VERSION ""

NS_ :

BS_:

BU_: ECM

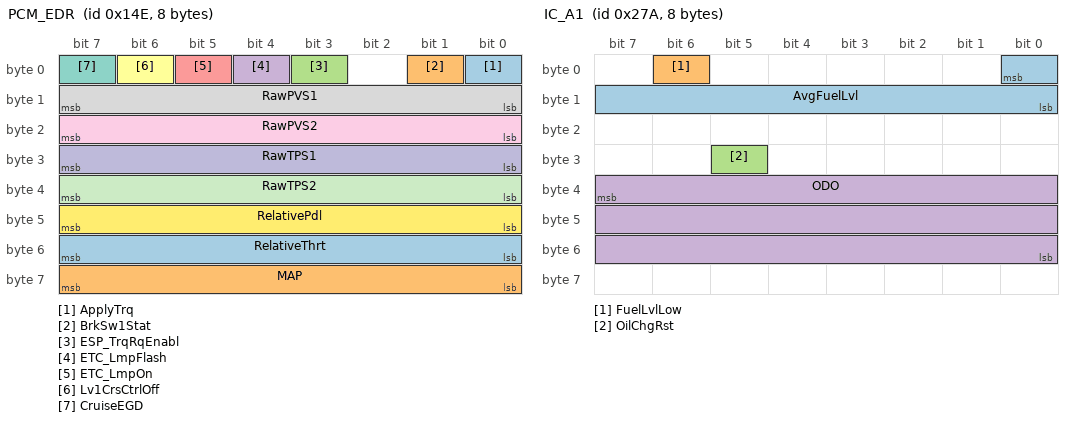
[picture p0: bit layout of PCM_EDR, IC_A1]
BO_ 334 PCM_EDR: 8 ECM
 SG_ ApplyTrq : 0|1@1+ (1,0) [0|0] "" Vector__XXX
 SG_ BrkSw1Stat : 1|1@1+ (1,0) [0|0] "" Vector__XXX
 SG_ ESP_TrqRqEnabl : 3|1@1+ (1,0) [0|0] "" Vector__XXX
 SG_ ETC_LmpFlash : 4|1@1+ (1,0) [0|0] "" Vector__XXX
 SG_ ETC_LmpOn : 5|1@1+ (1,0) [0|0] "" Vector__XXX
 SG_ Lv1CrsCtrlOff : 6|1@1+ (1,0) [0|0] "" Vector__XXX
 SG_ CruiseEGD : 7|1@1+ (1,0) [0|0] "" Vector__XXX
 SG_ RawPVS1 : 8|8@1+ (0.019607843,0) [0|4.98] "Volts"  Vector__XXX
 SG_ RawPVS2 : 16|8@1+ (0.019607843,0) [0|4.98] "Volts"  Vector__XXX
 SG_ RawTPS1 : 24|8@1+ (0.019607843,0) [0|4.98] "Volts"  Vector__XXX
 SG_ RawTPS2 : 32|8@1+ (0.019607843,0) [0|4.98] "Volts"  Vector__XXX
 SG_ RelativePdl : 40|8@1+ (0.019607843,0) [0|4.98] "Volts"  Vector__XXX
 SG_ RelativeThrt : 48|8@1+ (0.019607843,0) [0|4.98] "Volts"  Vector__XXX
 SG_ MAP : 56|8@1+ (0.8,0) [0|203.2] "kPa"  Vector__XXX

BO_ 43 ORC_YRS_DATA: 8 Vector__XXX
 SG_ LatAcceleration : 3|12@0+ (0.02,-40.96) [-40.96|40.92] "m/s²"  ECM
 SG_ LongAcceleration : 19|12@0+ (0.02,-40.96) [-40.96|40.92] "m/s²"  ECM

BO_ 673 IC_A3: 8 Vector__XXX
 SG_ SpeedUnit : 51|1@1+ (1,0) [0|0] "" ECM

BO_ 634 IC_A1: 8 Vector__XXX
 SG_ AvgFuelLvl : 0|9@0+ (0.5,0) [0|255] "liters"  ECM
 SG_ FuelLvlLow : 6|1@1+ (1,0) [0|0] "" ECM
 SG_ OilChgRst : 29|1@1+ (1,0) [0|0] "" ECM
 SG_ ODO : 39|24@0+ (0.1,0) [0|1677721.4] "km"  ECM

BO_ 503 IC_500Cyc: 8 Vector__XXX
 SG_ xtended_AvgFuelLvl : 19|12@0+ (0.5,0) [0|2047] "liters"  ECM

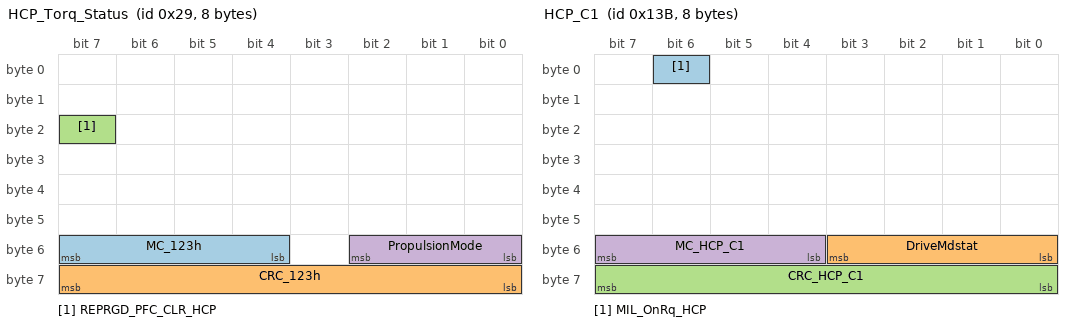
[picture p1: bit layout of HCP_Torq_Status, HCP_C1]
BO_ 41 HCP_Torq_Status: 8 Vector__XXX
 SG_ MC_123h : 52|4@1+ (1,0) [0|15] "" ECM
 SG_ CRC_123h : 56|8@1+ (1,0) [0|255] "" ECM
 SG_ REPRGD_PFC_CLR_HCP : 23|1@1+ (1,0) [0|0] "" ECM
 SG_ PropulsionMode : 48|3@1+ (1,0) [0|0] "" ECM

BO_ 315 HCP_C1: 8 Vector__XXX
 SG_ MIL_OnRq_HCP : 6|1@1+ (1,0) [0|0] "" ECM
 SG_ DriveMdstat : 48|4@1+ (1,0) [0|0] "" ECM
 SG_ CRC_HCP_C1 : 56|8@1+ (1,0) [0|0] "" ECM
 SG_ MC_HCP_C1 : 52|4@1+ (1,0) [0|15] "" ECM

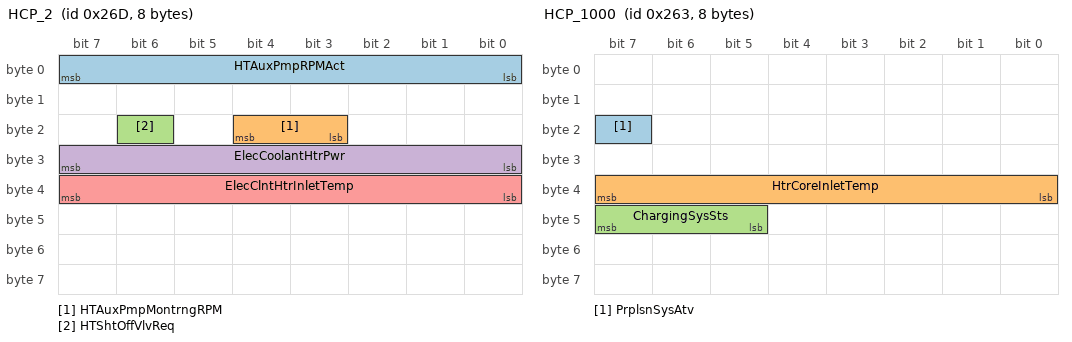
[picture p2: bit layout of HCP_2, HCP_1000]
BO_ 621 HCP_2: 8 Vector__XXX
 SG_ HTAuxPmpRPMAct : 0|8@1+ (24,0) [0|6096] "rpm"  ECM
 SG_ HTAuxPmpMontrngRPM : 19|2@1+ (1,0) [0|0] "" ECM
 SG_ HTShtOffVlvReq : 22|1@1+ (1,0) [0|0] "" ECM
 SG_ ElecCoolantHtrPwr : 24|8@1+ (0.04,0) [0|10.16] "kW"  ECM
 SG_ ElecClntHtrInletTemp : 32|8@1+ (1,-40) [-40|214] "°C"  ECM

BO_ 611 HCP_1000: 8 Vector__XXX
 SG_ PrplsnSysAtv : 23|1@1+ (1,0) [0|0] "" ECM
 SG_ HtrCoreInletTemp : 32|8@1+ (1,-40) [-40|214] "°C"  ECM
 SG_ ChargingSysSts : 45|3@1+ (1,0) [0|0] "" ECM

BO_ 663 GW_LIN_I_C1: 8 Vector__XXX
 SG_ SpSt_Pad1 : 50|3@1+ (1,0) [0|0] "" ECM
 SG_ SpSt_Pad2 : 53|3@1+ (1,0) [0|0] "" ECM

BO_ 649 GW_I_C1: 8 Vector__XXX
 SG_ HVAC_CLNT_FLW_MIN : 40|8@1+ (0.521555,0) [0.521555|131.953415] "LpM"  ECM

BO_ 689 GW_Dev: 5 Vector__XXX
 SG_ FT_HVAC_BLW_FN_SP : 0|7@1+ (1,0) [0|100] "Bars"  ECM
 SG_ DRV_TEMP_DR_POS : 16|7@1+ (1,0) [0|100] "%"  ECM

BO_ 327 ESP_B2: 8 Vector__XXX
 SG_ MIL_OnRq_ESC : 2|1@1+ (1,0) [0|0] "" ECM

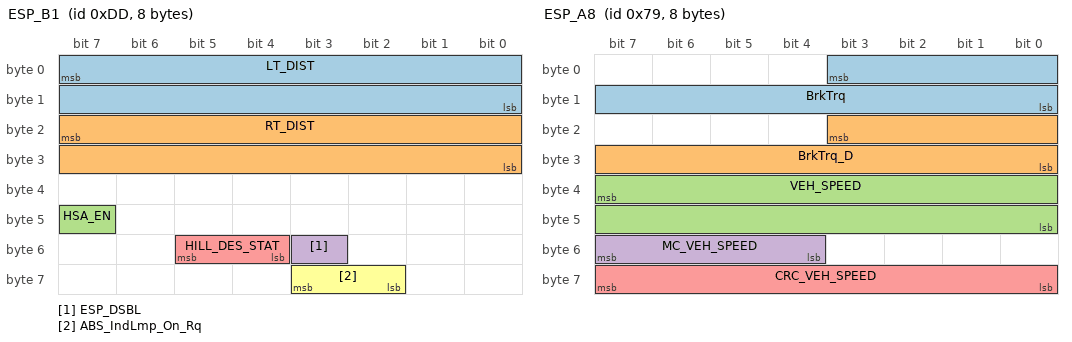
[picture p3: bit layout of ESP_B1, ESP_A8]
BO_ 221 ESP_B1: 8 Vector__XXX
 SG_ LT_DIST : 7|16@0+ (4,0) [0|262136] "cm"  ECM
 SG_ RT_DIST : 23|16@0+ (4,0) [0|262136] "cm"  ECM
 SG_ HSA_EN : 47|1@1+ (1,0) [0|0] "" ECM
 SG_ ESP_DSBL : 51|1@1+ (1,0) [0|0] "" ECM
 SG_ HILL_DES_STAT : 52|2@1+ (1,0) [0|0] "" ECM
 SG_ ABS_IndLmp_On_Rq : 58|2@1+ (1,0) [0|0] "" ECM

BO_ 121 ESP_A8: 8 Vector__XXX
 SG_ BrkTrq : 3|12@0+ (3,0) [0|12282] "Nm"  ECM
 SG_ BrkTrq_D : 19|12@0+ (3,0) [0|12282] "Nm"  ECM
 SG_ VEH_SPEED : 39|16@0+ (0.0078125,0) [0|511.984375] "km/h"  ECM
 SG_ MC_VEH_SPEED : 52|4@1+ (1,0) [0|15] "" ECM
 SG_ CRC_VEH_SPEED : 56|8@1+ (1,0) [0|0] "" ECM

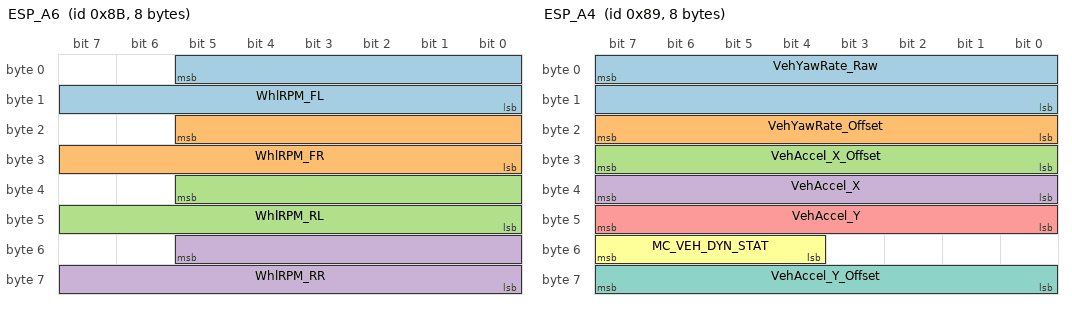
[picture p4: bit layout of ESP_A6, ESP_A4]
BO_ 139 ESP_A6: 8 Vector__XXX
 SG_ WhlRPM_FL : 5|14@0+ (0.5,0) [0|8191] "rpm"  ECM
 SG_ WhlRPM_FR : 21|14@0+ (0.5,0) [0|8191] "rpm"  ECM
 SG_ WhlRPM_RL : 37|14@0+ (0.5,0) [0|8191] "rpm"  ECM
 SG_ WhlRPM_RR : 53|14@0+ (0.5,0) [0|8191] "rpm"  ECM

BO_ 137 ESP_A4: 8 Vector__XXX
 SG_ VehYawRate_Raw : 7|16@0+ (0.01,-327.68) [-327.68|327.66] "°/s"  ECM
 SG_ VehYawRate_Offset : 16|8@1+ (0.08,-10.24) [-6.96|6.96] "" ECM
 SG_ VehAccel_X_Offset : 24|8@1+ (0.02,-2.56) [-2.56|2.52] "m/s²"  ECM
 SG_ VehAccel_X : 32|8@1+ (0.08,-10.24) [-10.24|10.08] "m/s²"  ECM
 SG_ VehAccel_Y : 40|8@1+ (0.08,-10.24) [-10.24|10.08] "m/s²"  ECM
 SG_ MC_VEH_DYN_STAT : 52|4@1+ (1,0) [0|15] "" ECM
 SG_ VehAccel_Y_Offset : 56|8@1+ (0.02,-2.56) [-2.56|2.52] "m/s²"  ECM

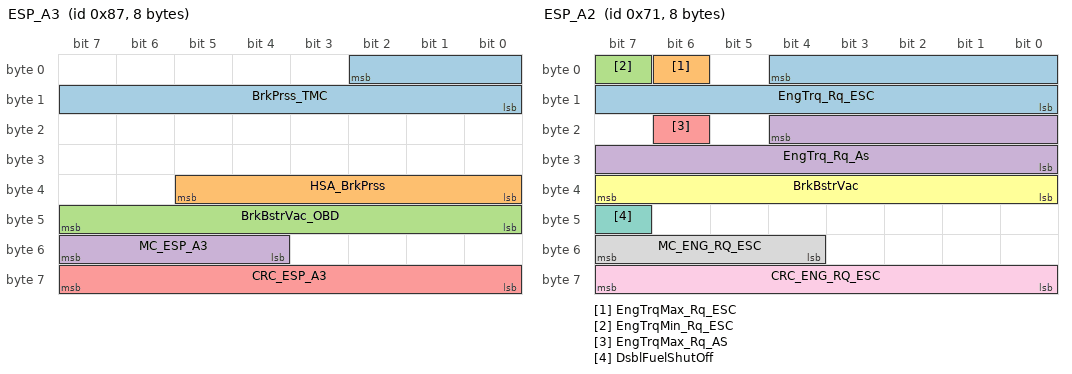
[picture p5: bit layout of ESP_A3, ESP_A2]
BO_ 135 ESP_A3: 8 Vector__XXX
 SG_ BrkPrss_TMC : 2|11@0+ (0.1,0) [0|200] "bar"  ECM
 SG_ HSA_BrkPrss : 32|6@1+ (1,0) [0|50] "bar"  ECM
 SG_ BrkBstrVac_OBD : 40|8@1+ (0.019607843,0) [0|5] "Volts"  ECM
 SG_ MC_ESP_A3 : 52|4@1+ (1,0) [0|15] "" ECM
 SG_ CRC_ESP_A3 : 56|8@1+ (1,0) [0|0] "" ECM

BO_ 113 ESP_A2: 8 Vector__XXX
 SG_ EngTrq_Rq_ESC : 4|13@0+ (0.25,-500) [-500|1547.5] "Nm"  ECM
 SG_ EngTrqMax_Rq_ESC : 6|1@1+ (1,0) [0|0] "" ECM
 SG_ EngTrqMin_Rq_ESC : 7|1@1+ (1,0) [0|0] "" ECM
 SG_ EngTrq_Rq_As : 20|13@0+ (0.25,-500) [-500|1547.5] "Nm"  ECM
 SG_ EngTrqMax_Rq_AS : 22|1@1+ (1,0) [0|0] "" ECM
 SG_ BrkBstrVac : 32|8@1+ (0.55,-119.7) [-119.7|20] "kPa"  ECM
 SG_ DsblFuelShutOff : 47|1@1+ (1,0) [0|0] "" ECM
 SG_ MC_ENG_RQ_ESC : 52|4@1+ (1,0) [0|15] "" ECM
 SG_ CRC_ENG_RQ_ESC : 56|8@1+ (1,0) [0|0] "" ECM

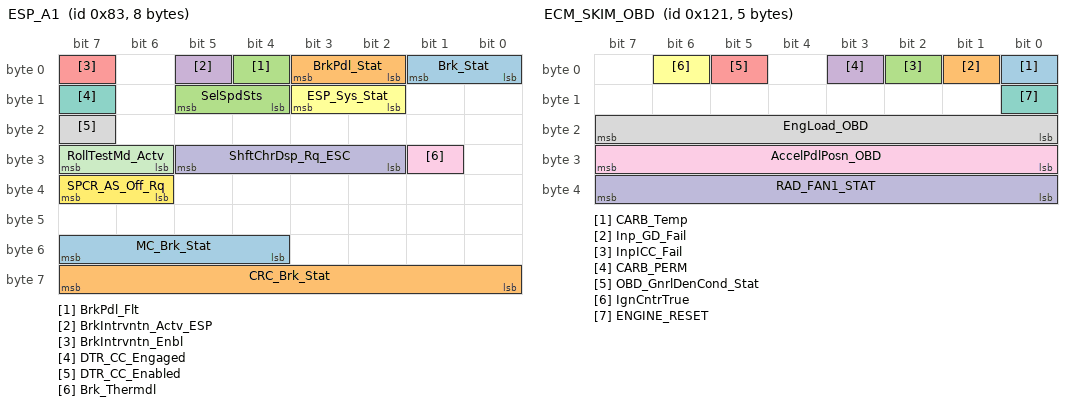
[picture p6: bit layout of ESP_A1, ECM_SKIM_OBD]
BO_ 131 ESP_A1: 8 Vector__XXX
 SG_ Brk_Stat : 0|2@1+ (1,0) [0|0] "" ECM
 SG_ BrkPdl_Stat : 2|2@1+ (1,0) [0|0] "" ECM
 SG_ BrkPdl_Flt : 4|1@1+ (1,0) [0|0] "" ECM
 SG_ BrkIntrvntn_Actv_ESP : 5|1@1+ (1,0) [0|0] "" ECM
 SG_ BrkIntrvntn_Enbl : 7|1@1+ (1,0) [0|0] "" ECM
 SG_ ESP_Sys_Stat : 10|2@1+ (1,0) [0|0] "" ECM
 SG_ DTR_CC_Engaged : 15|1@1+ (1,0) [0|0] "" ECM
 SG_ DTR_CC_Enabled : 23|1@1+ (1,0) [0|0] "" ECM
 SG_ Brk_Thermdl : 25|1@1+ (1,0) [0|0] "" ECM
 SG_ ShftChrDsp_Rq_ESC : 26|4@1+ (1,0) [0|0] "" ECM
 SG_ RollTestMd_Actv : 30|2@1+ (1,0) [0|0] "" ECM
 SG_ SPCR_AS_Off_Rq : 38|2@1+ (1,0) [0|0] "" ECM
 SG_ MC_Brk_Stat : 52|4@1+ (1,0) [0|15] "" ECM
 SG_ CRC_Brk_Stat : 56|8@1+ (1,0) [0|0] "" ECM
 SG_ SelSpdSts : 12|2@1+ (1,0) [0|0] "" ECM

BO_ 296 EPS_A1: 8 Vector__XXX
 SG_ EngineFanRequestActivation : 0|1@1+ (1,0) [0|0] "" ECM

BO_ 289 ECM_SKIM_OBD: 5 ECM
 SG_ CARB_Temp : 0|1@1+ (1,0) [0|0] "" Vector__XXX
 SG_ Inp_GD_Fail : 1|1@1+ (1,0) [0|0] "" Vector__XXX
 SG_ InpICC_Fail : 2|1@1+ (1,0) [0|0] "" Vector__XXX
 SG_ CARB_PERM : 3|1@1+ (1,0) [0|0] "" Vector__XXX
 SG_ OBD_GnrlDenCond_Stat : 5|1@1+ (1,0) [0|0] "" Vector__XXX
 SG_ IgnCntrTrue : 6|1@1+ (1,0) [0|0] "" Vector__XXX
 SG_ ENGINE_RESET : 8|1@1+ (1,0) [0|0] "" Vector__XXX
 SG_ EngLoad_OBD : 16|8@1+ (0.3922,0) [0|100] "%"  Vector__XXX
 SG_ AccelPdlPosn_OBD : 24|8@1+ (0.3922,0) [0|100] "%"  Vector__XXX
 SG_ RAD_FAN1_STAT : 32|8@1+ (1,0) [0|100] "%"  Vector__XXX

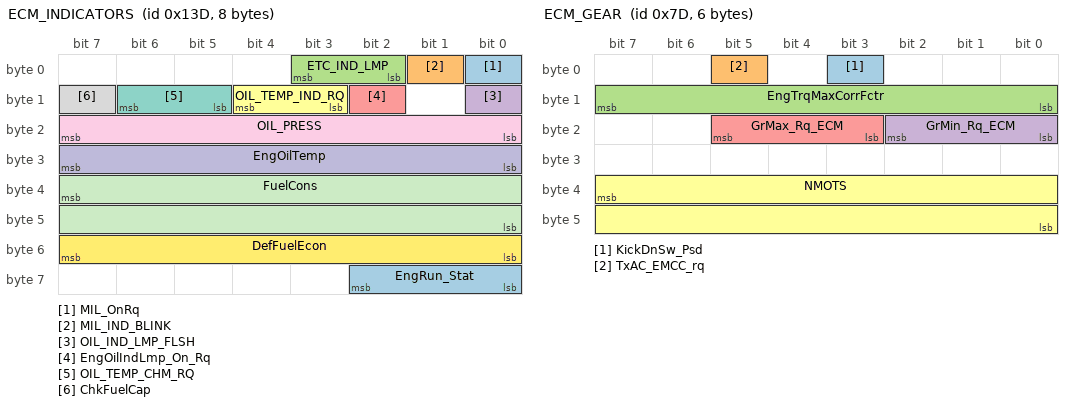
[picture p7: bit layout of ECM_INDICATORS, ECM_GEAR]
BO_ 317 ECM_INDICATORS: 8 ECM
 SG_ MIL_OnRq : 0|1@1+ (1,0) [0|0] "" Vector__XXX
 SG_ MIL_IND_BLINK : 1|1@1+ (1,0) [0|0] "" Vector__XXX
 SG_ ETC_IND_LMP : 2|2@1+ (1,0) [0|0] "" Vector__XXX
 SG_ OIL_IND_LMP_FLSH : 8|1@1+ (1,0) [0|0] "" Vector__XXX
 SG_ EngOilIndLmp_On_Rq : 10|1@1+ (1,0) [0|0] "" Vector__XXX
 SG_ OIL_TEMP_IND_RQ : 11|2@1+ (1,0) [0|0] "" Vector__XXX
 SG_ OIL_TEMP_CHM_RQ : 13|2@1+ (1,0) [0|0] "" Vector__XXX
 SG_ ChkFuelCap : 15|1@1+ (1,0) [0|0] "" Vector__XXX
 SG_ OIL_PRESS : 16|8@1+ (4,0) [0|1016] "kPaG"  Vector__XXX
 SG_ EngOilTemp : 24|8@1+ (1,-40) [-40|160] "°C"  Vector__XXX
 SG_ FuelCons : 39|16@0+ (0.21668,0) [0|14200] "µl/100ms"  Vector__XXX
 SG_ DefFuelEcon : 48|8@1+ (0.2,0) [0|50] "kmpl"  Vector__XXX
 SG_ EngRun_Stat : 56|3@1+ (1,0) [0|0] "" Vector__XXX

BO_ 125 ECM_GEAR: 6 ECM
 SG_ KickDnSw_Psd : 3|1@1+ (1,0) [0|0] "" Vector__XXX
 SG_ TxAC_EMCC_rq : 5|1@1+ (1,0) [0|0] "" Vector__XXX
 SG_ EngTrqMaxCorrFctr : 8|8@1+ (0.0078,0) [0|1.98] "Nm"  Vector__XXX
 SG_ GrMin_Rq_ECM : 16|3@1+ (1,0) [0|0] "" Vector__XXX
 SG_ GrMax_Rq_ECM : 19|3@1+ (1,0) [0|0] "" Vector__XXX
 SG_ NMOTS : 39|16@0+ (1,0) [0|65534] "rpm"  Vector__XXX

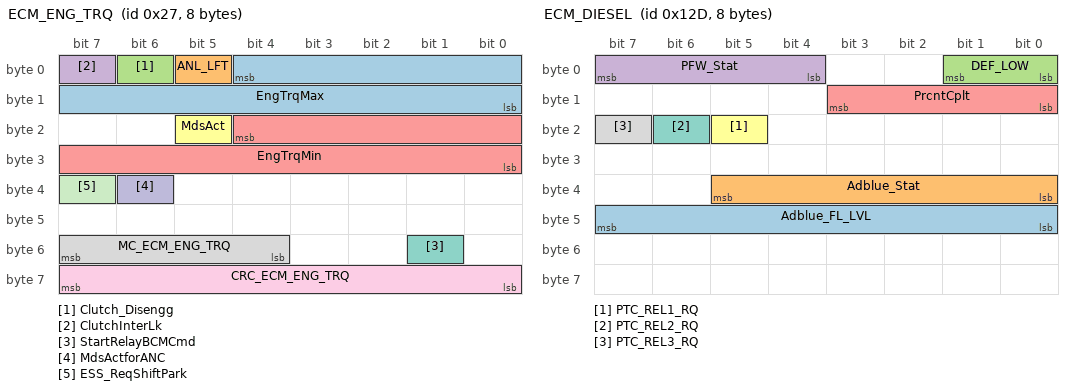
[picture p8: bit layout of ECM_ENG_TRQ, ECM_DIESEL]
BO_ 39 ECM_ENG_TRQ: 8 ECM
 SG_ EngTrqMax : 4|13@0+ (0.25,-500) [-500|1547.5] "Nm"  Vector__XXX
 SG_ ANL_LFT : 5|1@1+ (1,0) [0|0] "" Vector__XXX
 SG_ Clutch_Disengg : 6|1@1+ (1,0) [0|0] "" Vector__XXX
 SG_ ClutchInterLk : 7|1@1+ (1,0) [0|0] "" Vector__XXX
 SG_ EngTrqMin : 20|13@0+ (0.25,-500) [-500|1547.5] "Nm"  Vector__XXX
 SG_ MdsAct : 21|1@1+ (1,0) [0|0] "" Vector__XXX
 SG_ StartRelayBCMCmd : 49|1@1+ (1,0) [0|0] "" Vector__XXX
 SG_ MC_ECM_ENG_TRQ : 52|4@1+ (1,0) [0|15] "" Vector__XXX
 SG_ CRC_ECM_ENG_TRQ : 56|8@1+ (1,0) [0|0] "" Vector__XXX
 SG_ MdsActforANC : 38|1@1+ (1,0) [0|0] "" Vector__XXX
 SG_ ESS_ReqShiftPark : 39|1@1+ (1,0) [0|0] "" Vector__XXX

BO_ 301 ECM_DIESEL: 8 ECM
 SG_ Adblue_FL_LVL : 40|8@1+ (1,0) [0|100] "%"  Vector__XXX
 SG_ Adblue_Stat : 32|6@1+ (1,0) [0|0] "" Vector__XXX
 SG_ DEF_LOW : 0|2@1+ (1,0) [0|0] "" Vector__XXX
 SG_ PFW_Stat : 4|4@1+ (1,0) [0|0] "" Vector__XXX
 SG_ PrcntCplt : 8|4@1+ (10,0) [0|100] "%"  Vector__XXX
 SG_ PTC_REL1_RQ : 21|1@1+ (1,0) [0|0] "" Vector__XXX
 SG_ PTC_REL2_RQ : 22|1@1+ (1,0) [0|0] "" Vector__XXX
 SG_ PTC_REL3_RQ : 23|1@1+ (1,0) [0|0] "" Vector__XXX

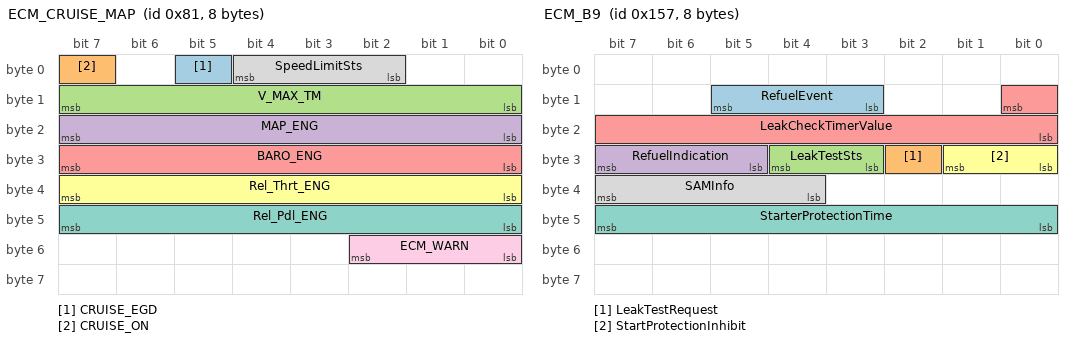
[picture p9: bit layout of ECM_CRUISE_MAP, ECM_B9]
BO_ 129 ECM_CRUISE_MAP: 8 ECM
 SG_ CRUISE_EGD : 5|1@1+ (1,0) [0|0] "" Vector__XXX
 SG_ CRUISE_ON : 7|1@1+ (1,0) [0|0] "" Vector__XXX
 SG_ V_MAX_TM : 8|8@1+ (1,0) [0|250] "km/h(mph)"  Vector__XXX
 SG_ MAP_ENG : 16|8@1+ (0.8,0) [0|203.2] "kPa"  Vector__XXX
 SG_ BARO_ENG : 24|8@1+ (1,0) [0|254] "kPaA"  Vector__XXX
 SG_ Rel_Thrt_ENG : 32|8@1+ (0.019607843,0) [0|4.98] "Volts"  Vector__XXX
 SG_ Rel_Pdl_ENG : 40|8@1+ (0.019607843,0) [0|4.98] "Volts"  Vector__XXX
 SG_ SpeedLimitSts : 2|3@1+ (1,0) [0|0] "" Vector__XXX
 SG_ ECM_WARN : 48|3@1+ (1,0) [0|0] "" Vector__XXX

BO_ 343 ECM_B9: 8 ECM
 SG_ RefuelEvent : 11|3@1+ (1,0) [0|0] "" Vector__XXX
 SG_ LeakTestRequest : 26|1@1+ (1,0) [0|0] "" Vector__XXX
 SG_ LeakTestSts : 27|2@1+ (1,0) [0|0] "" Vector__XXX
 SG_ RefuelIndication : 29|3@1+ (1,0) [0|0] "" Vector__XXX
 SG_ LeakCheckTimerValue : 8|9@0+ (1,0) [0|510] "min"  Vector__XXX
 SG_ StartProtectionInhibit : 24|2@1+ (1,0) [0|0] "" Vector__XXX
 SG_ StarterProtectionTime : 40|8@1+ (1,0) [0|254] "sec"  Vector__XXX
 SG_ SAMInfo : 36|4@1+ (1,0) [0|0] "" Vector__XXX

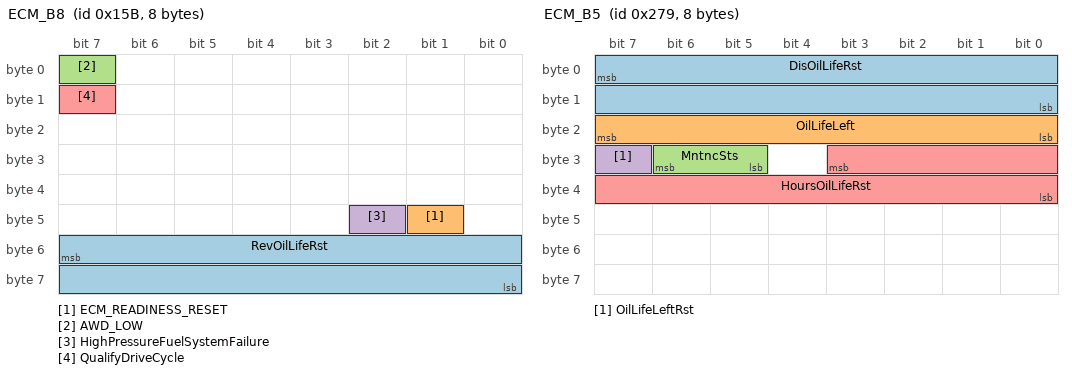
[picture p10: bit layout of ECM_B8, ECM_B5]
BO_ 347 ECM_B8: 8 ECM
 SG_ RevOilLifeRst : 55|16@0+ (1000,0) [0|65534000] "Rev's"  Vector__XXX
 SG_ ECM_READINESS_RESET : 41|1@1+ (1,0) [0|0] "" Vector__XXX
 SG_ AWD_LOW : 7|1@1+ (1,0) [0|0] "" Vector__XXX
 SG_ HighPressureFuelSystemFailure : 42|1@1+ (1,0) [0|0] "" Vector__XXX
 SG_ QualifyDriveCycle : 15|1@1+ (1,0) [0|0] "" Vector__XXX

BO_ 633 ECM_B5: 8 ECM
 SG_ DisOilLifeRst : 7|16@0+ (1,0) [0|65534] "km"  Vector__XXX
 SG_ OilLifeLeft : 16|8@1+ (1,0) [0|100] "%"  Vector__XXX
 SG_ MntncSts : 29|2@1+ (1,0) [0|0] "" Vector__XXX
 SG_ OilLifeLeftRst : 31|1@1+ (1,0) [0|0] "" Vector__XXX
 SG_ HoursOilLifeRst : 27|12@0+ (1,0) [0|4000] "Hours"  Vector__XXX

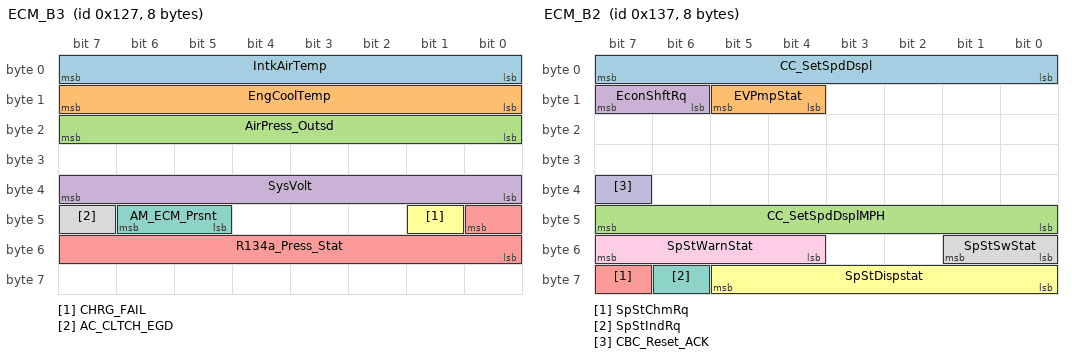
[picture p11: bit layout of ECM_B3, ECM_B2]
BO_ 295 ECM_B3: 8 ECM
 SG_ IntkAirTemp : 0|8@1+ (1,-40) [-40|214] "°C"  Vector__XXX
 SG_ EngCoolTemp : 8|8@1+ (1,-40) [-40|214] "°C"  Vector__XXX
 SG_ AirPress_Outsd : 16|8@1+ (1,0) [0|254] "kPaA"  Vector__XXX
 SG_ SysVolt : 32|8@1+ (0.0618,0) [0|15.6972] "Volts"  Vector__XXX
 SG_ R134a_Press_Stat : 40|9@0+ (0.1,0) [0|40] "bar"  Vector__XXX
 SG_ CHRG_FAIL : 41|1@1+ (1,0) [0|0] "" Vector__XXX
 SG_ AM_ECM_Prsnt : 45|2@1+ (1,0) [0|0] "" Vector__XXX
 SG_ AC_CLTCH_EGD : 47|1@1+ (1,0) [0|0] "" Vector__XXX

BO_ 311 ECM_B2: 8 ECM
 SG_ CC_SetSpdDspl : 0|8@1+ (1,0) [0|250] "km/h"  Vector__XXX
 SG_ EVPmpStat : 12|2@1+ (1,0) [0|0] "" Vector__XXX
 SG_ CC_SetSpdDsplMPH : 40|8@1+ (1,0) [0|254] "mph"  Vector__XXX
 SG_ EconShftRq : 14|2@1+ (1,0) [0|0] "" Vector__XXX
 SG_ SpStChmRq : 63|1@1+ (1,0) [0|0] "" Vector__XXX
 SG_ SpStDispstat : 56|6@1+ (1,0) [0|0] "" Vector__XXX
 SG_ SpStIndRq : 62|1@1+ (1,0) [0|0] "" Vector__XXX
 SG_ SpStSwStat : 48|2@1+ (1,0) [0|0] "" Vector__XXX
 SG_ SpStWarnStat : 52|4@1+ (1,0) [0|0] "" Vector__XXX
 SG_ CBC_Reset_ACK : 39|1@1+ (1,0) [0|0] "" Vector__XXX

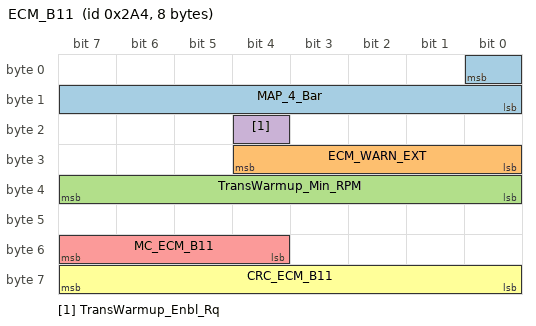
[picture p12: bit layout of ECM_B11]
BO_ 676 ECM_B11: 8 ECM
 SG_ MAP_4_Bar : 0|9@0+ (0.8,0) [0|408] "kPa"  Vector__XXX
 SG_ ECM_WARN_EXT : 24|5@1+ (1,0) [0|0] "" Vector__XXX
 SG_ TransWarmup_Min_RPM : 32|8@1+ (25,0) [0|6350] "rpm"  Vector__XXX
 SG_ TransWarmup_Enbl_Rq : 20|1@1+ (1,0) [0|0] "" Vector__XXX
 SG_ MC_ECM_B11 : 52|4@1+ (1,0) [0|15] "" Vector__XXX
 SG_ CRC_ECM_B11 : 56|8@1+ (1,0) [0|0] "" Vector__XXX

CM_ SG_ 689 DRV_TEMP_DR_POS "Driver temperature door postion";
CM_ SG_ 689 FT_HVAC_BLW_FN_SP "Front HVAC blower fan speed status in 'bars'";
CM_ SG_ 673 SpeedUnit "Speed (speedometer) units; Miles = [1]";
CM_ SG_ 663 SpSt_Pad2 "Stop / start switch - pad 2";
CM_ SG_ 663 SpSt_Pad1 "Stop / start switch - pad 1";
CM_ SG_ 649 HVAC_CLNT_FLW_MIN "HVAC coolant flow minimum request";
CM_ SG_ 634 ODO "Odometer";
CM_ SG_ 634 OilChgRst "Oil change reminder reset request";
CM_ SG_ 634 FuelLvlLow "Fuel level low";
CM_ SG_ 634 AvgFuelLvl "Average filtered fuel level in liters";
CM_ SG_ 621 ElecClntHtrInletTemp "Electric Coolant Heater Inlet Temperature";
CM_ SG_ 621 ElecCoolantHtrPwr "Electric Coolant Heater Power";
CM_ SG_ 621 HTShtOffVlvReq "High temp shut off valve request; [0] = Open, [1] = Closed";
CM_ SG_ 621 HTAuxPmpMontrngRPM "High Temp Aux Pump RPM monitoring active";
CM_ SG_ 621 HTAuxPmpRPMAct "High Temp Aux Pump Status";
CM_ SG_ 611 ChargingSysSts "Charging System status";
CM_ SG_ 611 HtrCoreInletTemp "Heater Core Inlet Temp";
CM_ SG_ 611 PrplsnSysAtv "Propulsion system active, [1] = active";
CM_ SG_ 503 xtended_AvgFuelLvl "Epanded average filtered fuel level in liters";
CM_ SG_ 327 MIL_OnRq_ESC "MIL on request from the ESC";
CM_ SG_ 315 MC_HCP_C1 "Message counter";
CM_ SG_ 315 CRC_HCP_C1 "CRC-checksum byte 1 to 7 according to SAE J1850";
CM_ SG_ 315 MIL_OnRq_HCP "MIL on request from the HCP";
CM_ SG_ 315 DriveMdstat "Drive mode select switch status";
CM_ SG_ 296 EngineFanRequestActivation "Engine fan activation request for cooling; True = [1]";
CM_ SG_ 221 ABS_IndLmp_On_Rq "ABS indication lamp on request";
CM_ SG_ 221 HILL_DES_STAT "Hill descent feature status";
CM_ SG_ 221 ESP_DSBL "ESP feature is completely disabled = [1]";
CM_ SG_ 221 HSA_EN "Hill Start Assist enabled (1=enabled)";
CM_ SG_ 221 RT_DIST "Distance Traveled by Right Wheel";
CM_ SG_ 221 LT_DIST "Distance Traveled by Left Wheel";
CM_ SG_ 139 WhlRPM_RR "Wheel rpm rear right";
CM_ SG_ 139 WhlRPM_RL "Wheel rpm rear left";
CM_ SG_ 139 WhlRPM_FR "Wheel rpm front right";
CM_ SG_ 139 WhlRPM_FL "Wheel rpm front left";
CM_ SG_ 137 VehAccel_Y_Offset "Offset of vehicle lateral acceleration (+ means left)";
CM_ SG_ 137 MC_VEH_DYN_STAT "Message counter";
CM_ SG_ 137 VehAccel_Y "Vehicle lateral acceleration (+ means left, specific to center of gravity, offset-corrected )";
CM_ SG_ 137 VehAccel_X "Vehicle longitudinal acceleration (+ means forward)";
CM_ SG_ 137 VehAccel_X_Offset "Offset of vehicle longitudinal acceleration (+ means forward)";
CM_ SG_ 137 VehYawRate_Offset "Offset of vehicle yaw rate unfiltered/unadjusted (+ means left)";
CM_ SG_ 137 VehYawRate_Raw "Vehicle yaw rate unfiltered/unadjusted (+ means left)";
CM_ SG_ 135 CRC_ESP_A3 "CRC-checksum byte 1 to 7 according to SAE J1850";
CM_ SG_ 135 MC_ESP_A3 "Message counter";
CM_ SG_ 135 BrkBstrVac_OBD "Brake booster vacuum level, raw";
CM_ SG_ 135 HSA_BrkPrss "Hill start assist brake pressure";
CM_ SG_ 135 BrkPrss_TMC "Master cylinder pressure";
CM_ SG_ 131 SPCR_AS_Off_Rq "Assistance system off request";
CM_ SG_ 131 RollTestMd_Actv "Roller test bench mode active";
CM_ SG_ 131 ShftChrDsp_Rq_ESC "Shift characteristic displacement request";
CM_ SG_ 131 Brk_Thermdl "Brake thermal over target";
CM_ SG_ 131 DTR_CC_Enabled "ACC is enabled; True = [1]";
CM_ SG_ 131 DTR_CC_Engaged "ACC is engaged; True = [1]";
CM_ SG_ 131 SelSpdSts "Select speed status";
CM_ SG_ 131 CRC_Brk_Stat "CRC-checksum byte 1 to 7 according to SAE J1850";
CM_ SG_ 131 MC_Brk_Stat "Message counter";
CM_ SG_ 131 ESP_Sys_Stat "ESP system state";
CM_ SG_ 131 BrkIntrvntn_Enbl "Brake intervention enabled";
CM_ SG_ 131 BrkIntrvntn_Actv_ESP "Brake intervention by ESP active";
CM_ SG_ 131 BrkPdl_Flt "Brake Pedal Fault is active, 1=Faulted";
CM_ SG_ 131 BrkPdl_Stat "Brake pedal state";
CM_ SG_ 131 Brk_Stat "Brake state";
CM_ SG_ 121 CRC_VEH_SPEED "CRC-checksum byte 1 to 7 according to SAE J1850";
CM_ SG_ 121 MC_VEH_SPEED "Message counter";
CM_ SG_ 121 VEH_SPEED "Vehicle speed";
CM_ SG_ 121 BrkTrq_D "Brake torque requested by driver";
CM_ SG_ 121 BrkTrq "Actual brake torque";
CM_ SG_ 113 CRC_ENG_RQ_ESC "CRC-checksum byte 1 to 7 according to SAE J1850";
CM_ SG_ 113 MC_ENG_RQ_ESC "Message counter";
CM_ SG_ 113 DsblFuelShutOff "Disable fuel shutoff; True = [1]";
CM_ SG_ 113 BrkBstrVac "Brake Booster Vacuum Level";
CM_ SG_ 113 EngTrqMax_Rq_AS "Engine torque request maximum; True = [1]";
CM_ SG_ 113 EngTrq_Rq_As "Engine torque request";
CM_ SG_ 113 EngTrqMin_Rq_ESC "Engine torque request minimum";
CM_ SG_ 113 EngTrqMax_Rq_ESC "Engine torque request maximum";
CM_ SG_ 113 EngTrq_Rq_ESC "Engine torque request";
CM_ SG_ 43 LongAcceleration "Raw longitudinal acceleration";
CM_ SG_ 43 LatAcceleration "Raw lateral acceleration";
CM_ SG_ 41 PropulsionMode "Propulsion mode of the vehicle";
CM_ SG_ 41 CRC_123h "CRC-checksum byte 1 to 7 according to SAE J1850";
CM_ SG_ 41 MC_123h "Message counter";
CM_ SG_ 41 REPRGD_PFC_CLR_HCP "Set readiness to 'incomplete'; 0 = Do nothing; 1= Set incomplete";
CM_ SG_ 676 CRC_ECM_B11 "CRC-Checksum Byte 1 - 7 according to SAE J1850";
CM_ SG_ 676 MC_ECM_B11 "Message counter";
CM_ SG_ 676 TransWarmup_Enbl_Rq "Enable and disable flag for transmission warm up feature, 0h = WarmUp_NOT_Enabled 1h = WarmUp_Enabled";
CM_ SG_ 676 TransWarmup_Min_RPM "Minimal engine rpm request for transmission warm up feature";
CM_ SG_ 676 ECM_WARN_EXT "HMI extended warnings";
CM_ SG_ 676 MAP_4_Bar "Engine manifold pressure (4 bar range)";
CM_ SG_ 311 SpStWarnStat "Stop start warning status";
CM_ SG_ 311 SpStSwStat "Stop start switch status";
CM_ SG_ 311 SpStIndRq "Stop start indicator request";
CM_ SG_ 311 SpStDispstat "Stop start display status";
CM_ SG_ 311 SpStChmRq "Stop start chime request";
CM_ SG_ 311 CBC_Reset_ACK "CBC reset acknowledge; True = [1]";
CM_ SG_ 311 EconShftRq "Economy transmission shift request";
CM_ SG_ 311 CC_SetSpdDsplMPH "Cruise control set speed for display in miles per hour";
CM_ SG_ 311 EVPmpStat "Electric vacuum pump status";
CM_ SG_ 311 CC_SetSpdDspl "Cruise control set speed for display (kmph only)";
CM_ SG_ 295 AC_CLTCH_EGD "AC clutch engauged";
CM_ SG_ 295 AM_ECM_Prsnt "Aftermarket ECM present";
CM_ SG_ 295 CHRG_FAIL "Charging system Failure (battery indicator request)";
CM_ SG_ 295 R134a_Press_Stat "Refrigerant pressure (R134a or R1234YF)";
CM_ SG_ 295 SysVolt "Engine system voltage";
CM_ SG_ 295 AirPress_Outsd "Ambient air pressure (barometric pressure)";
CM_ SG_ 295 EngCoolTemp "Engine coolant temperature";
CM_ SG_ 295 IntkAirTemp "Engine Intake Air Temperature";
CM_ SG_ 633 HoursOilLifeRst "Hours since last oil life reset";
CM_ SG_ 633 OilLifeLeftRst "Oil life remaining has been reset";
CM_ SG_ 633 MntncSts "Maintenance reminder status";
CM_ SG_ 633 OilLifeLeft "Oil life left";
CM_ SG_ 633 DisOilLifeRst "Distance since last oil life reset";
CM_ SG_ 347 QualifyDriveCycle "Qualifies the drive cycle for the propulsion system by determining PSA.";
CM_ SG_ 347 HighPressureFuelSystemFailure "High Pressure Fuel Pump (HPFP) system failure where torque is limited to the amount of available fuel from supply pump. 0 = No_Fault 1 = Fault";
CM_ SG_ 347 RevOilLifeRst "Engine revolutions since last oil life reset";
CM_ SG_ 347 AWD_LOW "AWD LOW status; 0 4LOW_Not_Active 1 4LOW_Active";
CM_ SG_ 347 ECM_READINESS_RESET "Handshake for not to send; 0 Not set 1 set";
CM_ SG_ 343 LeakTestSts "Status of leak test";
CM_ SG_ 343 LeakTestRequest "Leak test is requested after powerdown; No request = [0], Leak test requested = [1]";
CM_ SG_ 343 RefuelEvent "Status of refuel event";
CM_ SG_ 343 LeakCheckTimerValue "Requested leak test timer value";
CM_ SG_ 343 RefuelIndication "Indication to the driver about the status of the refuel system";
CM_ SG_ 343 SAMInfo "Logic status of the SAM strategy";
CM_ SG_ 343 StarterProtectionTime "Starter protection time";
CM_ SG_ 343 StartProtectionInhibit "Starter protection status";
CM_ SG_ 129 ECM_WARN "HMI warnings";
CM_ SG_ 129 SpeedLimitSts "Speed limiter status";
CM_ SG_ 129 Rel_Pdl_ENG "Relative pedal value";
CM_ SG_ 129 Rel_Thrt_ENG "Relative throttle value";
CM_ SG_ 129 BARO_ENG "Ambient air pressure (barometric pressure)";
CM_ SG_ 129 MAP_ENG "Intake manifold pressure, extended rangeEDR ONLY - Intake manifold pressure";
CM_ SG_ 129 V_MAX_TM "Max. or cruise control set speed";
CM_ SG_ 129 CRUISE_ON "Cruise control system 'on'";
CM_ SG_ 129 CRUISE_EGD "Cruise system is controlling speed";
CM_ SG_ 301 PTC_REL3_RQ "Activate PTC Relay # 3";
CM_ SG_ 301 PTC_REL2_RQ "Activate PTC Relay # 2";
CM_ SG_ 301 PTC_REL1_RQ "Activate PTC Relay # 1";
CM_ SG_ 301 PrcntCplt "Percent complete";
CM_ SG_ 301 PFW_Stat "Particulate filter warning status";
CM_ SG_ 301 DEF_LOW "DEF Low Indicator request";
CM_ SG_ 301 Adblue_Stat "Adblue status";
CM_ SG_ 301 Adblue_FL_LVL "Adblue fluid level";
CM_ SG_ 39 MdsActforANC "MDS active for ANC; Active = [1]";
CM_ SG_ 39 ESS_ReqShiftPark "ESS Request shift to Park.  1 = True, 0 = False";
CM_ SG_ 39 CRC_ECM_ENG_TRQ "CRC-checksum byte 1 to 7 according to SAE J1850";
CM_ SG_ 39 MC_ECM_ENG_TRQ "Message counter";
CM_ SG_ 39 StartRelayBCMCmd "Engine restart request for StopStart function";
CM_ SG_ 39 MdsAct "MDS Active";
CM_ SG_ 39 EngTrqMin "Minimum engine torque";
CM_ SG_ 39 ClutchInterLk "Clutch interlock switch, clutch depressed = [0]";
CM_ SG_ 39 Clutch_Disengg "Clutch upstop position:  Upstop=[0]; partial=[1]";
CM_ SG_ 39 ANL_LFT "Starter motor running (Cranking)";
CM_ SG_ 39 EngTrqMax "Maximum engine torque";
CM_ SG_ 125 NMOTS "Target idle speed";
CM_ SG_ 125 GrMax_Rq_ECM "Target gear upper limit (ECM requested limit)";
CM_ SG_ 125 GrMin_Rq_ECM "Target gear lower limit (ECM requested limit)";
CM_ SG_ 125 EngTrqMaxCorrFctr "Factor of reduction from max. torque";
CM_ SG_ 125 TxAC_EMCC_rq "Transmission  AC converter clutch slip request; [1] = True";
CM_ SG_ 125 KickDnSw_Psd "kick-down (change-over scenario open!)";
CM_ SG_ 317 DefFuelEcon "Default fuel economy";
CM_ SG_ 317 FuelCons "Fuel consumption";
CM_ SG_ 317 EngOilTemp "Oil temperature";
CM_ SG_ 317 OIL_PRESS "Oil pressure";
CM_ SG_ 317 ChkFuelCap "Check fuel cap";
CM_ SG_ 317 OIL_TEMP_CHM_RQ "Engine oil overtemp. chime request";
CM_ SG_ 317 EngRun_Stat "Engine running state";
CM_ SG_ 317 OIL_TEMP_IND_RQ "Engine oil overtemp. indicator request";
CM_ SG_ 317 EngOilIndLmp_On_Rq "Request oil level/oil pressure indicator lamp";
CM_ SG_ 317 OIL_IND_LMP_FLSH "Oil indicator lamp flash (for in plant use)";
CM_ SG_ 317 ETC_IND_LMP "ETC faulty, indicator lamp request";
CM_ SG_ 317 MIL_IND_BLINK "Request MIL blink (OBD II)";
CM_ SG_ 317 MIL_OnRq "MIL on request from the engine";
CM_ SG_ 289 RAD_FAN1_STAT "Low speed or single radiator fan requested duty cycle";
CM_ SG_ 289 AccelPdlPosn_OBD "Pedal value for OBD (ISO 15031-5.4 PID 49)";
CM_ SG_ 289 EngLoad_OBD "Load value for OBD (ISO 15031-5.4 PID 4)";
CM_ SG_ 289 ENGINE_RESET "ECM Reset Notification";
CM_ SG_ 289 IgnCntrTrue "Ignition cycle counter is true [1]";
CM_ SG_ 289 OBD_GnrlDenCond_Stat "General denominator conditions are met [1].";
CM_ SG_ 289 CARB_PERM "CARB permanent fault code drive cycle";
CM_ SG_ 289 InpICC_Fail "Inputs to the Ign Cycle Cntr are in a Pend or MIL cond.";
CM_ SG_ 289 Inp_GD_Fail "Inputs to the general denominator are in a pend or MIL fault.";
CM_ SG_ 289 CARB_Temp "CARB warmup criteria is true [1]";
CM_ SG_ 334 RelativePdl "EDR ONLY - Relative pedal value";
CM_ SG_ 334 RawTPS2 "EDR ONLY - Raw throttle position sensor #2";
CM_ SG_ 334 RawTPS1 "EDR ONLY - Raw throttle position sensor #1";
CM_ SG_ 334 RawPVS2 "EDR ONLY - Raw pedal value sensor #2";
CM_ SG_ 334 RawPVS1 "EDR ONLY - Raw pedal value sensor #1";
CM_ SG_ 334 CruiseEGD "EDR ONLY - Cruise system is engaged";
CM_ SG_ 334 MAP "EDR ONLY - Intake manifold pressure";
CM_ SG_ 334 RelativeThrt "EDR ONLY - Relative throttle value";
CM_ SG_ 334 Lv1CrsCtrlOff "EDR ONLY - Level is requested cruise off";
CM_ SG_ 334 ETC_LmpOn "EDR ONLY - ETC lamp is on";
CM_ SG_ 334 ETC_LmpFlash "EDR ONLY - ETC lamp is flashing";
CM_ SG_ 334 ESP_TrqRqEnabl "EDR ONLY - ESP torque requests are allowed = [1]";
CM_ SG_ 334 BrkSw1Stat "EDR ONLY - Brake switch1 status, off = [0]";
CM_ SG_ 334 ApplyTrq "EDR ONLY - Torque may be applied to the wheels";
BA_DEF_ SG_ "RID" STRING ;
BA_DEF_ SG_ "GenSigTimeout_TCM" INT 0 65535;
BA_DEF_ SG_ "GenSigTimeout_TBM" INT 0 65535;
BA_DEF_ SG_ "GenSigTimeout_SCCM" INT 0 65535;
BA_DEF_ SG_ "GenSigTimeout_RF_HUB" INT 0 65535;
BA_DEF_ SG_ "GenSigTimeout_PTS" INT 0 65535;
BA_DEF_ SG_ "GenSigTimeout_ORC" INT 0 65535;
BA_DEF_ SG_ "GenSigTimeout_OCM" INT 0 65535;
BA_DEF_ SG_ "GenSigTimeout_IC" INT 0 65535;
BA_DEF_ SG_ "GenSigTimeout_ETM" INT 0 65535;
BA_DEF_ SG_ "GenSigTimeout_ESM" INT 0 65535;
BA_DEF_ SG_ "GenSigTimeout_ESL" INT 0 65535;
BA_DEF_ SG_ "GenSigTimeout_ESC" INT 0 65535;
BA_DEF_ SG_ "GenSigTimeout_EHPS" INT 0 65535;
BA_DEF_ SG_ "GenSigTimeout_DTCM" INT 0 65535;
BA_DEF_ SG_ "GenSigTimeout_DPDM" INT 0 65535;
BA_DEF_ SG_ "GenSigTimeout_CBC" INT 0 65535;
BA_DEF_ SG_ "GenSigTimeout_ASBS" INT 0 65535;
BA_DEF_ SG_ "GenSigTimeout_AHLM" INT 0 65535;
BA_DEF_ SG_ "GenSigStartValue" HEX 0 2147483648;
BA_DEF_ SG_ "GenSigSNA" STRING ;
BA_DEF_ SG_ "GenSigSendType" ENUM "cyclicX","spontanX","cyclicIfActiveX","spontanWithDelay","cyclicAndSpontanX","cyclicAndSpontanWithDelay","spontanWithRepitition","cyclicIfActiveAndSpontanWD","cyclicIfActiveFast","cyclicWithRepeatOnDemand","none";
BA_DEF_ SG_ "GenSigCycleTimeActive" INT 0 65535;
BA_DEF_ SG_ "GenSigCycleTime" INT 0 65535;
BA_DEF_ SG_ "FlexKomSigStartValue" STRING ;
BA_DEF_ SG_ "FlexKomSigStartPos" INT 0 63;
BA_DEF_ SG_ "FlexKomSigName" STRING ;
BA_DEF_ SG_ "FlexKomSigLaenge" INT 0 64;
BA_DEF_ SG_ "FlexKomSID" INT 0 2147483647;
BA_DEF_ SG_ "FlexKomIsMotorola" ENUM "nein","ja";
BA_DEF_ SG_ "FlexKomComment" STRING ;
BA_DEF_ BO_ "TpTxIndex" INT 0 99;
BA_DEF_ BO_ "NWM-Botschaft" ENUM "nein","ja";
BA_DEF_ BO_ "GenMsgStartValue" STRING ;
BA_DEF_ BO_ "GenMsgStartDelayTime" INT 0 65535;
BA_DEF_ BO_ "GenMsgSendType" ENUM "cyclicX","spontanX","cyclicIfActiveX","spontanWithDelay","cyclicAndSpontanX","cyclicAndSpontanWithDelay","spontanWithRepitition","cyclicIfActiveAndSpontanWD","cyclicIfActiveFast","cyclicWithRepeatOnDemand","none";
BA_DEF_ BO_ "GenMsgNrOfRepetitions" INT 0 65535;
BA_DEF_ BO_ "GenMsgDelayTime" INT 0 65535;
BA_DEF_ BO_ "GenMsgCycleTimeActive" INT 0 65535;
BA_DEF_ BO_ "GenMsgCycleTime" INT 0 65535;
BA_DEF_ BO_ "DiagState" ENUM "nein","ja";
BA_DEF_ BO_ "DiagResponse" ENUM "nein","ja";
BA_DEF_ BO_ "DiagRequest" ENUM "nein","ja";
BA_DEF_ BO_ "CanMsgMinLen" INT 0 8;
BA_DEF_ BO_ "App-Botschaft" ENUM "nein","ja";
BA_DEF_DEF_ "RID" "";
BA_DEF_DEF_ "GenSigTimeout_TCM" 0;
BA_DEF_DEF_ "GenSigTimeout_TBM" 0;
BA_DEF_DEF_ "GenSigTimeout_SCCM" 0;
BA_DEF_DEF_ "GenSigTimeout_RF_HUB" 0;
BA_DEF_DEF_ "GenSigTimeout_PTS" 0;
BA_DEF_DEF_ "GenSigTimeout_ORC" 0;
BA_DEF_DEF_ "GenSigTimeout_OCM" 0;
BA_DEF_DEF_ "GenSigTimeout_IC" 0;
BA_DEF_DEF_ "GenSigTimeout_ETM" 0;
BA_DEF_DEF_ "GenSigTimeout_ESM" 0;
BA_DEF_DEF_ "GenSigTimeout_ESL" 0;
BA_DEF_DEF_ "GenSigTimeout_ESC" 0;
BA_DEF_DEF_ "GenSigTimeout_EHPS" 0;
BA_DEF_DEF_ "GenSigTimeout_DTCM" 0;
BA_DEF_DEF_ "GenSigTimeout_DPDM" 0;
BA_DEF_DEF_ "GenSigTimeout_CBC" 0;
BA_DEF_DEF_ "GenSigTimeout_ASBS" 0;
BA_DEF_DEF_ "GenSigTimeout_AHLM" 0;
BA_DEF_DEF_ "GenSigStartValue" 0;
BA_DEF_DEF_ "GenSigSNA" "";
BA_DEF_DEF_ "GenSigSendType" "cyclicX";
BA_DEF_DEF_ "GenSigCycleTimeActive" 0;
BA_DEF_DEF_ "GenSigCycleTime" 0;
BA_DEF_DEF_ "FlexKomSigStartValue" "";
BA_DEF_DEF_ "FlexKomSigStartPos" 0;
BA_DEF_DEF_ "FlexKomSigName" "";
BA_DEF_DEF_ "FlexKomSigLaenge" 0;
BA_DEF_DEF_ "FlexKomSID" 0;
BA_DEF_DEF_ "FlexKomIsMotorola" "nein";
BA_DEF_DEF_ "FlexKomComment" "";
BA_DEF_DEF_ "TpTxIndex" 0;
BA_DEF_DEF_ "NWM-Botschaft" "nein";
BA_DEF_DEF_ "GenMsgStartValue" "";
BA_DEF_DEF_ "GenMsgStartDelayTime" 0;
BA_DEF_DEF_ "GenMsgSendType" "cyclicX";
BA_DEF_DEF_ "GenMsgNrOfRepetitions" 0;
BA_DEF_DEF_ "GenMsgDelayTime" 0;
BA_DEF_DEF_ "GenMsgCycleTimeActive" 0;
BA_DEF_DEF_ "GenMsgCycleTime" 0;
BA_DEF_DEF_ "DiagState" "nein";
BA_DEF_DEF_ "DiagResponse" "nein";
BA_DEF_DEF_ "DiagRequest" "nein";
BA_DEF_DEF_ "CanMsgMinLen" 0;
BA_DEF_DEF_ "App-Botschaft" "nein";
BA_ "GenMsgNrOfRepetitions" BO_ 334 2;
BA_ "GenMsgDelayTime" BO_ 334 20;
BA_ "GenMsgCycleTime" BO_ 334 100;
BA_ "GenMsgStartValue" BO_ 334 "00FFFFFFFFFFFFFFh";
BA_ "GenMsgNrOfRepetitions" BO_ 43 2;
BA_ "GenMsgDelayTime" BO_ 43 20;
BA_ "GenMsgCycleTime" BO_ 43 10;
BA_ "GenMsgStartValue" BO_ 43 "000000000FFF00FFh";
BA_ "GenMsgSendType" BO_ 673 5;
BA_ "GenMsgNrOfRepetitions" BO_ 673 2;
BA_ "GenMsgDelayTime" BO_ 673 20;
BA_ "GenMsgCycleTime" BO_ 673 1000;
BA_ "GenMsgStartValue" BO_ 673 "00F8FCF001FE01FEh";
BA_ "GenMsgStartValue" BO_ 634 "01FF0000FFFFFF07h";
BA_ "GenMsgSendType" BO_ 634 5;
BA_ "GenMsgNrOfRepetitions" BO_ 634 2;
BA_ "GenMsgDelayTime" BO_ 634 20;
BA_ "GenMsgCycleTime" BO_ 634 1000;
BA_ "GenMsgDelayTime" BO_ 503 20;
BA_ "GenMsgCycleTime" BO_ 503 500;
BA_ "GenMsgStartValue" BO_ 503 "FFFF0FFF0000FFFFh";
BA_ "GenMsgNrOfRepetitions" BO_ 503 2;
BA_ "GenMsgStartValue" BO_ 41 "00000000000000FFh";
BA_ "GenMsgNrOfRepetitions" BO_ 41 2;
BA_ "GenMsgDelayTime" BO_ 41 20;
BA_ "GenMsgCycleTime" BO_ 41 10;
BA_ "GenMsgStartValue" BO_ 315 "00000000646400FFh";
BA_ "GenMsgNrOfRepetitions" BO_ 315 2;
BA_ "GenMsgDelayTime" BO_ 315 20;
BA_ "GenMsgCycleTime" BO_ 315 100;
BA_ "GenMsgSendType" BO_ 621 5;
BA_ "GenMsgNrOfRepetitions" BO_ 621 2;
BA_ "GenMsgDelayTime" BO_ 621 20;
BA_ "GenMsgStartValue" BO_ 621 "00001E0000000000h";
BA_ "GenMsgCycleTime" BO_ 621 1000;
BA_ "GenMsgStartValue" BO_ 611 "0000000000000000h";
BA_ "GenMsgSendType" BO_ 611 5;
BA_ "GenMsgNrOfRepetitions" BO_ 611 2;
BA_ "GenMsgDelayTime" BO_ 611 20;
BA_ "GenMsgCycleTime" BO_ 611 1000;
BA_ "GenMsgSendType" BO_ 663 5;
BA_ "GenMsgNrOfRepetitions" BO_ 663 2;
BA_ "GenMsgDelayTime" BO_ 663 20;
BA_ "GenMsgCycleTime" BO_ 663 1000;
BA_ "GenMsgStartValue" BO_ 663 "F0FF0300000C00FFh";
BA_ "GenMsgStartDelayTime" BO_ 663 100;
BA_ "GenMsgStartValue" BO_ 649 "3000071EC0FF8000h";
BA_ "GenMsgStartDelayTime" BO_ 649 80;
BA_ "GenMsgSendType" BO_ 649 5;
BA_ "GenMsgNrOfRepetitions" BO_ 649 2;
BA_ "GenMsgDelayTime" BO_ 649 20;
BA_ "GenMsgCycleTime" BO_ 649 1000;
BA_ "GenMsgStartValue" BO_ 689 "7F8FFFFF7Fh";
BA_ "GenMsgStartDelayTime" BO_ 689 70;
BA_ "GenMsgSendType" BO_ 689 5;
BA_ "GenMsgNrOfRepetitions" BO_ 689 2;
BA_ "GenMsgDelayTime" BO_ 689 20;
BA_ "GenMsgCycleTime" BO_ 689 1000;
BA_ "GenMsgStartValue" BO_ 327 "C1FE01FE00000000h";
BA_ "GenMsgNrOfRepetitions" BO_ 327 2;
BA_ "GenMsgDelayTime" BO_ 327 20;
BA_ "GenMsgCycleTime" BO_ 327 100;
BA_ "GenMsgStartValue" BO_ 221 "FFFFFFFF0000003Fh";
BA_ "GenMsgNrOfRepetitions" BO_ 221 2;
BA_ "GenMsgDelayTime" BO_ 221 20;
BA_ "GenMsgCycleTime" BO_ 221 50;
BA_ "GenMsgDelayTime" BO_ 121 20;
BA_ "GenMsgCycleTime" BO_ 121 20;
BA_ "GenMsgStartValue" BO_ 121 "0FFF0FFFFFFF00FFh";
BA_ "GenMsgNrOfRepetitions" BO_ 121 2;
BA_ "GenMsgDelayTime" BO_ 139 20;
BA_ "GenMsgCycleTime" BO_ 139 20;
BA_ "GenMsgStartValue" BO_ 139 "FFFFFFFFFFFFFFFFh";
BA_ "GenMsgNrOfRepetitions" BO_ 139 2;
BA_ "GenMsgNrOfRepetitions" BO_ 137 2;
BA_ "GenMsgDelayTime" BO_ 137 20;
BA_ "GenMsgCycleTime" BO_ 137 20;
BA_ "GenMsgStartValue" BO_ 137 "FFFFFFFFFFFF00FFh";
BA_ "GenMsgStartValue" BO_ 135 "7000FFFF00FF00FFh";
BA_ "GenMsgNrOfRepetitions" BO_ 135 2;
BA_ "GenMsgDelayTime" BO_ 135 20;
BA_ "GenMsgCycleTime" BO_ 135 20;
BA_ "GenMsgNrOfRepetitions" BO_ 113 2;
BA_ "GenMsgDelayTime" BO_ 113 20;
BA_ "GenMsgCycleTime" BO_ 113 20;
BA_ "GenMsgStartValue" BO_ 113 "00000000FF0000FFh";
BA_ "GenMsgNrOfRepetitions" BO_ 131 2;
BA_ "GenMsgDelayTime" BO_ 131 20;
BA_ "GenMsgCycleTime" BO_ 131 20;
BA_ "GenMsgStartValue" BO_ 131 "0F3400C003FF00FFh";
BA_ "GenMsgNrOfRepetitions" BO_ 296 2;
BA_ "GenMsgDelayTime" BO_ 296 20;
BA_ "GenMsgCycleTime" BO_ 296 100;
BA_ "GenMsgStartValue" BO_ 296 "0200FF0000000000h";
BA_ "GenMsgCycleTime" BO_ 289 100;
BA_ "GenMsgStartValue" BO_ 289 "0000000000h";
BA_ "GenMsgNrOfRepetitions" BO_ 289 2;
BA_ "GenMsgDelayTime" BO_ 289 20;
BA_ "GenMsgStartValue" BO_ 317 "6000FFFFFFFFFF07h";
BA_ "GenMsgNrOfRepetitions" BO_ 317 2;
BA_ "GenMsgDelayTime" BO_ 317 20;
BA_ "GenMsgCycleTime" BO_ 317 100;
BA_ "GenMsgStartValue" BO_ 125 "00FF000FFFFFh";
BA_ "GenMsgNrOfRepetitions" BO_ 125 2;
BA_ "GenMsgDelayTime" BO_ 125 20;
BA_ "GenMsgCycleTime" BO_ 125 20;
BA_ "GenMsgDelayTime" BO_ 39 20;
BA_ "GenMsgCycleTime" BO_ 39 10;
BA_ "GenMsgStartValue" BO_ 39 "9FFF1FFF1FFF00FFh";
BA_ "GenMsgNrOfRepetitions" BO_ 39 2;
BA_ "GenMsgStartValue" BO_ 301 "000F000000FF0000h";
BA_ "GenMsgNrOfRepetitions" BO_ 301 2;
BA_ "GenMsgDelayTime" BO_ 301 20;
BA_ "GenMsgCycleTime" BO_ 301 100;
BA_ "GenMsgStartValue" BO_ 129 "08FFFF00FFFF00FFh";
BA_ "GenMsgNrOfRepetitions" BO_ 129 2;
BA_ "GenMsgDelayTime" BO_ 129 20;
BA_ "GenMsgCycleTime" BO_ 129 20;
BA_ "GenMsgNrOfRepetitions" BO_ 343 2;
BA_ "GenMsgDelayTime" BO_ 343 20;
BA_ "GenMsgCycleTime" BO_ 343 100;
BA_ "GenMsgStartValue" BO_ 343 "00000000F00000FFh";
BA_ "GenMsgStartValue" BO_ 347 "000000000000FFFFh";
BA_ "GenMsgNrOfRepetitions" BO_ 347 2;
BA_ "GenMsgDelayTime" BO_ 347 20;
BA_ "GenMsgCycleTime" BO_ 347 100;
BA_ "GenMsgDelayTime" BO_ 633 20;
BA_ "GenMsgCycleTime" BO_ 633 1000;
BA_ "GenMsgStartValue" BO_ 633 "FFFFFF0FFF00FF00h";
BA_ "GenMsgNrOfRepetitions" BO_ 633 2;
BA_ "GenMsgStartValue" BO_ 295 "00FFFF000001FFFFh";
BA_ "GenMsgNrOfRepetitions" BO_ 295 2;
BA_ "GenMsgDelayTime" BO_ 295 20;
BA_ "GenMsgCycleTime" BO_ 295 100;
BA_ "GenMsgDelayTime" BO_ 311 20;
BA_ "GenMsgCycleTime" BO_ 311 100;
BA_ "GenMsgStartValue" BO_ 311 "FF00FFFF00FF0000h";
BA_ "GenMsgNrOfRepetitions" BO_ 311 2;
BA_ "GenMsgNrOfRepetitions" BO_ 676 2;
BA_ "GenMsgDelayTime" BO_ 676 20;
BA_ "GenMsgCycleTime" BO_ 676 100;
BA_ "GenMsgStartValue" BO_ 676 "01FF0700000000FFh";
BA_ "GenSigSNA" SG_ 621 HTShtOffVlvReq "0h";
BA_ "RID" SG_ 663 SpSt_Pad1 "1933";
BA_ "GenSigSNA" SG_ 663 SpSt_Pad1 "7h";
BA_ "GenSigSendType" SG_ 663 SpSt_Pad1 5;
BA_ "GenSigCycleTime" SG_ 663 SpSt_Pad1 1000;
BA_ "FlexKomSigStartValue" SG_ 663 SpSt_Pad1 "00h";
BA_ "FlexKomSigStartPos" SG_ 663 SpSt_Pad1 52;
BA_ "FlexKomSigName" SG_ 663 SpSt_Pad1 "SpSt_Pad1";
BA_ "FlexKomSigLaenge" SG_ 663 SpSt_Pad1 3;
BA_ "FlexKomSID" SG_ 663 SpSt_Pad1 1959;
BA_ "FlexKomIsMotorola" SG_ 663 SpSt_Pad1 1;
BA_ "FlexKomComment" SG_ 663 SpSt_Pad1 "Stop / start switch - pad 1";
BA_ "GenSigTimeout_IC" SG_ 301 PFW_Stat 1050;
BA_ "GenSigSNA" SG_ 301 PFW_Stat "Fh";
BA_ "GenSigCycleTime" SG_ 301 PFW_Stat 100;
BA_ "FlexKomSigStartValue" SG_ 301 PFW_Stat "000Fh";
BA_ "FlexKomSigStartPos" SG_ 301 PFW_Stat 7;
BA_ "FlexKomSigName" SG_ 301 PFW_Stat "DEF_DPF_Pkt";
BA_ "FlexKomSigLaenge" SG_ 301 PFW_Stat 16;
BA_ "FlexKomSID" SG_ 301 PFW_Stat 1726;
BA_ "FlexKomIsMotorola" SG_ 301 PFW_Stat 1;
BA_ "FlexKomComment" SG_ 301 PFW_Stat "Exhaust fuel and particulate filter packet";
BA_ "GenSigSNA" SG_ 301 PTC_REL2_RQ "0h";
BA_ "GenSigCycleTime" SG_ 301 PTC_REL2_RQ 100;
BA_ "FlexKomSigStartValue" SG_ 301 PTC_REL2_RQ "00h";
BA_ "FlexKomSigStartPos" SG_ 311 SpStDispstat 55;
BA_ "FlexKomSigName" SG_ 311 SpStDispstat "SpStPacket";
BA_ "FlexKomSigLaenge" SG_ 311 SpStDispstat 16;
BA_ "FlexKomSID" SG_ 311 SpStDispstat 1567;
BA_ "FlexKomIsMotorola" SG_ 311 SpStDispstat 1;
BA_ "FlexKomComment" SG_ 311 SpStDispstat "Stop start packet";
BA_ "GenSigTimeout_IC" SG_ 676 ECM_WARN_EXT 1050;
BA_ "GenSigSNA" SG_ 676 ECM_WARN_EXT "1Fh";
BA_ "GenSigCycleTime" SG_ 676 ECM_WARN_EXT 100;
BA_ "FlexKomSigStartValue" SG_ 676 ECM_WARN_EXT "00h";
BA_ "FlexKomSigStartPos" SG_ 676 ECM_WARN_EXT 28;
BA_ "FlexKomSigName" SG_ 676 ECM_WARN_EXT "ECM_WARN_EXT";
BA_ "FlexKomSigLaenge" SG_ 676 ECM_WARN_EXT 5;
BA_ "FlexKomSID" SG_ 676 ECM_WARN_EXT 2727;
BA_ "FlexKomIsMotorola" SG_ 676 ECM_WARN_EXT 1;
BA_ "FlexKomComment" SG_ 676 ECM_WARN_EXT "HMI extended warnings";
BA_ "RID" SG_ 611 PrplsnSysAtv "3065";
BA_ "GenSigTimeout_IC" SG_ 611 PrplsnSysAtv 10500;
BA_ "GenSigSNA" SG_ 611 PrplsnSysAtv "0h";
BA_ "GenSigSendType" SG_ 611 PrplsnSysAtv 5;
BA_ "GenSigCycleTime" SG_ 611 PrplsnSysAtv 1000;
BA_ "FlexKomSigStartValue" SG_ 611 PrplsnSysAtv "0000000000000000h";
BA_ "FlexKomSigStartPos" SG_ 611 PrplsnSysAtv 7;
BA_ "FlexKomSigName" SG_ 611 PrplsnSysAtv "HCP_1000";
BA_ "FlexKomSigLaenge" SG_ 611 PrplsnSysAtv 64;
BA_ "FlexKomSID" SG_ 611 PrplsnSysAtv 2373;
BA_ "FlexKomIsMotorola" SG_ 611 PrplsnSysAtv 1;
BA_ "FlexKomComment" SG_ 611 PrplsnSysAtv "HCP 1000ms packet";
BA_ "RID" SG_ 611 ChargingSysSts "6523";
BA_ "GenSigTimeout_IC" SG_ 611 ChargingSysSts 10500;
BA_ "GenSigTimeout_CBC" SG_ 611 ChargingSysSts 10500;
BA_ "GenSigSNA" SG_ 611 ChargingSysSts "7h";
BA_ "GenSigSendType" SG_ 611 ChargingSysSts 5;
BA_ "GenSigCycleTime" SG_ 611 ChargingSysSts 1000;
BA_ "FlexKomSigStartValue" SG_ 611 ChargingSysSts "0000000000000000h";
BA_ "FlexKomSigStartPos" SG_ 611 ChargingSysSts 7;
BA_ "FlexKomSigName" SG_ 611 ChargingSysSts "HCP_1000";
BA_ "GenSigSNA" SG_ 289 AccelPdlPosn_OBD "0h";
BA_ "GenSigCycleTime" SG_ 289 AccelPdlPosn_OBD 100;
BA_ "FlexKomSigStartValue" SG_ 289 AccelPdlPosn_OBD "00h";
BA_ "FlexKomSigStartPos" SG_ 289 AccelPdlPosn_OBD 31;
BA_ "FlexKomSigName" SG_ 289 AccelPdlPosn_OBD "AccelPdlPosn_OBD";
BA_ "FlexKomSigLaenge" SG_ 289 AccelPdlPosn_OBD 8;
BA_ "FlexKomSID" SG_ 289 AccelPdlPosn_OBD 1089;
BA_ "FlexKomIsMotorola" SG_ 289 AccelPdlPosn_OBD 1;
BA_ "FlexKomComment" SG_ 289 AccelPdlPosn_OBD "Pedal value for OBD (ISO 15031-5.4 PID 49)";
BA_ "GenSigTimeout_ORC" SG_ 317 MIL_IND_BLINK 350;
BA_ "GenSigTimeout_IC" SG_ 317 MIL_IND_BLINK 1050;
BA_ "GenSigSNA" SG_ 317 MIL_IND_BLINK "0h";
BA_ "GenSigCycleTime" SG_ 317 MIL_IND_BLINK 100;
BA_ "FlexKomSigStartValue" SG_ 317 MIL_IND_BLINK "00h";
BA_ "FlexKomSigStartPos" SG_ 317 MIL_IND_BLINK 1;
BA_ "FlexKomSigName" SG_ 317 MIL_IND_BLINK "MIL_IND_BLINK";
BA_ "FlexKomSigLaenge" SG_ 317 MIL_IND_BLINK 1;
BA_ "FlexKomSID" SG_ 317 MIL_IND_BLINK 713;
BA_ "FlexKomIsMotorola" SG_ 317 MIL_IND_BLINK 1;
BA_ "FlexKomComment" SG_ 317 MIL_IND_BLINK "Request MIL blink (OBD II)";
BA_ "RID" SG_ 317 EngOilIndLmp_On_Rq "6552";
BA_ "GenSigTimeout_TBM" SG_ 317 EngOilIndLmp_On_Rq 1050;
BA_ "GenSigTimeout_IC" SG_ 317 EngOilIndLmp_On_Rq 1050;
BA_ "GenSigTimeout_ETM" SG_ 317 EngOilIndLmp_On_Rq 1050;
BA_ "GenSigSNA" SG_ 317 EngOilIndLmp_On_Rq "1h";
BA_ "GenSigCycleTime" SG_ 317 EngOilIndLmp_On_Rq 100;
BA_ "FlexKomSigStartValue" SG_ 317 EngOilIndLmp_On_Rq "00h";
BA_ "FlexKomSigStartPos" SG_ 317 EngOilIndLmp_On_Rq 10;
BA_ "FlexKomSigName" SG_ 317 EngOilIndLmp_On_Rq "EngOilIndLmp_On_Rq";
BA_ "FlexKomSigLaenge" SG_ 317 EngOilIndLmp_On_Rq 1;
BA_ "FlexKomSID" SG_ 317 EngOilIndLmp_On_Rq 1080;
BA_ "FlexKomIsMotorola" SG_ 317 EngOilIndLmp_On_Rq 1;
BA_ "FlexKomComment" SG_ 317 EngOilIndLmp_On_Rq "Request oil level/oil pressure indicator lamp";
BA_ "GenSigTimeout_IC" SG_ 317 OIL_TEMP_CHM_RQ 1050;
BA_ "GenSigSNA" SG_ 317 OIL_TEMP_CHM_RQ "0h";
BA_ "GenSigCycleTime" SG_ 317 OIL_TEMP_CHM_RQ 100;
BA_ "FlexKomSigStartValue" SG_ 317 OIL_TEMP_CHM_RQ "00h";
BA_ "FlexKomSigStartPos" SG_ 317 OIL_TEMP_CHM_RQ 14;
BA_ "FlexKomSigName" SG_ 317 OIL_TEMP_CHM_RQ "OIL_TEMP_RQ";
BA_ "FlexKomSigLaenge" SG_ 317 OIL_TEMP_CHM_RQ 4;
BA_ "FlexKomSID" SG_ 317 OIL_TEMP_CHM_RQ 718;
BA_ "FlexKomIsMotorola" SG_ 317 OIL_TEMP_CHM_RQ 1;
BA_ "FlexKomComment" SG_ 317 OIL_TEMP_CHM_RQ "Engine oil overtemp. indicator/chime request";
BA_ "GenSigSNA" SG_ 125 TxAC_EMCC_rq "0h";
BA_ "GenSigCycleTime" SG_ 125 TxAC_EMCC_rq 20;
BA_ "FlexKomSigStartValue" SG_ 125 TxAC_EMCC_rq "00h";
BA_ "FlexKomSigStartPos" SG_ 125 TxAC_EMCC_rq 5;
BA_ "FlexKomSigName" SG_ 125 TxAC_EMCC_rq "TxAC_EMCC_rq";
BA_ "FlexKomSigLaenge" SG_ 125 TxAC_EMCC_rq 1;
BA_ "FlexKomSID" SG_ 125 TxAC_EMCC_rq 1240;
BA_ "FlexKomIsMotorola" SG_ 125 TxAC_EMCC_rq 1;
BA_ "FlexKomComment" SG_ 125 TxAC_EMCC_rq "Transmission  AC converter clutch slip request; [1";
BA_ "GenSigSNA" SG_ 125 GrMax_Rq_ECM "0h";
BA_ "GenSigCycleTime" SG_ 125 GrMax_Rq_ECM 20;
BA_ "FlexKomSigStartValue" SG_ 125 GrMax_Rq_ECM "00h";
BA_ "FlexKomSigStartPos" SG_ 125 GrMax_Rq_ECM 21;
BA_ "FlexKomSigName" SG_ 125 GrMax_Rq_ECM "ECM_Gear";
BA_ "FlexKomSigLaenge" SG_ 125 GrMax_Rq_ECM 6;
BA_ "FlexKomSID" SG_ 125 GrMax_Rq_ECM 1243;
BA_ "FlexKomIsMotorola" SG_ 125 GrMax_Rq_ECM 1;
BA_ "FlexKomComment" SG_ 125 GrMax_Rq_ECM "Target gear upper and lower limit";
BA_ "GenSigTimeout_CBC" SG_ 39 ANL_LFT 105;
BA_ "GenSigSNA" SG_ 39 ANL_LFT "0h";
BA_ "GenSigCycleTime" SG_ 39 ANL_LFT 10;
BA_ "FlexKomSigStartValue" SG_ 39 ANL_LFT "9FFF1FFF1FFF00FFh";
BA_ "FlexKomSigStartPos" SG_ 39 ANL_LFT 7;
BA_ "FlexKomSigName" SG_ 39 ANL_LFT "ECM_ENG_TRQ_Pkt";
BA_ "FlexKomSigLaenge" SG_ 39 ANL_LFT 64;
BA_ "FlexKomSID" SG_ 39 ANL_LFT 1853;
BA_ "FlexKomIsMotorola" SG_ 39 ANL_LFT 1;
BA_ "FlexKomComment" SG_ 39 ANL_LFT "ECM_ENG_TRQ packet";
BA_ "GenSigTimeout_IC" SG_ 39 EngTrqMin 105;
BA_ "GenSigStartValue" SG_ 39 EngTrqMin 8191;
BA_ "GenSigSNA" SG_ 39 EngTrqMin "1FFFh";
BA_ "GenSigCycleTime" SG_ 39 EngTrqMin 10;
BA_ "FlexKomSigStartValue" SG_ 39 EngTrqMin "9FFF1FFF1FFF00FFh";
BA_ "FlexKomSigStartPos" SG_ 39 EngTrqMin 7;
BA_ "FlexKomSigName" SG_ 39 EngTrqMin "ECM_ENG_TRQ_Pkt";
BA_ "FlexKomSigLaenge" SG_ 39 EngTrqMin 64;
BA_ "FlexKomSID" SG_ 39 EngTrqMin 1853;
BA_ "FlexKomIsMotorola" SG_ 39 EngTrqMin 1;
BA_ "FlexKomComment" SG_ 39 EngTrqMin "ECM_ENG_TRQ packet";
BA_ "GenSigSendType" SG_ 621 HTShtOffVlvReq 5;
BA_ "GenSigCycleTime" SG_ 621 HTShtOffVlvReq 1000;
BA_ "FlexKomSigStartValue" SG_ 621 HTShtOffVlvReq "00001E000001FF00h";
BA_ "FlexKomSigStartPos" SG_ 621 HTShtOffVlvReq 7;
BA_ "FlexKomSigName" SG_ 621 HTShtOffVlvReq "HCP_2";
BA_ "FlexKomSigLaenge" SG_ 621 HTShtOffVlvReq 64;
BA_ "FlexKomSID" SG_ 621 HTShtOffVlvReq 2512;
BA_ "FlexKomIsMotorola" SG_ 621 HTShtOffVlvReq 1;
BA_ "FlexKomComment" SG_ 621 HTShtOffVlvReq "HCP message 2 packet";
BA_ "GenSigSNA" SG_ 289 OBD_GnrlDenCond_Stat "0h";
BA_ "GenSigCycleTime" SG_ 289 OBD_GnrlDenCond_Stat 100;
BA_ "FlexKomSigStartValue" SG_ 289 OBD_GnrlDenCond_Stat "00h";
BA_ "FlexKomSigStartPos" SG_ 289 OBD_GnrlDenCond_Stat 5;
BA_ "FlexKomSigName" SG_ 289 OBD_GnrlDenCond_Stat "OBD_GnrlDenCond_Stat";
BA_ "FlexKomSigLaenge" SG_ 289 OBD_GnrlDenCond_Stat 1;
BA_ "FlexKomSID" SG_ 289 OBD_GnrlDenCond_Stat 1256;
BA_ "FlexKomIsMotorola" SG_ 289 OBD_GnrlDenCond_Stat 1;
BA_ "FlexKomComment" SG_ 289 OBD_GnrlDenCond_Stat "General denominator conditions are met [1].";
BA_ "GenSigCycleTime" SG_ 113 EngTrqMin_Rq_ESC 20;
BA_ "FlexKomSigStartValue" SG_ 113 EngTrqMin_Rq_ESC "00000000FF0000FFh";
BA_ "FlexKomSigStartPos" SG_ 113 EngTrqMin_Rq_ESC 7;
BA_ "FlexKomSigName" SG_ 113 EngTrqMin_Rq_ESC "Eng_Trq_Rq";
BA_ "FlexKomSigLaenge" SG_ 113 EngTrqMin_Rq_ESC 64;
BA_ "FlexKomSID" SG_ 113 EngTrqMin_Rq_ESC 1;
BA_ "FlexKomIsMotorola" SG_ 113 EngTrqMin_Rq_ESC 1;
BA_ "FlexKomComment" SG_ 113 EngTrqMin_Rq_ESC "Engine torque request from ESC";
BA_ "GenSigSNA" SG_ 113 MC_ENG_RQ_ESC "0h";
BA_ "GenSigCycleTime" SG_ 113 MC_ENG_RQ_ESC 20;
BA_ "FlexKomSigStartValue" SG_ 113 MC_ENG_RQ_ESC "00000000FF0000FFh";
BA_ "FlexKomSigStartPos" SG_ 113 MC_ENG_RQ_ESC 7;
BA_ "FlexKomSigName" SG_ 113 MC_ENG_RQ_ESC "Eng_Trq_Rq";
BA_ "FlexKomSigLaenge" SG_ 113 MC_ENG_RQ_ESC 64;
BA_ "FlexKomSID" SG_ 113 MC_ENG_RQ_ESC 1;
BA_ "FlexKomIsMotorola" SG_ 113 MC_ENG_RQ_ESC 1;
BA_ "FlexKomComment" SG_ 113 MC_ENG_RQ_ESC "Engine torque request from ESC";
BA_ "GenSigTimeout_ORC" SG_ 113 BrkBstrVac 70;
BA_ "GenSigStartValue" SG_ 113 BrkBstrVac 255;
BA_ "GenSigSNA" SG_ 113 BrkBstrVac "FFh";
BA_ "GenSigCycleTime" SG_ 113 BrkBstrVac 20;
BA_ "FlexKomSigStartValue" SG_ 113 BrkBstrVac "00000000FF0000FFh";
BA_ "FlexKomSigStartPos" SG_ 113 BrkBstrVac 7;
BA_ "FlexKomSigName" SG_ 113 BrkBstrVac "Eng_Trq_Rq";
BA_ "FlexKomSigLaenge" SG_ 113 BrkBstrVac 64;
BA_ "FlexKomSID" SG_ 113 BrkBstrVac 1;
BA_ "FlexKomIsMotorola" SG_ 113 BrkBstrVac 1;
BA_ "FlexKomComment" SG_ 113 BrkBstrVac "Engine torque request from ESC";
BA_ "RID" SG_ 131 Brk_Stat "1226";
BA_ "GenSigTimeout_ORC" SG_ 131 Brk_Stat 70;
BA_ "GenSigTimeout_CBC" SG_ 131 Brk_Stat 210;
BA_ "GenSigStartValue" SG_ 131 Brk_Stat 3;
BA_ "GenSigSNA" SG_ 131 Brk_Stat "3h";
BA_ "GenSigCycleTime" SG_ 131 Brk_Stat 20;
BA_ "FlexKomSigStartValue" SG_ 131 Brk_Stat "0F3400C003FF00FFh";
BA_ "FlexKomSigStartPos" SG_ 131 Brk_Stat 7;
BA_ "FlexKomSigName" SG_ 131 Brk_Stat "ESP_BRK_STAT";
BA_ "FlexKomSigLaenge" SG_ 131 Brk_Stat 64;
BA_ "FlexKomIsMotorola" SG_ 131 Brk_Stat 1;
BA_ "FlexKomComment" SG_ 131 Brk_Stat "ESP Brake Status Information";
BA_ "GenSigTimeout_IC" SG_ 633 OilLifeLeftRst 10500;
BA_ "GenSigTimeout_ETM" SG_ 633 OilLifeLeftRst 10500;
BA_ "GenSigSNA" SG_ 633 OilLifeLeftRst "0h";
BA_ "GenSigCycleTime" SG_ 633 OilLifeLeftRst 1000;
BA_ "FlexKomSigStartValue" SG_ 633 OilLifeLeftRst "FFFFFF0FFFh";
BA_ "FlexKomSigStartPos" SG_ 633 OilLifeLeftRst 7;
BA_ "FlexKomSigName" SG_ 633 OilLifeLeftRst "OilLifePkt";
BA_ "FlexKomSigLaenge" SG_ 633 OilLifeLeftRst 40;
BA_ "FlexKomSID" SG_ 633 OilLifeLeftRst 1668;
BA_ "FlexKomIsMotorola" SG_ 633 OilLifeLeftRst 1;
BA_ "FlexKomComment" SG_ 633 OilLifeLeftRst "Oil life packet";
BA_ "RID" SG_ 295 IntkAirTemp "1149";
BA_ "GenSigTimeout_IC" SG_ 295 IntkAirTemp 1050;
BA_ "GenSigTimeout_ETM" SG_ 295 IntkAirTemp 1050;
BA_ "GenSigSNA" SG_ 295 IntkAirTemp "FFh";
BA_ "GenSigCycleTime" SG_ 295 IntkAirTemp 100;
BA_ "FlexKomSigStartValue" SG_ 295 IntkAirTemp "00h";
BA_ "FlexKomSigStartPos" SG_ 295 IntkAirTemp 7;
BA_ "FlexKomSigName" SG_ 295 IntkAirTemp "IntkAirTemp";
BA_ "FlexKomSigLaenge" SG_ 295 IntkAirTemp 8;
BA_ "FlexKomSID" SG_ 295 IntkAirTemp 441;
BA_ "FlexKomIsMotorola" SG_ 295 IntkAirTemp 1;
BA_ "FlexKomComment" SG_ 295 IntkAirTemp "Engine Intake Air Temperature";
BA_ "GenSigSendType" SG_ 673 SpeedUnit 5;
BA_ "GenSigCycleTime" SG_ 673 SpeedUnit 1000;
BA_ "FlexKomSigStartValue" SG_ 673 SpeedUnit "00h";
BA_ "FlexKomSigStartPos" SG_ 673 SpeedUnit 51;
BA_ "FlexKomSigName" SG_ 673 SpeedUnit "SpeedUnit";
BA_ "FlexKomSigLaenge" SG_ 673 SpeedUnit 1;
BA_ "FlexKomSID" SG_ 673 SpeedUnit 2004;
BA_ "FlexKomIsMotorola" SG_ 673 SpeedUnit 1;
BA_ "FlexKomComment" SG_ 673 SpeedUnit "Speed (speedometer) units; Miles = [1]";
BA_ "GenSigTimeout_CBC" SG_ 634 FuelLvlLow 10500;
BA_ "GenSigSNA" SG_ 634 FuelLvlLow "0h";
BA_ "GenSigSendType" SG_ 634 FuelLvlLow 5;
BA_ "GenSigCycleTime" SG_ 634 FuelLvlLow 1000;
BA_ "FlexKomSigStartValue" SG_ 634 FuelLvlLow "00h";
BA_ "FlexKomSigStartPos" SG_ 634 FuelLvlLow 6;
BA_ "FlexKomSigName" SG_ 634 FuelLvlLow "FuelLvlLow";
BA_ "FlexKomSigLaenge" SG_ 634 FuelLvlLow 1;
BA_ "FlexKomSID" SG_ 634 FuelLvlLow 1049;
BA_ "FlexKomIsMotorola" SG_ 634 FuelLvlLow 1;
BA_ "FlexKomComment" SG_ 634 FuelLvlLow "Fuel level low";
BA_ "GenSigSNA" SG_ 41 MC_123h "0h";
BA_ "GenSigCycleTime" SG_ 41 MC_123h 10;
BA_ "FlexKomSigStartValue" SG_ 41 MC_123h "00000000000000FFh";
BA_ "FlexKomSigStartPos" SG_ 41 MC_123h 7;
BA_ "FlexKomSigName" SG_ 41 MC_123h "HCP_Torq_Status";
BA_ "FlexKomSigLaenge" SG_ 41 MC_123h 64;
BA_ "FlexKomSID" SG_ 41 MC_123h 2222;
BA_ "FlexKomIsMotorola" SG_ 41 MC_123h 1;
BA_ "FlexKomComment" SG_ 41 MC_123h ".";
BA_ "GenSigTimeout_IC" SG_ 221 HILL_DES_STAT 525;
BA_ "GenSigSNA" SG_ 221 HILL_DES_STAT "0h";
BA_ "GenSigCycleTime" SG_ 221 HILL_DES_STAT 50;
BA_ "FlexKomSigStartValue" SG_ 221 HILL_DES_STAT "003Fh";
BA_ "FlexKomSigStartPos" SG_ 221 HILL_DES_STAT 55;
BA_ "FlexKomSigName" SG_ 221 HILL_DES_STAT "ESP_HMI";
BA_ "FlexKomSigLaenge" SG_ 221 HILL_DES_STAT 16;
BA_ "FlexKomSID" SG_ 221 HILL_DES_STAT 397;
BA_ "FlexKomIsMotorola" SG_ 221 HILL_DES_STAT 1;
BA_ "FlexKomComment" SG_ 221 HILL_DES_STAT "ESP Customer Indicators";
BA_ "GenSigTimeout_ESM" SG_ 121 BrkTrq 210;
BA_ "GenSigTimeout_CBC" SG_ 121 BrkTrq 210;
BA_ "GenSigStartValue" SG_ 121 BrkTrq 4095;
BA_ "GenSigSNA" SG_ 121 BrkTrq "FFFh";
BA_ "GenSigCycleTime" SG_ 121 BrkTrq 20;
BA_ "FlexKomSigStartValue" SG_ 121 BrkTrq "0FFF0FFFFFFF00FFh";
BA_ "FlexKomSigStartPos" SG_ 121 BrkTrq 7;
BA_ "FlexKomSigName" SG_ 121 BrkTrq "VEH_SPEED_PKT";
BA_ "FlexKomSigLaenge" SG_ 121 BrkTrq 64;
BA_ "FlexKomSID" SG_ 121 BrkTrq 11;
BA_ "FlexKomIsMotorola" SG_ 121 BrkTrq 1;
BA_ "FlexKomComment" SG_ 121 BrkTrq "Vehicle Speed Packet";
BA_ "RID" SG_ 121 VEH_SPEED "2861 2862 2863";
BA_ "GenSigTimeout_TCM" SG_ 121 VEH_SPEED 210;
BA_ "GenSigTimeout_RF_HUB" SG_ 121 VEH_SPEED 210;
BA_ "GenSigTimeout_ORC" SG_ 121 VEH_SPEED 70;
BA_ "GenSigTimeout_IC" SG_ 121 VEH_SPEED 210;
BA_ "GenSigTimeout_ESM" SG_ 121 VEH_SPEED 210;
BA_ "GenSigTimeout_ESL" SG_ 121 VEH_SPEED 110;
BA_ "GenSigTimeout_EHPS" SG_ 121 VEH_SPEED 210;
BA_ "GenSigTimeout_DTCM" SG_ 121 VEH_SPEED 210;
BA_ "GenSigTimeout_CBC" SG_ 121 VEH_SPEED 110;
BA_ "GenSigStartValue" SG_ 121 VEH_SPEED 65535;
BA_ "GenSigSNA" SG_ 121 VEH_SPEED "FFFFh";
BA_ "GenSigCycleTime" SG_ 121 VEH_SPEED 20;
BA_ "FlexKomSigStartValue" SG_ 121 VEH_SPEED "0FFF0FFFFFFF00FFh";
BA_ "FlexKomSigStartPos" SG_ 121 VEH_SPEED 7;
BA_ "FlexKomSigName" SG_ 121 VEH_SPEED "VEH_SPEED_PKT";
BA_ "FlexKomSigLaenge" SG_ 121 VEH_SPEED 64;
BA_ "FlexKomSID" SG_ 121 VEH_SPEED 11;
BA_ "FlexKomIsMotorola" SG_ 121 VEH_SPEED 1;
BA_ "FlexKomComment" SG_ 121 VEH_SPEED "Vehicle Speed Packet";
BA_ "GenSigSNA" SG_ 39 StartRelayBCMCmd "0h";
BA_ "GenSigCycleTime" SG_ 39 StartRelayBCMCmd 10;
BA_ "FlexKomSigStartValue" SG_ 39 StartRelayBCMCmd "9FFF1FFF1FFF00FFh";
BA_ "FlexKomSigStartPos" SG_ 39 StartRelayBCMCmd 7;
BA_ "FlexKomSigName" SG_ 39 StartRelayBCMCmd "ECM_ENG_TRQ_Pkt";
BA_ "FlexKomSigLaenge" SG_ 39 StartRelayBCMCmd 64;
BA_ "FlexKomSID" SG_ 39 StartRelayBCMCmd 1853;
BA_ "FlexKomIsMotorola" SG_ 39 StartRelayBCMCmd 1;
BA_ "FlexKomComment" SG_ 39 StartRelayBCMCmd "ECM_ENG_TRQ packet";
BA_ "GenSigSNA" SG_ 39 ESS_ReqShiftPark "0h";
BA_ "GenSigCycleTime" SG_ 39 ESS_ReqShiftPark 10;
BA_ "FlexKomSigStartValue" SG_ 39 ESS_ReqShiftPark "9FFF1FFF1FFF00FFh";
BA_ "FlexKomSigStartPos" SG_ 39 ESS_ReqShiftPark 7;
BA_ "FlexKomSigName" SG_ 39 ESS_ReqShiftPark "ECM_ENG_TRQ_Pkt";
BA_ "FlexKomSigLaenge" SG_ 39 ESS_ReqShiftPark 64;
BA_ "FlexKomSID" SG_ 39 ESS_ReqShiftPark 1853;
BA_ "FlexKomIsMotorola" SG_ 39 ESS_ReqShiftPark 1;
BA_ "FlexKomComment" SG_ 39 ESS_ReqShiftPark "ECM_ENG_TRQ packet";
BA_ "GenSigSNA" SG_ 137 VehAccel_X "FFh";
BA_ "GenSigCycleTime" SG_ 137 VehAccel_X 20;
BA_ "FlexKomSigStartValue" SG_ 137 VehAccel_X "FFh";
BA_ "FlexKomSigStartPos" SG_ 137 VehAccel_X 39;
BA_ "FlexKomSigName" SG_ 137 VehAccel_X "VehAccel_X";
BA_ "FlexKomSigLaenge" SG_ 137 VehAccel_X 8;
BA_ "FlexKomSID" SG_ 137 VehAccel_X 1265;
BA_ "FlexKomIsMotorola" SG_ 137 VehAccel_X 1;
BA_ "FlexKomComment" SG_ 137 VehAccel_X "Vehicle longitudinal acceleration (+ means forward";
BA_ "GenSigTimeout_TBM" SG_ 137 VehAccel_Y_Offset 210;
BA_ "GenSigTimeout_ORC" SG_ 137 VehAccel_Y_Offset 70;
BA_ "GenSigTimeout_IC" SG_ 137 VehAccel_Y_Offset 210;
BA_ "GenSigTimeout_ETM" SG_ 137 VehAccel_Y_Offset 210;
BA_ "GenSigStartValue" SG_ 137 VehAccel_Y_Offset 255;
BA_ "GenSigSNA" SG_ 137 VehAccel_Y_Offset "FFh";
BA_ "GenSigCycleTime" SG_ 137 VehAccel_Y_Offset 20;
BA_ "FlexKomSigStartValue" SG_ 137 VehAccel_Y_Offset "FFh";
BA_ "FlexKomSigStartPos" SG_ 137 VehAccel_Y_Offset 63;
BA_ "FlexKomSigName" SG_ 137 VehAccel_Y_Offset "VehAccel_Y_Offset";
BA_ "FlexKomSigLaenge" SG_ 137 VehAccel_Y_Offset 8;
BA_ "FlexKomSID" SG_ 137 VehAccel_Y_Offset 1268;
BA_ "FlexKomIsMotorola" SG_ 137 VehAccel_Y_Offset 1;
BA_ "FlexKomComment" SG_ 137 VehAccel_Y_Offset "Offset of vehicle lateral acceleration (+ means le";
BA_ "GenSigTimeout_TBM" SG_ 135 BrkPrss_TMC 210;
BA_ "GenSigTimeout_ORC" SG_ 135 BrkPrss_TMC 70;
BA_ "GenSigTimeout_IC" SG_ 135 BrkPrss_TMC 210;
BA_ "GenSigTimeout_ETM" SG_ 135 BrkPrss_TMC 210;
BA_ "GenSigTimeout_DTCM" SG_ 135 BrkPrss_TMC 210;
BA_ "GenSigSNA" SG_ 135 BrkPrss_TMC "7FFh";
BA_ "GenSigCycleTime" SG_ 135 BrkPrss_TMC 20;
BA_ "FlexKomSigStartValue" SG_ 135 BrkPrss_TMC "7000FFFF00FF00FFh";
BA_ "FlexKomSigStartPos" SG_ 135 BrkPrss_TMC 7;
BA_ "FlexKomSigName" SG_ 135 BrkPrss_TMC "ESC_data";
BA_ "FlexKomSigLaenge" SG_ 135 BrkPrss_TMC 64;
BA_ "FlexKomSID" SG_ 135 BrkPrss_TMC 1416;
BA_ "FlexKomIsMotorola" SG_ 135 BrkPrss_TMC 1;
BA_ "FlexKomComment" SG_ 135 BrkPrss_TMC "ESC data";
BA_ "GenSigTimeout_ESM" SG_ 121 BrkTrq_D 210;
BA_ "GenSigTimeout_DTCM" SG_ 121 BrkTrq_D 210;
BA_ "GenSigStartValue" SG_ 121 BrkTrq_D 4095;
BA_ "GenSigSNA" SG_ 121 BrkTrq_D "FFFh";
BA_ "GenSigCycleTime" SG_ 121 BrkTrq_D 20;
BA_ "FlexKomSigStartValue" SG_ 121 BrkTrq_D "0FFF0FFFFFFF00FFh";
BA_ "FlexKomSigStartPos" SG_ 121 BrkTrq_D 7;
BA_ "FlexKomSigName" SG_ 121 BrkTrq_D "VEH_SPEED_PKT";
BA_ "FlexKomSigLaenge" SG_ 121 BrkTrq_D 64;
BA_ "FlexKomSID" SG_ 121 BrkTrq_D 11;
BA_ "FlexKomIsMotorola" SG_ 121 BrkTrq_D 1;
BA_ "FlexKomComment" SG_ 121 BrkTrq_D "Vehicle Speed Packet";
BA_ "GenSigTimeout_ORC" SG_ 121 CRC_VEH_SPEED 70;
BA_ "GenSigTimeout_IC" SG_ 121 CRC_VEH_SPEED 210;
BA_ "GenSigTimeout_ESM" SG_ 121 CRC_VEH_SPEED 210;
BA_ "GenSigTimeout_ESL" SG_ 121 CRC_VEH_SPEED 110;
BA_ "GenSigTimeout_CBC" SG_ 121 CRC_VEH_SPEED 110;
BA_ "GenSigStartValue" SG_ 121 CRC_VEH_SPEED 255;
BA_ "GenSigSNA" SG_ 121 CRC_VEH_SPEED "FFh";
BA_ "GenSigCycleTime" SG_ 121 CRC_VEH_SPEED 20;
BA_ "FlexKomSigStartValue" SG_ 121 CRC_VEH_SPEED "0FFF0FFFFFFF00FFh";
BA_ "FlexKomSigStartPos" SG_ 121 CRC_VEH_SPEED 7;
BA_ "FlexKomSigName" SG_ 121 CRC_VEH_SPEED "VEH_SPEED_PKT";
BA_ "FlexKomSigLaenge" SG_ 121 CRC_VEH_SPEED 64;
BA_ "FlexKomSID" SG_ 121 CRC_VEH_SPEED 11;
BA_ "FlexKomIsMotorola" SG_ 121 CRC_VEH_SPEED 1;
BA_ "FlexKomComment" SG_ 121 CRC_VEH_SPEED "Vehicle Speed Packet";
BA_ "GenSigTimeout_ORC" SG_ 139 WhlRPM_FR 70;
BA_ "GenSigTimeout_ESL" SG_ 139 WhlRPM_FR 210;
BA_ "GenSigTimeout_DTCM" SG_ 139 WhlRPM_FR 210;
BA_ "GenSigStartValue" SG_ 139 WhlRPM_FR 16383;
BA_ "GenSigSNA" SG_ 139 WhlRPM_FR "3FFFh";
BA_ "GenSigCycleTime" SG_ 139 WhlRPM_FR 20;
BA_ "FlexKomSigStartValue" SG_ 139 WhlRPM_FR "FFFFFFFFFFFFFFFFh";
BA_ "FlexKomSigStartPos" SG_ 139 WhlRPM_FR 7;
BA_ "FlexKomSigName" SG_ 139 WhlRPM_FR "WHEEL_SPEED";
BA_ "FlexKomSigLaenge" SG_ 139 WhlRPM_FR 64;
BA_ "FlexKomSID" SG_ 139 WhlRPM_FR 64;
BA_ "FlexKomIsMotorola" SG_ 139 WhlRPM_FR 1;
BA_ "FlexKomComment" SG_ 139 WhlRPM_FR "ESP Wheel Speed";
BA_ "RID" SG_ 39 MdsActforANC "2102";
BA_ "GenSigSNA" SG_ 39 MdsActforANC "0h";
BA_ "GenSigCycleTime" SG_ 39 MdsActforANC 10;
BA_ "FlexKomSigStartValue" SG_ 39 MdsActforANC "9FFF1FFF1FFF00FFh";
BA_ "FlexKomSigStartPos" SG_ 39 MdsActforANC 7;
BA_ "FlexKomSigName" SG_ 39 MdsActforANC "ECM_ENG_TRQ_Pkt";
BA_ "FlexKomSigLaenge" SG_ 39 MdsActforANC 64;
BA_ "FlexKomSID" SG_ 39 MdsActforANC 1853;
BA_ "FlexKomIsMotorola" SG_ 39 MdsActforANC 1;
BA_ "FlexKomComment" SG_ 39 MdsActforANC "ECM_ENG_TRQ packet";
BA_ "GenSigTimeout_ORC" SG_ 334 ESP_TrqRqEnabl 350;
BA_ "GenSigSNA" SG_ 334 ESP_TrqRqEnabl "0h";
BA_ "GenSigCycleTime" SG_ 334 ESP_TrqRqEnabl 100;
BA_ "FlexKomSigStartValue" SG_ 334 ESP_TrqRqEnabl "00FFFFFFFFFFFFFFh";
BA_ "FlexKomSigStartPos" SG_ 334 ESP_TrqRqEnabl 7;
BA_ "FlexKomSigName" SG_ 334 ESP_TrqRqEnabl "EDR_Pkt";
BA_ "FlexKomSigLaenge" SG_ 334 ESP_TrqRqEnabl 64;
BA_ "FlexKomSID" SG_ 334 ESP_TrqRqEnabl 762;
BA_ "FlexKomIsMotorola" SG_ 334 ESP_TrqRqEnabl 1;
BA_ "FlexKomComment" SG_ 334 ESP_TrqRqEnabl "EDR Only information packet";
BA_ "GenSigTimeout_ORC" SG_ 334 Lv1CrsCtrlOff 350;
BA_ "GenSigTimeout_IC" SG_ 221 ABS_IndLmp_On_Rq 275;
BA_ "GenSigTimeout_ETM" SG_ 221 ABS_IndLmp_On_Rq 525;
BA_ "GenSigStartValue" SG_ 221 ABS_IndLmp_On_Rq 3;
BA_ "GenSigSNA" SG_ 221 ABS_IndLmp_On_Rq "3h";
BA_ "GenSigCycleTime" SG_ 221 ABS_IndLmp_On_Rq 50;
BA_ "FlexKomSigStartValue" SG_ 221 ABS_IndLmp_On_Rq "003Fh";
BA_ "FlexKomSigStartPos" SG_ 221 ABS_IndLmp_On_Rq 55;
BA_ "FlexKomSigName" SG_ 221 ABS_IndLmp_On_Rq "ESP_HMI";
BA_ "FlexKomSigLaenge" SG_ 221 ABS_IndLmp_On_Rq 16;
BA_ "FlexKomSID" SG_ 221 ABS_IndLmp_On_Rq 397;
BA_ "FlexKomIsMotorola" SG_ 221 ABS_IndLmp_On_Rq 1;
BA_ "FlexKomComment" SG_ 221 ABS_IndLmp_On_Rq "ESP Customer Indicators";
BA_ "GenSigTimeout_ORC" SG_ 121 MC_VEH_SPEED 70;
BA_ "GenSigTimeout_IC" SG_ 121 MC_VEH_SPEED 210;
BA_ "GenSigTimeout_ESM" SG_ 121 MC_VEH_SPEED 210;
BA_ "GenSigTimeout_ESL" SG_ 121 MC_VEH_SPEED 110;
BA_ "GenSigTimeout_CBC" SG_ 121 MC_VEH_SPEED 110;
BA_ "GenSigSNA" SG_ 121 MC_VEH_SPEED "0h";
BA_ "GenSigCycleTime" SG_ 121 MC_VEH_SPEED 20;
BA_ "FlexKomSigStartValue" SG_ 121 MC_VEH_SPEED "0FFF0FFFFFFF00FFh";
BA_ "FlexKomSigStartPos" SG_ 121 MC_VEH_SPEED 7;
BA_ "FlexKomSigName" SG_ 121 MC_VEH_SPEED "VEH_SPEED_PKT";
BA_ "FlexKomSigLaenge" SG_ 121 MC_VEH_SPEED 64;
BA_ "FlexKomSID" SG_ 121 MC_VEH_SPEED 11;
BA_ "FlexKomIsMotorola" SG_ 121 MC_VEH_SPEED 1;
BA_ "FlexKomComment" SG_ 121 MC_VEH_SPEED "Vehicle Speed Packet";
BA_ "GenSigTimeout_ORC" SG_ 139 WhlRPM_FL 70;
BA_ "GenSigTimeout_ESL" SG_ 139 WhlRPM_FL 210;
BA_ "GenSigTimeout_DTCM" SG_ 139 WhlRPM_FL 210;
BA_ "GenSigStartValue" SG_ 139 WhlRPM_FL 16383;
BA_ "GenSigSNA" SG_ 139 WhlRPM_FL "3FFFh";
BA_ "GenSigCycleTime" SG_ 139 WhlRPM_FL 20;
BA_ "FlexKomSigStartValue" SG_ 139 WhlRPM_FL "FFFFFFFFFFFFFFFFh";
BA_ "FlexKomSigStartPos" SG_ 139 WhlRPM_FL 7;
BA_ "FlexKomSigName" SG_ 139 WhlRPM_FL "WHEEL_SPEED";
BA_ "FlexKomSigLaenge" SG_ 139 WhlRPM_FL 64;
BA_ "FlexKomSID" SG_ 139 WhlRPM_FL 64;
BA_ "FlexKomIsMotorola" SG_ 139 WhlRPM_FL 1;
BA_ "FlexKomComment" SG_ 139 WhlRPM_FL "ESP Wheel Speed";
BA_ "GenSigTimeout_TCM" SG_ 139 WhlRPM_RR 210;
BA_ "GenSigTimeout_ORC" SG_ 139 WhlRPM_RR 70;
BA_ "GenSigTimeout_ESL" SG_ 139 WhlRPM_RR 210;
BA_ "GenSigTimeout_DTCM" SG_ 139 WhlRPM_RR 210;
BA_ "GenSigTimeout_CBC" SG_ 139 WhlRPM_RR 110;
BA_ "GenSigStartValue" SG_ 139 WhlRPM_RR 16383;
BA_ "GenSigSNA" SG_ 139 WhlRPM_RR "3FFFh";
BA_ "GenSigCycleTime" SG_ 139 WhlRPM_RR 20;
BA_ "FlexKomSigStartValue" SG_ 139 WhlRPM_RR "FFFFFFFFFFFFFFFFh";
BA_ "FlexKomSigStartPos" SG_ 139 WhlRPM_RR 7;
BA_ "FlexKomSigName" SG_ 139 WhlRPM_RR "WHEEL_SPEED";
BA_ "FlexKomSigLaenge" SG_ 139 WhlRPM_RR 64;
BA_ "FlexKomSID" SG_ 139 WhlRPM_RR 64;
BA_ "FlexKomIsMotorola" SG_ 139 WhlRPM_RR 1;
BA_ "FlexKomComment" SG_ 139 WhlRPM_RR "ESP Wheel Speed";
BA_ "GenSigSNA" SG_ 39 MC_ECM_ENG_TRQ "0h";
BA_ "GenSigCycleTime" SG_ 39 MC_ECM_ENG_TRQ 10;
BA_ "FlexKomSigStartValue" SG_ 39 MC_ECM_ENG_TRQ "9FFF1FFF1FFF00FFh";
BA_ "FlexKomSigStartPos" SG_ 39 MC_ECM_ENG_TRQ 7;
BA_ "FlexKomSigName" SG_ 39 MC_ECM_ENG_TRQ "ECM_ENG_TRQ_Pkt";
BA_ "FlexKomSigLaenge" SG_ 39 MC_ECM_ENG_TRQ 64;
BA_ "FlexKomSID" SG_ 39 MC_ECM_ENG_TRQ 1853;
BA_ "FlexKomIsMotorola" SG_ 39 MC_ECM_ENG_TRQ 1;
BA_ "FlexKomComment" SG_ 39 MC_ECM_ENG_TRQ "ECM_ENG_TRQ packet";
BA_ "RID" SG_ 39 MdsAct "2097";
BA_ "GenSigTimeout_IC" SG_ 39 MdsAct 105;
BA_ "GenSigSNA" SG_ 39 MdsAct "0h";
BA_ "GenSigCycleTime" SG_ 39 MdsAct 10;
BA_ "FlexKomSigStartValue" SG_ 39 MdsAct "9FFF1FFF1FFF00FFh";
BA_ "FlexKomSigStartPos" SG_ 39 MdsAct 7;
BA_ "FlexKomSigName" SG_ 39 MdsAct "ECM_ENG_TRQ_Pkt";
BA_ "FlexKomSigLaenge" SG_ 39 MdsAct 64;
BA_ "FlexKomSID" SG_ 39 MdsAct 1853;
BA_ "FlexKomIsMotorola" SG_ 39 MdsAct 1;
BA_ "FlexKomComment" SG_ 39 MdsAct "ECM_ENG_TRQ packet";
BA_ "RID" SG_ 129 CRUISE_EGD "1101";
BA_ "GenSigTimeout_TCM" SG_ 129 CRUISE_EGD 210;
BA_ "GenSigTimeout_ORC" SG_ 129 CRUISE_EGD 70;
BA_ "GenSigTimeout_IC" SG_ 129 CRUISE_EGD 210;
BA_ "GenSigTimeout_CBC" SG_ 129 CRUISE_EGD 210;
BA_ "GenSigSNA" SG_ 129 CRUISE_EGD "0h";
BA_ "GenSigCycleTime" SG_ 129 CRUISE_EGD 20;
BA_ "FlexKomSigStartValue" SG_ 129 CRUISE_EGD "00h";
BA_ "FlexKomSigStartPos" SG_ 129 CRUISE_EGD 5;
BA_ "FlexKomSigName" SG_ 129 CRUISE_EGD "CRUISE_EGD";
BA_ "FlexKomSigLaenge" SG_ 129 CRUISE_EGD 1;
BA_ "FlexKomSID" SG_ 129 CRUISE_EGD 856;
BA_ "FlexKomIsMotorola" SG_ 129 CRUISE_EGD 1;
BA_ "FlexKomComment" SG_ 129 CRUISE_EGD "Cruise system is controlling speed";
BA_ "GenSigStartValue" SG_ 334 RawTPS1 255;
BA_ "GenSigSNA" SG_ 334 RawTPS1 "FFh";
BA_ "GenSigCycleTime" SG_ 334 RawTPS1 100;
BA_ "FlexKomSigStartValue" SG_ 334 RawTPS1 "00FFFFFFFFFFFFFFh";
BA_ "FlexKomSigStartPos" SG_ 334 RawTPS1 7;
BA_ "FlexKomSigName" SG_ 334 RawTPS1 "EDR_Pkt";
BA_ "FlexKomSigLaenge" SG_ 334 RawTPS1 64;
BA_ "FlexKomSID" SG_ 334 RawTPS1 762;
BA_ "FlexKomIsMotorola" SG_ 334 RawTPS1 1;
BA_ "FlexKomComment" SG_ 334 RawTPS1 "EDR Only information packet";
BA_ "GenSigSNA" SG_ 311 EVPmpStat "3h";
BA_ "GenSigCycleTime" SG_ 311 EVPmpStat 100;
BA_ "FlexKomSigStartValue" SG_ 311 EVPmpStat "00h";
BA_ "FlexKomSigStartPos" SG_ 311 EVPmpStat 13;
BA_ "FlexKomSigName" SG_ 311 EVPmpStat "EVPmpStat";
BA_ "FlexKomSigLaenge" SG_ 311 EVPmpStat 2;
BA_ "FlexKomSID" SG_ 311 EVPmpStat 1418;
BA_ "FlexKomIsMotorola" SG_ 311 EVPmpStat 1;
BA_ "FlexKomComment" SG_ 311 EVPmpStat "Electric vacuum pump status";
BA_ "RID" SG_ 311 SpStSwStat "1002 1617 1706 5114";
BA_ "GenSigTimeout_ORC" SG_ 311 SpStSwStat 350;
BA_ "GenSigTimeout_IC" SG_ 311 SpStSwStat 1050;
BA_ "GenSigTimeout_CBC" SG_ 311 SpStSwStat 1050;
BA_ "GenSigSNA" SG_ 311 SpStSwStat "3h";
BA_ "GenSigCycleTime" SG_ 311 SpStSwStat 100;
BA_ "FlexKomSigStartValue" SG_ 311 SpStSwStat "0000h";
BA_ "FlexKomSigStartPos" SG_ 311 SpStSwStat 55;
BA_ "FlexKomSigName" SG_ 311 SpStSwStat "SpStPacket";
BA_ "FlexKomSigLaenge" SG_ 311 SpStSwStat 16;
BA_ "FlexKomSID" SG_ 311 SpStSwStat 1567;
BA_ "FlexKomIsMotorola" SG_ 311 SpStSwStat 1;
BA_ "FlexKomComment" SG_ 311 SpStSwStat "Stop start packet";
BA_ "GenSigTimeout_IC" SG_ 311 EconShftRq 1050;
BA_ "GenSigSNA" SG_ 311 EconShftRq "3h";
BA_ "GenSigCycleTime" SG_ 311 EconShftRq 100;
BA_ "FlexKomSigStartValue" SG_ 311 EconShftRq "00h";
BA_ "FlexKomSigStartPos" SG_ 311 EconShftRq 15;
BA_ "FlexKomSigName" SG_ 311 EconShftRq "EconShftRq";
BA_ "FlexKomSigLaenge" SG_ 311 EconShftRq 2;
BA_ "FlexKomSID" SG_ 311 EconShftRq 1642;
BA_ "FlexKomIsMotorola" SG_ 311 EconShftRq 1;
BA_ "FlexKomComment" SG_ 311 EconShftRq "Economy transmission shift request";
BA_ "GenSigSNA" SG_ 676 MC_ECM_B11 "0h";
BA_ "GenSigCycleTime" SG_ 676 MC_ECM_B11 100;
BA_ "FlexKomSigStartValue" SG_ 676 MC_ECM_B11 "00h";
BA_ "FlexKomSigStartPos" SG_ 676 MC_ECM_B11 55;
BA_ "FlexKomSigName" SG_ 676 MC_ECM_B11 "MC_ECM_B11";
BA_ "FlexKomSigLaenge" SG_ 676 MC_ECM_B11 4;
BA_ "FlexKomSID" SG_ 676 MC_ECM_B11 2792;
BA_ "FlexKomIsMotorola" SG_ 676 MC_ECM_B11 1;
BA_ "FlexKomComment" SG_ 676 MC_ECM_B11 "Message Counter";
BA_ "RID" SG_ 663 SpSt_Pad2 "1934";
BA_ "GenSigSNA" SG_ 663 SpSt_Pad2 "7h";
BA_ "GenSigSendType" SG_ 663 SpSt_Pad2 5;
BA_ "GenSigCycleTime" SG_ 663 SpSt_Pad2 1000;
BA_ "FlexKomSigStartValue" SG_ 663 SpSt_Pad2 "00h";
BA_ "FlexKomSigStartPos" SG_ 663 SpSt_Pad2 55;
BA_ "FlexKomSigName" SG_ 663 SpSt_Pad2 "SpSt_Pad2";
BA_ "FlexKomSigLaenge" SG_ 663 SpSt_Pad2 3;
BA_ "FlexKomSID" SG_ 663 SpSt_Pad2 1960;
BA_ "FlexKomIsMotorola" SG_ 663 SpSt_Pad2 1;
BA_ "FlexKomComment" SG_ 663 SpSt_Pad2 "Stop / start switch - pad 2";
BA_ "GenSigCycleTime" SG_ 113 DsblFuelShutOff 20;
BA_ "FlexKomSigStartValue" SG_ 113 DsblFuelShutOff "00000000FF0000FFh";
BA_ "FlexKomSigStartPos" SG_ 113 DsblFuelShutOff 7;
BA_ "FlexKomSigName" SG_ 113 DsblFuelShutOff "Eng_Trq_Rq";
BA_ "FlexKomSigLaenge" SG_ 113 DsblFuelShutOff 64;
BA_ "FlexKomSID" SG_ 113 DsblFuelShutOff 1;
BA_ "FlexKomIsMotorola" SG_ 113 DsblFuelShutOff 1;
BA_ "FlexKomComment" SG_ 113 DsblFuelShutOff "Engine torque request from ESC";
BA_ "GenSigTimeout_RF_HUB" SG_ 295 AirPress_Outsd 1050;
BA_ "GenSigTimeout_IC" SG_ 295 AirPress_Outsd 1050;
BA_ "GenSigTimeout_ETM" SG_ 295 AirPress_Outsd 1050;
BA_ "GenSigStartValue" SG_ 295 AirPress_Outsd 255;
BA_ "GenSigSNA" SG_ 295 AirPress_Outsd "FFh";
BA_ "GenSigCycleTime" SG_ 295 AirPress_Outsd 100;
BA_ "FlexKomSigStartValue" SG_ 295 AirPress_Outsd "FFh";
BA_ "FlexKomSigStartPos" SG_ 295 AirPress_Outsd 23;
BA_ "FlexKomSigName" SG_ 295 AirPress_Outsd "AirPress_Outsd";
BA_ "FlexKomSigLaenge" SG_ 295 AirPress_Outsd 8;
BA_ "FlexKomSID" SG_ 295 AirPress_Outsd 1084;
BA_ "FlexKomIsMotorola" SG_ 295 AirPress_Outsd 1;
BA_ "FlexKomComment" SG_ 295 AirPress_Outsd "Ambient air pressure (barometric pressure)";
BA_ "RID" SG_ 295 CHRG_FAIL "6549";
BA_ "GenSigTimeout_TBM" SG_ 295 CHRG_FAIL 1050;
BA_ "GenSigTimeout_ORC" SG_ 295 CHRG_FAIL 350;
BA_ "GenSigTimeout_IC" SG_ 295 CHRG_FAIL 1050;
BA_ "GenSigSNA" SG_ 295 CHRG_FAIL "1h";
BA_ "GenSigCycleTime" SG_ 295 CHRG_FAIL 100;
BA_ "FlexKomSigStartValue" SG_ 295 CHRG_FAIL "00h";
BA_ "FlexKomSigStartPos" SG_ 295 CHRG_FAIL 41;
BA_ "FlexKomSigName" SG_ 295 CHRG_FAIL "CHRG_FAIL";
BA_ "FlexKomSigLaenge" SG_ 295 CHRG_FAIL 1;
BA_ "FlexKomSID" SG_ 295 CHRG_FAIL 1085;
BA_ "FlexKomIsMotorola" SG_ 295 CHRG_FAIL 1;
BA_ "FlexKomComment" SG_ 295 CHRG_FAIL "Charging system Failure (battery indicator request";
BA_ "RID" SG_ 634 ODO "1177 2112";
BA_ "GenSigTimeout_TCM" SG_ 634 ODO 3500;
BA_ "GenSigTimeout_SCCM" SG_ 634 ODO 10500;
BA_ "GenSigTimeout_RF_HUB" SG_ 634 ODO 10500;
BA_ "GenSigTimeout_ORC" SG_ 634 ODO 3500;
BA_ "GenSigTimeout_ESM" SG_ 634 ODO 10500;
BA_ "GenSigTimeout_EHPS" SG_ 634 ODO 10500;
BA_ "GenSigTimeout_DTCM" SG_ 634 ODO 10500;
BA_ "GenSigTimeout_CBC" SG_ 634 ODO 10500;
BA_ "GenSigStartValue" SG_ 634 ODO 16777215;
BA_ "GenSigSNA" SG_ 634 ODO "FFFFFFh";
BA_ "GenSigSendType" SG_ 634 ODO 5;
BA_ "GenSigTimeout_ORC" SG_ 334 RelativeThrt 350;
BA_ "GenSigStartValue" SG_ 334 RelativeThrt 255;
BA_ "GenSigSNA" SG_ 334 RelativeThrt "FFh";
BA_ "GenSigCycleTime" SG_ 334 RelativeThrt 100;
BA_ "FlexKomSigStartValue" SG_ 334 RelativeThrt "00FFFFFFFFFFFFFFh";
BA_ "FlexKomSigStartPos" SG_ 334 RelativeThrt 7;
BA_ "FlexKomSigName" SG_ 334 RelativeThrt "EDR_Pkt";
BA_ "FlexKomSigLaenge" SG_ 334 RelativeThrt 64;
BA_ "FlexKomSID" SG_ 334 RelativeThrt 762;
BA_ "FlexKomIsMotorola" SG_ 334 RelativeThrt 1;
BA_ "FlexKomComment" SG_ 334 RelativeThrt "EDR Only information packet";
BA_ "GenSigTimeout_ORC" SG_ 334 RawPVS1 350;
BA_ "GenSigStartValue" SG_ 334 RawPVS1 255;
BA_ "GenSigSNA" SG_ 334 RawPVS1 "FFh";
BA_ "GenSigCycleTime" SG_ 334 RawPVS1 100;
BA_ "FlexKomSigStartValue" SG_ 334 RawPVS1 "00FFFFFFFFFFFFFFh";
BA_ "FlexKomSigStartPos" SG_ 334 RawPVS1 7;
BA_ "FlexKomSigName" SG_ 334 RawPVS1 "EDR_Pkt";
BA_ "FlexKomSigLaenge" SG_ 334 RawPVS1 64;
BA_ "FlexKomSID" SG_ 334 RawPVS1 762;
BA_ "FlexKomIsMotorola" SG_ 334 RawPVS1 1;
BA_ "FlexKomComment" SG_ 334 RawPVS1 "EDR Only information packet";
BA_ "GenSigTimeout_ORC" SG_ 334 RawTPS2 350;
BA_ "GenSigStartValue" SG_ 334 RawTPS2 255;
BA_ "GenSigSNA" SG_ 334 RawTPS2 "FFh";
BA_ "GenSigCycleTime" SG_ 334 RawTPS2 100;
BA_ "FlexKomSigStartValue" SG_ 334 RawTPS2 "00FFFFFFFFFFFFFFh";
BA_ "FlexKomSigStartPos" SG_ 334 RawTPS2 7;
BA_ "FlexKomSigName" SG_ 334 RawTPS2 "EDR_Pkt";
BA_ "FlexKomSigLaenge" SG_ 334 RawTPS2 64;
BA_ "FlexKomSID" SG_ 334 RawTPS2 762;
BA_ "FlexKomIsMotorola" SG_ 334 RawTPS2 1;
BA_ "FlexKomComment" SG_ 334 RawTPS2 "EDR Only information packet";
BA_ "GenSigSNA" SG_ 621 ElecClntHtrInletTemp "FFh";
BA_ "GenSigSendType" SG_ 621 ElecClntHtrInletTemp 5;
BA_ "GenSigCycleTime" SG_ 621 ElecClntHtrInletTemp 1000;
BA_ "FlexKomSigStartValue" SG_ 621 ElecClntHtrInletTemp "00001E000001FF00h";
BA_ "FlexKomSigStartPos" SG_ 621 ElecClntHtrInletTemp 7;
BA_ "FlexKomSigName" SG_ 621 ElecClntHtrInletTemp "HCP_2";
BA_ "FlexKomSigLaenge" SG_ 621 ElecClntHtrInletTemp 64;
BA_ "FlexKomSID" SG_ 621 ElecClntHtrInletTemp 2512;
BA_ "FlexKomIsMotorola" SG_ 621 ElecClntHtrInletTemp 1;
BA_ "FlexKomComment" SG_ 621 ElecClntHtrInletTemp "HCP message 2 packet";
BA_ "GenSigStartValue" SG_ 621 HTAuxPmpMontrngRPM 3;
BA_ "GenSigSNA" SG_ 621 HTAuxPmpMontrngRPM "3h";
BA_ "GenSigSendType" SG_ 621 HTAuxPmpMontrngRPM 5;
BA_ "GenSigCycleTime" SG_ 621 HTAuxPmpMontrngRPM 1000;
BA_ "FlexKomSigStartValue" SG_ 621 HTAuxPmpMontrngRPM "00001E000001FF00h";
BA_ "FlexKomSigStartPos" SG_ 621 HTAuxPmpMontrngRPM 7;
BA_ "FlexKomSigName" SG_ 621 HTAuxPmpMontrngRPM "HCP_2";
BA_ "FlexKomSigLaenge" SG_ 621 HTAuxPmpMontrngRPM 64;
BA_ "FlexKomSID" SG_ 621 HTAuxPmpMontrngRPM 2512;
BA_ "FlexKomIsMotorola" SG_ 621 HTAuxPmpMontrngRPM 1;
BA_ "FlexKomComment" SG_ 621 HTAuxPmpMontrngRPM "HCP message 2 packet";
BA_ "GenSigTimeout_IC" SG_ 311 CC_SetSpdDsplMPH 1050;
BA_ "GenSigSNA" SG_ 43 LongAcceleration "FFFh";
BA_ "GenSigCycleTime" SG_ 43 LongAcceleration 10;
BA_ "FlexKomSigStartValue" SG_ 43 LongAcceleration "000000000FFF00FFh";
BA_ "FlexKomSigStartPos" SG_ 43 LongAcceleration 7;
BA_ "FlexKomSigName" SG_ 43 LongAcceleration "ORC_YRS_PKT";
BA_ "FlexKomSigLaenge" SG_ 43 LongAcceleration 64;
BA_ "FlexKomSID" SG_ 43 LongAcceleration 1587;
BA_ "FlexKomIsMotorola" SG_ 43 LongAcceleration 1;
BA_ "FlexKomComment" SG_ 43 LongAcceleration "Accelerometer data packet";
BA_ "GenSigTimeout_CBC" SG_ 295 R134a_Press_Stat 1050;
BA_ "GenSigStartValue" SG_ 295 R134a_Press_Stat 511;
BA_ "GenSigSNA" SG_ 295 R134a_Press_Stat "1FFh";
BA_ "GenSigCycleTime" SG_ 295 R134a_Press_Stat 100;
BA_ "FlexKomSigStartValue" SG_ 295 R134a_Press_Stat "01FFh";
BA_ "FlexKomSigStartPos" SG_ 295 R134a_Press_Stat 47;
BA_ "FlexKomSigName" SG_ 295 R134a_Press_Stat "R134a_Press_Stat";
BA_ "FlexKomSigLaenge" SG_ 295 R134a_Press_Stat 16;
BA_ "FlexKomSID" SG_ 295 R134a_Press_Stat 787;
BA_ "FlexKomIsMotorola" SG_ 295 R134a_Press_Stat 1;
BA_ "FlexKomComment" SG_ 295 R134a_Press_Stat "Refrigerant pressure (R134a or R1234YF)";
BA_ "RID" SG_ 295 AC_CLTCH_EGD "1165";
BA_ "GenSigSNA" SG_ 295 AC_CLTCH_EGD "0h";
BA_ "GenSigCycleTime" SG_ 295 AC_CLTCH_EGD 100;
BA_ "FlexKomSigStartValue" SG_ 295 AC_CLTCH_EGD "00h";
BA_ "FlexKomSigStartPos" SG_ 295 AC_CLTCH_EGD 47;
BA_ "FlexKomSigName" SG_ 295 AC_CLTCH_EGD "AC_CLTCH_EGD";
BA_ "FlexKomSigLaenge" SG_ 295 AC_CLTCH_EGD 1;
BA_ "FlexKomSID" SG_ 295 AC_CLTCH_EGD 1086;
BA_ "FlexKomIsMotorola" SG_ 295 AC_CLTCH_EGD 1;
BA_ "FlexKomComment" SG_ 295 AC_CLTCH_EGD "AC clutch engauged";
BA_ "GenSigTimeout_IC" SG_ 311 CC_SetSpdDspl 1050;
BA_ "GenSigStartValue" SG_ 311 CC_SetSpdDspl 255;
BA_ "GenSigSNA" SG_ 311 CC_SetSpdDspl "FFh";
BA_ "GenSigCycleTime" SG_ 311 CC_SetSpdDspl 100;
BA_ "FlexKomSigStartValue" SG_ 311 CC_SetSpdDspl "FFh";
BA_ "FlexKomSigStartPos" SG_ 311 CC_SetSpdDspl 7;
BA_ "FlexKomSigName" SG_ 311 CC_SetSpdDspl "CC_SetSpdDspl";
BA_ "FlexKomSigLaenge" SG_ 311 CC_SetSpdDspl 8;
BA_ "FlexKomSID" SG_ 311 CC_SetSpdDspl 1361;
BA_ "FlexKomIsMotorola" SG_ 311 CC_SetSpdDspl 1;
BA_ "GenSigSNA" SG_ 41 REPRGD_PFC_CLR_HCP "0h";
BA_ "GenSigCycleTime" SG_ 41 REPRGD_PFC_CLR_HCP 10;
BA_ "FlexKomSigStartValue" SG_ 41 REPRGD_PFC_CLR_HCP "00000000000000FFh";
BA_ "FlexKomSigStartPos" SG_ 41 REPRGD_PFC_CLR_HCP 7;
BA_ "FlexKomSigName" SG_ 41 REPRGD_PFC_CLR_HCP "HCP_Torq_Status";
BA_ "FlexKomSigLaenge" SG_ 41 REPRGD_PFC_CLR_HCP 64;
BA_ "FlexKomSID" SG_ 41 REPRGD_PFC_CLR_HCP 2222;
BA_ "FlexKomIsMotorola" SG_ 41 REPRGD_PFC_CLR_HCP 1;
BA_ "FlexKomComment" SG_ 41 REPRGD_PFC_CLR_HCP ".";
BA_ "FlexKomIsMotorola" SG_ 221 LT_DIST 1;
BA_ "FlexKomComment" SG_ 221 LT_DIST "Distance traveled by wheels";
BA_ "RID" SG_ 221 HSA_EN "1063";
BA_ "GenSigTimeout_IC" SG_ 221 HSA_EN 525;
BA_ "GenSigSNA" SG_ 221 HSA_EN "0h";
BA_ "GenSigCycleTime" SG_ 221 HSA_EN 50;
BA_ "FlexKomSigStartValue" SG_ 221 HSA_EN "00h";
BA_ "FlexKomSigStartPos" SG_ 221 HSA_EN 47;
BA_ "FlexKomSigName" SG_ 221 HSA_EN "EBC_Feature_Status";
BA_ "FlexKomSigLaenge" SG_ 221 HSA_EN 8;
BA_ "FlexKomSID" SG_ 221 HSA_EN 396;
BA_ "FlexKomIsMotorola" SG_ 221 HSA_EN 1;
BA_ "FlexKomComment" SG_ 221 HSA_EN "ESP feature present and enabled";
BA_ "GenSigTimeout_TCM" SG_ 139 WhlRPM_RL 210;
BA_ "GenSigTimeout_ORC" SG_ 139 WhlRPM_RL 70;
BA_ "GenSigTimeout_ESL" SG_ 139 WhlRPM_RL 210;
BA_ "GenSigTimeout_DTCM" SG_ 139 WhlRPM_RL 210;
BA_ "GenSigTimeout_CBC" SG_ 139 WhlRPM_RL 110;
BA_ "GenSigStartValue" SG_ 139 WhlRPM_RL 16383;
BA_ "GenSigSNA" SG_ 139 WhlRPM_RL "3FFFh";
BA_ "GenSigCycleTime" SG_ 139 WhlRPM_RL 20;
BA_ "FlexKomSigStartValue" SG_ 139 WhlRPM_RL "FFFFFFFFFFFFFFFFh";
BA_ "FlexKomSigStartPos" SG_ 139 WhlRPM_RL 7;
BA_ "FlexKomSigName" SG_ 139 WhlRPM_RL "WHEEL_SPEED";
BA_ "FlexKomSigLaenge" SG_ 139 WhlRPM_RL 64;
BA_ "FlexKomSID" SG_ 139 WhlRPM_RL 64;
BA_ "FlexKomIsMotorola" SG_ 139 WhlRPM_RL 1;
BA_ "FlexKomComment" SG_ 139 WhlRPM_RL "ESP Wheel Speed";
BA_ "GenSigStartValue" SG_ 39 CRC_ECM_ENG_TRQ 255;
BA_ "GenSigSNA" SG_ 39 CRC_ECM_ENG_TRQ "FFh";
BA_ "GenSigCycleTime" SG_ 39 CRC_ECM_ENG_TRQ 10;
BA_ "FlexKomSigStartValue" SG_ 39 CRC_ECM_ENG_TRQ "9FFF1FFF1FFF00FFh";
BA_ "FlexKomSigStartPos" SG_ 39 CRC_ECM_ENG_TRQ 7;
BA_ "FlexKomSigName" SG_ 39 CRC_ECM_ENG_TRQ "ECM_ENG_TRQ_Pkt";
BA_ "FlexKomSigLaenge" SG_ 39 CRC_ECM_ENG_TRQ 64;
BA_ "FlexKomSID" SG_ 39 CRC_ECM_ENG_TRQ 1853;
BA_ "FlexKomIsMotorola" SG_ 39 CRC_ECM_ENG_TRQ 1;
BA_ "FlexKomComment" SG_ 39 CRC_ECM_ENG_TRQ "ECM_ENG_TRQ packet";
BA_ "GenSigTimeout_SCCM" SG_ 129 CRUISE_ON 210;
BA_ "GenSigStartValue" SG_ 311 CC_SetSpdDsplMPH 255;
BA_ "GenSigSNA" SG_ 311 CC_SetSpdDsplMPH "FFh";
BA_ "GenSigCycleTime" SG_ 311 CC_SetSpdDsplMPH 100;
BA_ "FlexKomSigStartValue" SG_ 311 CC_SetSpdDsplMPH "FFh";
BA_ "FlexKomSigStartPos" SG_ 311 CC_SetSpdDsplMPH 47;
BA_ "FlexKomSigName" SG_ 311 CC_SetSpdDsplMPH "CC_SetSpdDsplMPH";
BA_ "FlexKomSigLaenge" SG_ 311 CC_SetSpdDsplMPH 8;
BA_ "FlexKomSID" SG_ 311 CC_SetSpdDsplMPH 1610;
BA_ "FlexKomIsMotorola" SG_ 311 CC_SetSpdDsplMPH 1;
BA_ "FlexKomComment" SG_ 311 CC_SetSpdDsplMPH "Cruise control set speed for display in miles per ";
BA_ "GenSigTimeout_ORC" SG_ 311 SpStWarnStat 350;
BA_ "GenSigTimeout_IC" SG_ 311 SpStWarnStat 1050;
BA_ "GenSigSNA" SG_ 311 SpStWarnStat "Fh";
BA_ "GenSigCycleTime" SG_ 311 SpStWarnStat 100;
BA_ "FlexKomSigStartValue" SG_ 311 SpStWarnStat "0000h";
BA_ "FlexKomSigStartPos" SG_ 311 SpStWarnStat 55;
BA_ "FlexKomSigName" SG_ 311 SpStWarnStat "SpStPacket";
BA_ "FlexKomSigLaenge" SG_ 311 SpStWarnStat 16;
BA_ "FlexKomSID" SG_ 311 SpStWarnStat 1567;
BA_ "FlexKomIsMotorola" SG_ 311 SpStWarnStat 1;
BA_ "FlexKomComment" SG_ 311 SpStWarnStat "Stop start packet";
BA_ "GenSigSNA" SG_ 676 TransWarmup_Min_RPM "FFh";
BA_ "GenSigCycleTime" SG_ 676 TransWarmup_Min_RPM 100;
BA_ "FlexKomSigStartValue" SG_ 676 TransWarmup_Min_RPM "00h";
BA_ "FlexKomSigStartPos" SG_ 676 TransWarmup_Min_RPM 39;
BA_ "FlexKomSigName" SG_ 676 TransWarmup_Min_RPM "TransWarmup_Min_RPM";
BA_ "FlexKomSigLaenge" SG_ 676 TransWarmup_Min_RPM 8;
BA_ "FlexKomSID" SG_ 676 TransWarmup_Min_RPM 2791;
BA_ "FlexKomIsMotorola" SG_ 676 TransWarmup_Min_RPM 1;
BA_ "FlexKomComment" SG_ 676 TransWarmup_Min_RPM "Enable and disable flag for transmission warm up f";
BA_ "GenSigStartValue" SG_ 676 CRC_ECM_B11 255;
BA_ "GenSigSNA" SG_ 676 CRC_ECM_B11 "FFh";
BA_ "GenSigCycleTime" SG_ 676 CRC_ECM_B11 100;
BA_ "FlexKomSigStartValue" SG_ 676 CRC_ECM_B11 "FFh";
BA_ "FlexKomSigStartPos" SG_ 676 CRC_ECM_B11 63;
BA_ "FlexKomSigName" SG_ 676 CRC_ECM_B11 "CRC_ECM_B11";
BA_ "FlexKomSigLaenge" SG_ 676 CRC_ECM_B11 8;
BA_ "FlexKomSID" SG_ 676 CRC_ECM_B11 2793;
BA_ "FlexKomIsMotorola" SG_ 676 CRC_ECM_B11 1;
BA_ "FlexKomComment" SG_ 676 CRC_ECM_B11 "CRC-Checksum Byte 1 - 7 according to SAE J1850";
BA_ "RID" SG_ 317 MIL_OnRq "1210 6543";
BA_ "GenSigTimeout_ORC" SG_ 317 MIL_OnRq 350;
BA_ "GenSigTimeout_IC" SG_ 317 MIL_OnRq 1050;
BA_ "GenSigSNA" SG_ 317 MIL_OnRq "0h";
BA_ "GenSigCycleTime" SG_ 317 MIL_OnRq 100;
BA_ "FlexKomSigStartValue" SG_ 317 MIL_OnRq "00h";
BA_ "FlexKomSigName" SG_ 317 MIL_OnRq "MIL_OnRq";
BA_ "FlexKomSigLaenge" SG_ 317 MIL_OnRq 1;
BA_ "FlexKomSID" SG_ 317 MIL_OnRq 714;
BA_ "FlexKomIsMotorola" SG_ 317 MIL_OnRq 1;
BA_ "FlexKomComment" SG_ 317 MIL_OnRq "MIL on request from the engine";
BA_ "GenSigTimeout_IC" SG_ 317 OIL_IND_LMP_FLSH 1050;
BA_ "GenSigSNA" SG_ 317 OIL_IND_LMP_FLSH "0h";
BA_ "GenSigCycleTime" SG_ 317 OIL_IND_LMP_FLSH 100;
BA_ "FlexKomSigStartValue" SG_ 317 OIL_IND_LMP_FLSH "00h";
BA_ "FlexKomSigStartPos" SG_ 317 OIL_IND_LMP_FLSH 8;
BA_ "FlexKomSigName" SG_ 317 OIL_IND_LMP_FLSH "OIL_IND_LMP_FLSH";
BA_ "FlexKomSigLaenge" SG_ 317 OIL_IND_LMP_FLSH 1;
BA_ "FlexKomSID" SG_ 317 OIL_IND_LMP_FLSH 716;
BA_ "FlexKomIsMotorola" SG_ 317 OIL_IND_LMP_FLSH 1;
BA_ "FlexKomComment" SG_ 317 OIL_IND_LMP_FLSH "Oil indicator lamp flash (for in plant use)";
BA_ "RID" SG_ 317 EngRun_Stat "2093";
BA_ "GenSigTimeout_IC" SG_ 317 EngRun_Stat 1050;
BA_ "GenSigTimeout_DTCM" SG_ 317 EngRun_Stat 1050;
BA_ "GenSigTimeout_CBC" SG_ 317 EngRun_Stat 1050;
BA_ "GenSigStartValue" SG_ 317 EngRun_Stat 7;
BA_ "GenSigSNA" SG_ 317 EngRun_Stat "7h";
BA_ "GenSigCycleTime" SG_ 317 EngRun_Stat 100;
BA_ "FlexKomSigStartValue" SG_ 317 EngRun_Stat "07h";
BA_ "FlexKomSigStartPos" SG_ 317 EngRun_Stat 58;
BA_ "FlexKomSigName" SG_ 317 EngRun_Stat "EngRun_Stat";
BA_ "FlexKomSigLaenge" SG_ 317 EngRun_Stat 3;
BA_ "FlexKomSID" SG_ 317 EngRun_Stat 1081;
BA_ "FlexKomIsMotorola" SG_ 317 EngRun_Stat 1;
BA_ "FlexKomComment" SG_ 317 EngRun_Stat "Engine running state";
BA_ "RID" SG_ 317 OIL_PRESS "1183";
BA_ "GenSigTimeout_TBM" SG_ 317 OIL_PRESS 1050;
BA_ "GenSigTimeout_IC" SG_ 317 OIL_PRESS 1050;
BA_ "GenSigTimeout_CBC" SG_ 317 OIL_PRESS 1050;
BA_ "GenSigStartValue" SG_ 317 OIL_PRESS 255;
BA_ "GenSigSNA" SG_ 317 OIL_PRESS "FFh";
BA_ "GenSigCycleTime" SG_ 317 OIL_PRESS 100;
BA_ "FlexKomSigStartValue" SG_ 317 OIL_PRESS "FFh";
BA_ "FlexKomSigStartPos" SG_ 317 OIL_PRESS 23;
BA_ "FlexKomSigName" SG_ 317 OIL_PRESS "OIL_PRESS";
BA_ "FlexKomSigLaenge" SG_ 317 OIL_PRESS 8;
BA_ "FlexKomSID" SG_ 317 OIL_PRESS 717;
BA_ "FlexKomIsMotorola" SG_ 317 OIL_PRESS 1;
BA_ "FlexKomComment" SG_ 317 OIL_PRESS "Oil pressure";
BA_ "GenSigTimeout_IC" SG_ 317 DefFuelEcon 1050;
BA_ "GenSigSNA" SG_ 296 EngineFanRequestActivation "0h";
BA_ "GenSigCycleTime" SG_ 296 EngineFanRequestActivation 100;
BA_ "FlexKomSigStartValue" SG_ 296 EngineFanRequestActivation "0200FF0000000000h";
BA_ "FlexKomSigStartPos" SG_ 296 EngineFanRequestActivation 7;
BA_ "FlexKomSigName" SG_ 296 EngineFanRequestActivation "EPS_A1_PKT";
BA_ "FlexKomSigLaenge" SG_ 296 EngineFanRequestActivation 64;
BA_ "FlexKomSID" SG_ 296 EngineFanRequestActivation 846;
BA_ "FlexKomIsMotorola" SG_ 296 EngineFanRequestActivation 1;
BA_ "FlexKomComment" SG_ 296 EngineFanRequestActivation "EPS_A1_PKT";
BA_ "GenSigStartValue" SG_ 301 Adblue_FL_LVL 255;
BA_ "GenSigSNA" SG_ 301 Adblue_FL_LVL "FFh";
BA_ "GenSigCycleTime" SG_ 301 Adblue_FL_LVL 100;
BA_ "FlexKomSigStartValue" SG_ 301 Adblue_FL_LVL "00FF0000h";
BA_ "FlexKomSigStartPos" SG_ 301 Adblue_FL_LVL 39;
BA_ "FlexKomSigName" SG_ 301 Adblue_FL_LVL "AdblueDispRq";
BA_ "FlexKomSigLaenge" SG_ 301 Adblue_FL_LVL 32;
BA_ "FlexKomSID" SG_ 301 Adblue_FL_LVL 1436;
BA_ "FlexKomIsMotorola" SG_ 301 Adblue_FL_LVL 1;
BA_ "FlexKomComment" SG_ 301 Adblue_FL_LVL "Adblue display request";
BA_ "GenSigTimeout_TBM" SG_ 137 VehAccel_X_Offset 210;
BA_ "GenSigTimeout_ORC" SG_ 137 VehAccel_X_Offset 70;
BA_ "GenSigTimeout_IC" SG_ 137 VehAccel_X_Offset 210;
BA_ "GenSigTimeout_ETM" SG_ 137 VehAccel_X_Offset 210;
BA_ "GenSigStartValue" SG_ 137 VehAccel_X_Offset 255;
BA_ "GenSigSNA" SG_ 137 VehAccel_X_Offset "FFh";
BA_ "GenSigCycleTime" SG_ 137 VehAccel_X_Offset 20;
BA_ "FlexKomSigStartValue" SG_ 137 VehAccel_X_Offset "FFh";
BA_ "FlexKomSigStartPos" SG_ 137 VehAccel_X_Offset 31;
BA_ "FlexKomSigName" SG_ 137 VehAccel_X_Offset "VehAccel_X_Offset";
BA_ "FlexKomSigLaenge" SG_ 137 VehAccel_X_Offset 8;
BA_ "FlexKomSID" SG_ 137 VehAccel_X_Offset 1264;
BA_ "FlexKomIsMotorola" SG_ 137 VehAccel_X_Offset 1;
BA_ "FlexKomComment" SG_ 137 VehAccel_X_Offset "Offset of vehicle longitudinal acceleration (+ mea";
BA_ "GenSigTimeout_TBM" SG_ 137 MC_VEH_DYN_STAT 210;
BA_ "GenSigTimeout_ORC" SG_ 137 MC_VEH_DYN_STAT 70;
BA_ "GenSigTimeout_ETM" SG_ 137 MC_VEH_DYN_STAT 210;
BA_ "GenSigSNA" SG_ 137 MC_VEH_DYN_STAT "0h";
BA_ "GenSigCycleTime" SG_ 137 MC_VEH_DYN_STAT 20;
BA_ "FlexKomSigStartValue" SG_ 137 MC_VEH_DYN_STAT "00h";
BA_ "FlexKomSigStartPos" SG_ 137 MC_VEH_DYN_STAT 55;
BA_ "FlexKomSigName" SG_ 137 MC_VEH_DYN_STAT "MC_VEH_DYN_STAT";
BA_ "FlexKomSigLaenge" SG_ 137 MC_VEH_DYN_STAT 4;
BA_ "FlexKomSID" SG_ 137 MC_VEH_DYN_STAT 1267;
BA_ "FlexKomIsMotorola" SG_ 137 MC_VEH_DYN_STAT 1;
BA_ "FlexKomComment" SG_ 137 MC_VEH_DYN_STAT "Message counter";
BA_ "GenSigTimeout_TBM" SG_ 135 HSA_BrkPrss 210;
BA_ "GenSigTimeout_ORC" SG_ 135 HSA_BrkPrss 70;
BA_ "GenSigTimeout_ETM" SG_ 135 HSA_BrkPrss 210;
BA_ "GenSigSNA" SG_ 135 HSA_BrkPrss "3Fh";
BA_ "GenSigCycleTime" SG_ 135 HSA_BrkPrss 20;
BA_ "FlexKomSigStartValue" SG_ 135 HSA_BrkPrss "7000FFFF00FF00FFh";
BA_ "FlexKomSigStartPos" SG_ 135 HSA_BrkPrss 7;
BA_ "FlexKomSigName" SG_ 135 HSA_BrkPrss "ESC_data";
BA_ "FlexKomSigLaenge" SG_ 135 HSA_BrkPrss 64;
BA_ "FlexKomSID" SG_ 135 HSA_BrkPrss 1416;
BA_ "FlexKomIsMotorola" SG_ 135 HSA_BrkPrss 1;
BA_ "FlexKomComment" SG_ 135 HSA_BrkPrss "ESC data";
BA_ "FlexKomComment" SG_ 334 BrkSw1Stat "EDR Only information packet";
BA_ "GenSigTimeout_ORC" SG_ 334 ETC_LmpOn 350;
BA_ "GenSigSNA" SG_ 334 ETC_LmpOn "0h";
BA_ "GenSigCycleTime" SG_ 334 ETC_LmpOn 100;
BA_ "FlexKomSigStartValue" SG_ 334 ETC_LmpOn "00FFFFFFFFFFFFFFh";
BA_ "FlexKomSigStartPos" SG_ 334 ETC_LmpOn 7;
BA_ "FlexKomSigName" SG_ 334 ETC_LmpOn "EDR_Pkt";
BA_ "FlexKomSigLaenge" SG_ 334 ETC_LmpOn 64;
BA_ "FlexKomSID" SG_ 334 ETC_LmpOn 762;
BA_ "FlexKomIsMotorola" SG_ 334 ETC_LmpOn 1;
BA_ "FlexKomComment" SG_ 334 ETC_LmpOn "EDR Only information packet";
BA_ "GenSigTimeout_ORC" SG_ 334 MAP 350;
BA_ "GenSigStartValue" SG_ 334 MAP 255;
BA_ "GenSigSNA" SG_ 334 MAP "FFh";
BA_ "GenSigCycleTime" SG_ 334 MAP 100;
BA_ "FlexKomSigStartValue" SG_ 334 MAP "00FFFFFFFFFFFFFFh";
BA_ "FlexKomSigStartPos" SG_ 334 MAP 7;
BA_ "FlexKomSigName" SG_ 334 MAP "EDR_Pkt";
BA_ "FlexKomSigLaenge" SG_ 334 MAP 64;
BA_ "FlexKomSID" SG_ 334 MAP 762;
BA_ "FlexKomIsMotorola" SG_ 334 MAP 1;
BA_ "FlexKomComment" SG_ 334 MAP "EDR Only information packet";
BA_ "GenSigTimeout_ORC" SG_ 334 RawPVS2 350;
BA_ "GenSigStartValue" SG_ 334 RawPVS2 255;
BA_ "GenSigSNA" SG_ 334 RawPVS2 "FFh";
BA_ "GenSigCycleTime" SG_ 334 RawPVS2 100;
BA_ "FlexKomSigStartValue" SG_ 334 RawPVS2 "00FFFFFFFFFFFFFFh";
BA_ "FlexKomSigStartPos" SG_ 334 RawPVS2 7;
BA_ "FlexKomSigName" SG_ 334 RawPVS2 "EDR_Pkt";
BA_ "FlexKomSigLaenge" SG_ 334 RawPVS2 64;
BA_ "FlexKomSID" SG_ 334 RawPVS2 762;
BA_ "FlexKomIsMotorola" SG_ 334 RawPVS2 1;
BA_ "FlexKomComment" SG_ 334 RawPVS2 "EDR Only information packet";
BA_ "GenSigTimeout_ORC" SG_ 334 RelativePdl 350;
BA_ "GenSigStartValue" SG_ 334 RelativePdl 255;
BA_ "GenSigSNA" SG_ 334 RelativePdl "FFh";
BA_ "GenSigCycleTime" SG_ 334 RelativePdl 100;
BA_ "FlexKomSigStartValue" SG_ 334 RelativePdl "00FFFFFFFFFFFFFFh";
BA_ "FlexKomSigStartPos" SG_ 334 RelativePdl 7;
BA_ "FlexKomSigName" SG_ 334 RelativePdl "EDR_Pkt";
BA_ "FlexKomSigLaenge" SG_ 334 RelativePdl 64;
BA_ "FlexKomSID" SG_ 334 RelativePdl 762;
BA_ "FlexKomIsMotorola" SG_ 334 RelativePdl 1;
BA_ "FlexKomComment" SG_ 334 RelativePdl "EDR Only information packet";
BA_ "GenSigSNA" SG_ 334 BrkSw1Stat "0h";
BA_ "GenSigCycleTime" SG_ 334 BrkSw1Stat 100;
BA_ "FlexKomSigStartValue" SG_ 334 BrkSw1Stat "00FFFFFFFFFFFFFFh";
BA_ "FlexKomSigStartPos" SG_ 334 BrkSw1Stat 7;
BA_ "FlexKomSigName" SG_ 334 BrkSw1Stat "EDR_Pkt";
BA_ "FlexKomSigLaenge" SG_ 334 BrkSw1Stat 64;
BA_ "FlexKomSID" SG_ 334 BrkSw1Stat 762;
BA_ "FlexKomIsMotorola" SG_ 334 BrkSw1Stat 1;
BA_ "GenSigSNA" SG_ 315 MIL_OnRq_HCP "0h";
BA_ "GenSigCycleTime" SG_ 315 MIL_OnRq_HCP 100;
BA_ "FlexKomSigStartValue" SG_ 315 MIL_OnRq_HCP "00000000646400FFh";
BA_ "FlexKomSigStartPos" SG_ 315 MIL_OnRq_HCP 7;
BA_ "FlexKomSigName" SG_ 315 MIL_OnRq_HCP "HCP_C1_Pkt";
BA_ "FlexKomSigLaenge" SG_ 315 MIL_OnRq_HCP 64;
BA_ "FlexKomSID" SG_ 315 MIL_OnRq_HCP 2374;
BA_ "FlexKomIsMotorola" SG_ 315 MIL_OnRq_HCP 1;
BA_ "FlexKomComment" SG_ 315 MIL_OnRq_HCP "HCP_C1_Pkt message packet";
BA_ "FlexKomComment" SG_ 311 CC_SetSpdDspl "Cruise control set speed for display (kmph only)";
BA_ "GenSigSNA" SG_ 311 SpStChmRq "0h";
BA_ "GenSigCycleTime" SG_ 311 SpStChmRq 100;
BA_ "FlexKomSigStartValue" SG_ 311 SpStChmRq "0000h";
BA_ "FlexKomSigStartPos" SG_ 311 SpStChmRq 55;
BA_ "FlexKomSigName" SG_ 311 SpStChmRq "SpStPacket";
BA_ "FlexKomSigLaenge" SG_ 311 SpStChmRq 16;
BA_ "FlexKomSID" SG_ 311 SpStChmRq 1567;
BA_ "FlexKomIsMotorola" SG_ 311 SpStChmRq 1;
BA_ "FlexKomComment" SG_ 311 SpStChmRq "Stop start packet";
BA_ "GenSigStartValue" SG_ 676 MAP_4_Bar 511;
BA_ "GenSigSNA" SG_ 676 MAP_4_Bar "1FFh";
BA_ "GenSigCycleTime" SG_ 676 MAP_4_Bar 100;
BA_ "FlexKomSigStartValue" SG_ 676 MAP_4_Bar "01FFh";
BA_ "FlexKomSigStartPos" SG_ 676 MAP_4_Bar 7;
BA_ "FlexKomSigName" SG_ 676 MAP_4_Bar "MAP_4_Bar";
BA_ "FlexKomSigLaenge" SG_ 676 MAP_4_Bar 16;
BA_ "FlexKomSID" SG_ 676 MAP_4_Bar 2688;
BA_ "FlexKomIsMotorola" SG_ 676 MAP_4_Bar 1;
BA_ "FlexKomComment" SG_ 676 MAP_4_Bar "Engine manifold pressure (4 bar range)";
BA_ "GenSigSNA" SG_ 676 TransWarmup_Enbl_Rq "0h";
BA_ "GenSigCycleTime" SG_ 676 TransWarmup_Enbl_Rq 100;
BA_ "FlexKomSigStartValue" SG_ 676 TransWarmup_Enbl_Rq "00h";
BA_ "FlexKomSigStartPos" SG_ 676 TransWarmup_Enbl_Rq 20;
BA_ "FlexKomSigName" SG_ 676 TransWarmup_Enbl_Rq "TransWarmup_Enbl_Rq";
BA_ "FlexKomSigLaenge" SG_ 676 TransWarmup_Enbl_Rq 1;
BA_ "FlexKomSID" SG_ 676 TransWarmup_Enbl_Rq 2790;
BA_ "FlexKomIsMotorola" SG_ 676 TransWarmup_Enbl_Rq 1;
BA_ "FlexKomComment" SG_ 676 TransWarmup_Enbl_Rq "Enable and disable flag for transmission warm up f";
BA_ "GenSigTimeout_ORC" SG_ 131 CRC_Brk_Stat 70;
BA_ "GenSigTimeout_IC" SG_ 131 CRC_Brk_Stat 210;
BA_ "GenSigTimeout_DTCM" SG_ 131 CRC_Brk_Stat 210;
BA_ "GenSigStartValue" SG_ 131 CRC_Brk_Stat 255;
BA_ "GenSigSNA" SG_ 131 CRC_Brk_Stat "FFh";
BA_ "GenSigCycleTime" SG_ 131 CRC_Brk_Stat 20;
BA_ "FlexKomSigStartValue" SG_ 131 CRC_Brk_Stat "0F3400C003FF00FFh";
BA_ "FlexKomSigStartPos" SG_ 131 CRC_Brk_Stat 7;
BA_ "FlexKomSigName" SG_ 131 CRC_Brk_Stat "ESP_BRK_STAT";
BA_ "FlexKomSigLaenge" SG_ 131 CRC_Brk_Stat 64;
BA_ "FlexKomIsMotorola" SG_ 131 CRC_Brk_Stat 1;
BA_ "FlexKomComment" SG_ 131 CRC_Brk_Stat "ESP Brake Status Information";
BA_ "GenSigSNA" SG_ 289 InpICC_Fail "0h";
BA_ "GenSigCycleTime" SG_ 289 InpICC_Fail 100;
BA_ "FlexKomSigStartValue" SG_ 289 InpICC_Fail "00h";
BA_ "FlexKomSigStartPos" SG_ 289 InpICC_Fail 2;
BA_ "FlexKomSigName" SG_ 289 InpICC_Fail "InpICC_Fail";
BA_ "FlexKomSigLaenge" SG_ 289 InpICC_Fail 1;
BA_ "FlexKomSID" SG_ 289 InpICC_Fail 1259;
BA_ "FlexKomIsMotorola" SG_ 289 InpICC_Fail 1;
BA_ "FlexKomComment" SG_ 289 InpICC_Fail "Inputs to the Ign Cycle Cntr are in a Pend or MIL ";
BA_ "GenSigTimeout_TBM" SG_ 131 BrkIntrvntn_Actv_ESP 210;
BA_ "GenSigTimeout_ORC" SG_ 131 BrkIntrvntn_Actv_ESP 70;
BA_ "GenSigTimeout_ESM" SG_ 131 BrkIntrvntn_Actv_ESP 210;
BA_ "GenSigTimeout_DTCM" SG_ 131 BrkIntrvntn_Actv_ESP 210;
BA_ "GenSigCycleTime" SG_ 41 PropulsionMode 10;
BA_ "FlexKomSigStartValue" SG_ 41 PropulsionMode "00000000000000FFh";
BA_ "FlexKomSigStartPos" SG_ 41 PropulsionMode 7;
BA_ "FlexKomSigName" SG_ 41 PropulsionMode "HCP_Torq_Status";
BA_ "FlexKomSigLaenge" SG_ 41 PropulsionMode 64;
BA_ "FlexKomSID" SG_ 41 PropulsionMode 2222;
BA_ "FlexKomIsMotorola" SG_ 41 PropulsionMode 1;
BA_ "FlexKomComment" SG_ 41 PropulsionMode ".";
BA_ "GenSigStartValue" SG_ 41 CRC_123h 255;
BA_ "GenSigSNA" SG_ 41 CRC_123h "FFh";
BA_ "GenSigCycleTime" SG_ 41 CRC_123h 10;
BA_ "FlexKomSigStartValue" SG_ 41 CRC_123h "00000000000000FFh";
BA_ "FlexKomSigStartPos" SG_ 41 CRC_123h 7;
BA_ "FlexKomSigName" SG_ 41 CRC_123h "HCP_Torq_Status";
BA_ "FlexKomSigLaenge" SG_ 41 CRC_123h 64;
BA_ "FlexKomSID" SG_ 41 CRC_123h 2222;
BA_ "FlexKomIsMotorola" SG_ 41 CRC_123h 1;
BA_ "FlexKomComment" SG_ 41 CRC_123h ".";
BA_ "RID" SG_ 221 ABS_IndLmp_On_Rq "6548";
BA_ "GenSigTimeout_TBM" SG_ 221 ABS_IndLmp_On_Rq 525;
BA_ "GenSigTimeout_ORC" SG_ 334 ApplyTrq 350;
BA_ "GenSigSNA" SG_ 334 ApplyTrq "0h";
BA_ "GenSigCycleTime" SG_ 334 ApplyTrq 100;
BA_ "FlexKomSigStartValue" SG_ 334 ApplyTrq "00FFFFFFFFFFFFFFh";
BA_ "FlexKomSigStartPos" SG_ 334 ApplyTrq 7;
BA_ "FlexKomSigName" SG_ 334 ApplyTrq "EDR_Pkt";
BA_ "FlexKomSigLaenge" SG_ 334 ApplyTrq 64;
BA_ "FlexKomSID" SG_ 334 ApplyTrq 762;
BA_ "FlexKomIsMotorola" SG_ 334 ApplyTrq 1;
BA_ "FlexKomComment" SG_ 334 ApplyTrq "EDR Only information packet";
BA_ "GenSigTimeout_ORC" SG_ 334 ETC_LmpFlash 350;
BA_ "GenSigSNA" SG_ 334 ETC_LmpFlash "0h";
BA_ "GenSigCycleTime" SG_ 334 ETC_LmpFlash 100;
BA_ "FlexKomSigStartValue" SG_ 334 ETC_LmpFlash "00FFFFFFFFFFFFFFh";
BA_ "FlexKomSigStartPos" SG_ 334 ETC_LmpFlash 7;
BA_ "FlexKomSigName" SG_ 334 ETC_LmpFlash "EDR_Pkt";
BA_ "FlexKomSigLaenge" SG_ 334 ETC_LmpFlash 64;
BA_ "FlexKomSID" SG_ 334 ETC_LmpFlash 762;
BA_ "FlexKomIsMotorola" SG_ 334 ETC_LmpFlash 1;
BA_ "FlexKomComment" SG_ 334 ETC_LmpFlash "EDR Only information packet";
BA_ "GenSigTimeout_ORC" SG_ 334 RawTPS1 350;
BA_ "GenSigSNA" SG_ 289 RAD_FAN1_STAT "FFh";
BA_ "GenSigCycleTime" SG_ 289 RAD_FAN1_STAT 100;
BA_ "FlexKomSigStartValue" SG_ 289 RAD_FAN1_STAT "00h";
BA_ "FlexKomSigStartPos" SG_ 289 RAD_FAN1_STAT 39;
BA_ "FlexKomSigName" SG_ 289 RAD_FAN1_STAT "RAD_FAN1_STAT";
BA_ "FlexKomSigLaenge" SG_ 289 RAD_FAN1_STAT 8;
BA_ "FlexKomSID" SG_ 289 RAD_FAN1_STAT 1091;
BA_ "FlexKomIsMotorola" SG_ 289 RAD_FAN1_STAT 1;
BA_ "FlexKomComment" SG_ 289 RAD_FAN1_STAT "Low speed or single radiator fan requested duty cy";
BA_ "RID" SG_ 317 ETC_IND_LMP "6544";
BA_ "GenSigTimeout_TBM" SG_ 317 ETC_IND_LMP 1050;
BA_ "GenSigTimeout_IC" SG_ 317 ETC_IND_LMP 1050;
BA_ "GenSigTimeout_ETM" SG_ 317 ETC_IND_LMP 1050;
BA_ "GenSigSNA" SG_ 317 ETC_IND_LMP "3h";
BA_ "GenSigCycleTime" SG_ 317 ETC_IND_LMP 100;
BA_ "FlexKomSigStartValue" SG_ 317 ETC_IND_LMP "00h";
BA_ "FlexKomSigStartPos" SG_ 317 ETC_IND_LMP 3;
BA_ "FlexKomSigName" SG_ 317 ETC_IND_LMP "ETC_IND_LMP";
BA_ "FlexKomSigLaenge" SG_ 317 ETC_IND_LMP 2;
BA_ "FlexKomSID" SG_ 317 ETC_IND_LMP 712;
BA_ "FlexKomIsMotorola" SG_ 317 ETC_IND_LMP 1;
BA_ "FlexKomComment" SG_ 317 ETC_IND_LMP "ETC faulty, indicator lamp request";
BA_ "RID" SG_ 317 EngOilTemp "1200";
BA_ "GenSigTimeout_TBM" SG_ 317 EngOilTemp 1050;
BA_ "GenSigTimeout_IC" SG_ 317 EngOilTemp 1050;
BA_ "GenSigTimeout_DTCM" SG_ 137 VehAccel_Y 210;
BA_ "GenSigTimeout_CBC" SG_ 137 VehAccel_Y 210;
BA_ "GenSigStartValue" SG_ 137 VehAccel_Y 255;
BA_ "GenSigSNA" SG_ 137 VehAccel_Y "FFh";
BA_ "GenSigTimeout_IC" SG_ 129 SpeedLimitSts 210;
BA_ "GenSigStartValue" SG_ 129 SpeedLimitSts 2;
BA_ "GenSigSNA" SG_ 129 SpeedLimitSts "7h";
BA_ "GenSigCycleTime" SG_ 129 SpeedLimitSts 20;
BA_ "FlexKomSigStartValue" SG_ 129 SpeedLimitSts "02h";
BA_ "FlexKomSigStartPos" SG_ 129 SpeedLimitSts 4;
BA_ "FlexKomSigName" SG_ 129 SpeedLimitSts "SpeedLimitSts";
BA_ "FlexKomSigLaenge" SG_ 129 SpeedLimitSts 3;
BA_ "FlexKomSID" SG_ 129 SpeedLimitSts 1865;
BA_ "FlexKomIsMotorola" SG_ 129 SpeedLimitSts 1;
BA_ "FlexKomComment" SG_ 129 SpeedLimitSts "Speed limiter status";
BA_ "GenSigSNA" SG_ 343 LeakTestRequest "0h";
BA_ "GenSigCycleTime" SG_ 343 LeakTestRequest 100;
BA_ "FlexKomSigStartValue" SG_ 343 LeakTestRequest "00h";
BA_ "FlexKomSigStartPos" SG_ 343 LeakTestRequest 26;
BA_ "FlexKomSigName" SG_ 343 LeakTestRequest "LeakTestRequest";
BA_ "FlexKomSigLaenge" SG_ 343 LeakTestRequest 1;
BA_ "FlexKomSID" SG_ 343 LeakTestRequest 2577;
BA_ "FlexKomIsMotorola" SG_ 343 LeakTestRequest 1;
BA_ "FlexKomComment" SG_ 343 LeakTestRequest "Leak test is requested after powerdown; No request";
BA_ "GenSigSNA" SG_ 343 LeakCheckTimerValue "1FFh";
BA_ "GenSigCycleTime" SG_ 343 LeakCheckTimerValue 100;
BA_ "FlexKomSigStartValue" SG_ 343 LeakCheckTimerValue "0000h";
BA_ "FlexKomSigStartPos" SG_ 343 LeakCheckTimerValue 15;
BA_ "FlexKomSigName" SG_ 343 LeakCheckTimerValue "LeakCheckTimerValue";
BA_ "FlexKomSigLaenge" SG_ 343 LeakCheckTimerValue 16;
BA_ "FlexKomSID" SG_ 343 LeakCheckTimerValue 2575;
BA_ "FlexKomIsMotorola" SG_ 343 LeakCheckTimerValue 1;
BA_ "FlexKomComment" SG_ 343 LeakCheckTimerValue "Requested leak test timer value";
BA_ "GenSigTimeout_CBC" SG_ 343 SAMInfo 1050;
BA_ "GenSigStartValue" SG_ 343 SAMInfo 15;
BA_ "GenSigSNA" SG_ 343 SAMInfo "Fh";
BA_ "GenSigCycleTime" SG_ 343 SAMInfo 100;
BA_ "FlexKomSigStartValue" SG_ 343 SAMInfo "0Fh";
BA_ "FlexKomSigStartPos" SG_ 343 SAMInfo 39;
BA_ "FlexKomSigName" SG_ 343 SAMInfo "SAMInfo";
BA_ "FlexKomSigLaenge" SG_ 343 SAMInfo 4;
BA_ "FlexKomSID" SG_ 343 SAMInfo 2649;
BA_ "FlexKomIsMotorola" SG_ 343 SAMInfo 1;
BA_ "FlexKomComment" SG_ 343 SAMInfo "Logic status of the SAM strategy";
BA_ "GenSigSNA" SG_ 347 ECM_READINESS_RESET "0h";
BA_ "GenSigCycleTime" SG_ 347 ECM_READINESS_RESET 100;
BA_ "FlexKomSigStartValue" SG_ 347 ECM_READINESS_RESET "00h";
BA_ "FlexKomSigStartPos" SG_ 347 ECM_READINESS_RESET 41;
BA_ "FlexKomSigName" SG_ 347 ECM_READINESS_RESET "ECM_CODE_READINESS_PDU";
BA_ "FlexKomSigLaenge" SG_ 347 ECM_READINESS_RESET 2;
BA_ "FlexKomSID" SG_ 347 ECM_READINESS_RESET 2963;
BA_ "FlexKomIsMotorola" SG_ 347 ECM_READINESS_RESET 1;
BA_ "FlexKomComment" SG_ 347 ECM_READINESS_RESET "ECM Code Readiness PDU";
BA_ "GenSigTimeout_CBC" SG_ 347 RevOilLifeRst 1050;
BA_ "GenSigStartValue" SG_ 347 RevOilLifeRst 65535;
BA_ "GenSigSNA" SG_ 347 RevOilLifeRst "FFFFh";
BA_ "GenSigCycleTime" SG_ 347 RevOilLifeRst 100;
BA_ "FlexKomSigStartValue" SG_ 347 RevOilLifeRst "FFFFh";
BA_ "FlexKomSigStartPos" SG_ 347 RevOilLifeRst 55;
BA_ "FlexKomSigName" SG_ 347 RevOilLifeRst "RevOilLifeRst";
BA_ "FlexKomSigLaenge" SG_ 347 RevOilLifeRst 16;
BA_ "FlexKomSID" SG_ 347 RevOilLifeRst 2109;
BA_ "FlexKomIsMotorola" SG_ 347 RevOilLifeRst 1;
BA_ "FlexKomComment" SG_ 347 RevOilLifeRst "Engine revolutions since last oil life reset";
BA_ "RID" SG_ 137 VehYawRate_Raw "1058 1289 1711";
BA_ "GenSigTimeout_TBM" SG_ 137 VehYawRate_Raw 210;
BA_ "GenSigTimeout_ORC" SG_ 137 VehYawRate_Raw 70;
BA_ "GenSigTimeout_IC" SG_ 137 VehYawRate_Raw 210;
BA_ "GenSigTimeout_DTCM" SG_ 137 VehYawRate_Raw 210;
BA_ "GenSigTimeout_CBC" SG_ 137 VehYawRate_Raw 210;
BA_ "GenSigStartValue" SG_ 137 VehYawRate_Raw 65535;
BA_ "GenSigSNA" SG_ 137 VehYawRate_Raw "FFFFh";
BA_ "GenSigCycleTime" SG_ 137 VehYawRate_Raw 20;
BA_ "FlexKomSigStartValue" SG_ 137 VehYawRate_Raw "FFFFh";
BA_ "FlexKomSigStartPos" SG_ 137 VehYawRate_Raw 7;
BA_ "FlexKomSigName" SG_ 137 VehYawRate_Raw "VehYawRate_Raw";
BA_ "FlexKomSigLaenge" SG_ 137 VehYawRate_Raw 16;
BA_ "FlexKomSID" SG_ 137 VehYawRate_Raw 1262;
BA_ "FlexKomIsMotorola" SG_ 137 VehYawRate_Raw 1;
BA_ "FlexKomComment" SG_ 137 VehYawRate_Raw "Vehicle yaw rate unfiltered/unadjusted (+ means le";
BA_ "GenSigTimeout_ORC" SG_ 131 MC_Brk_Stat 70;
BA_ "GenSigTimeout_IC" SG_ 131 MC_Brk_Stat 210;
BA_ "GenSigTimeout_DTCM" SG_ 131 MC_Brk_Stat 210;
BA_ "GenSigSNA" SG_ 131 MC_Brk_Stat "0h";
BA_ "GenSigCycleTime" SG_ 131 MC_Brk_Stat 20;
BA_ "FlexKomSigStartValue" SG_ 131 MC_Brk_Stat "0F3400C003FF00FFh";
BA_ "FlexKomSigStartPos" SG_ 131 MC_Brk_Stat 7;
BA_ "FlexKomSigName" SG_ 131 MC_Brk_Stat "ESP_BRK_STAT";
BA_ "FlexKomSigLaenge" SG_ 131 MC_Brk_Stat 64;
BA_ "FlexKomIsMotorola" SG_ 131 MC_Brk_Stat 1;
BA_ "FlexKomComment" SG_ 131 MC_Brk_Stat "ESP Brake Status Information";
BA_ "GenSigSNA" SG_ 131 Brk_Thermdl "0h";
BA_ "GenSigCycleTime" SG_ 131 Brk_Thermdl 20;
BA_ "FlexKomSigStartValue" SG_ 131 Brk_Thermdl "0F3400C003FF00FFh";
BA_ "FlexKomSigStartPos" SG_ 131 Brk_Thermdl 7;
BA_ "FlexKomSigName" SG_ 131 Brk_Thermdl "ESP_BRK_STAT";
BA_ "FlexKomSigLaenge" SG_ 131 Brk_Thermdl 64;
BA_ "FlexKomIsMotorola" SG_ 131 Brk_Thermdl 1;
BA_ "FlexKomComment" SG_ 131 Brk_Thermdl "ESP Brake Status Information";
BA_ "GenSigSNA" SG_ 334 Lv1CrsCtrlOff "0h";
BA_ "GenSigCycleTime" SG_ 334 Lv1CrsCtrlOff 100;
BA_ "FlexKomSigStartValue" SG_ 334 Lv1CrsCtrlOff "00FFFFFFFFFFFFFFh";
BA_ "FlexKomSigStartPos" SG_ 334 Lv1CrsCtrlOff 7;
BA_ "FlexKomSigName" SG_ 334 Lv1CrsCtrlOff "EDR_Pkt";
BA_ "FlexKomSigLaenge" SG_ 334 Lv1CrsCtrlOff 64;
BA_ "FlexKomSID" SG_ 334 Lv1CrsCtrlOff 762;
BA_ "FlexKomIsMotorola" SG_ 334 Lv1CrsCtrlOff 1;
BA_ "FlexKomComment" SG_ 334 Lv1CrsCtrlOff "EDR Only information packet";
BA_ "GenSigTimeout_ORC" SG_ 334 CruiseEGD 350;
BA_ "GenSigSNA" SG_ 334 CruiseEGD "0h";
BA_ "GenSigCycleTime" SG_ 334 CruiseEGD 100;
BA_ "FlexKomSigStartValue" SG_ 334 CruiseEGD "00FFFFFFFFFFFFFFh";
BA_ "FlexKomSigStartPos" SG_ 334 CruiseEGD 7;
BA_ "FlexKomSigName" SG_ 334 CruiseEGD "EDR_Pkt";
BA_ "FlexKomSigLaenge" SG_ 334 CruiseEGD 64;
BA_ "FlexKomSID" SG_ 334 CruiseEGD 762;
BA_ "FlexKomIsMotorola" SG_ 334 CruiseEGD 1;
BA_ "FlexKomComment" SG_ 334 CruiseEGD "EDR Only information packet";
BA_ "GenSigTimeout_CBC" SG_ 621 ElecCoolantHtrPwr 10500;
BA_ "GenSigSNA" SG_ 621 ElecCoolantHtrPwr "FFh";
BA_ "GenSigSendType" SG_ 621 ElecCoolantHtrPwr 5;
BA_ "GenSigCycleTime" SG_ 621 ElecCoolantHtrPwr 1000;
BA_ "FlexKomSigStartValue" SG_ 621 ElecCoolantHtrPwr "00001E000001FF00h";
BA_ "FlexKomSigStartPos" SG_ 621 ElecCoolantHtrPwr 7;
BA_ "FlexKomSigName" SG_ 621 ElecCoolantHtrPwr "HCP_2";
BA_ "FlexKomSigLaenge" SG_ 621 ElecCoolantHtrPwr 64;
BA_ "FlexKomSID" SG_ 621 ElecCoolantHtrPwr 2512;
BA_ "FlexKomIsMotorola" SG_ 621 ElecCoolantHtrPwr 1;
BA_ "FlexKomComment" SG_ 621 ElecCoolantHtrPwr "HCP message 2 packet";
BA_ "RID" SG_ 621 HTAuxPmpRPMAct "5020";
BA_ "GenSigTimeout_CBC" SG_ 621 HTAuxPmpRPMAct 10500;
BA_ "GenSigSNA" SG_ 621 HTAuxPmpRPMAct "FFh";
BA_ "GenSigSendType" SG_ 621 HTAuxPmpRPMAct 5;
BA_ "GenSigCycleTime" SG_ 621 HTAuxPmpRPMAct 1000;
BA_ "FlexKomSigStartValue" SG_ 621 HTAuxPmpRPMAct "00001E000001FF00h";
BA_ "FlexKomSigStartPos" SG_ 621 HTAuxPmpRPMAct 7;
BA_ "FlexKomSigName" SG_ 621 HTAuxPmpRPMAct "HCP_2";
BA_ "FlexKomSigLaenge" SG_ 621 HTAuxPmpRPMAct 64;
BA_ "FlexKomSID" SG_ 621 HTAuxPmpRPMAct 2512;
BA_ "FlexKomIsMotorola" SG_ 621 HTAuxPmpRPMAct 1;
BA_ "FlexKomComment" SG_ 621 HTAuxPmpRPMAct "HCP message 2 packet";
BA_ "GenSigSNA" SG_ 311 SpStIndRq "0h";
BA_ "GenSigCycleTime" SG_ 311 SpStIndRq 100;
BA_ "FlexKomSigStartValue" SG_ 311 SpStIndRq "0000h";
BA_ "FlexKomSigStartPos" SG_ 311 SpStIndRq 55;
BA_ "FlexKomSigName" SG_ 311 SpStIndRq "SpStPacket";
BA_ "FlexKomSigLaenge" SG_ 311 SpStIndRq 16;
BA_ "FlexKomSID" SG_ 311 SpStIndRq 1567;
BA_ "FlexKomIsMotorola" SG_ 311 SpStIndRq 1;
BA_ "FlexKomComment" SG_ 311 SpStIndRq "Stop start packet";
BA_ "GenSigSNA" SG_ 311 CBC_Reset_ACK "0h";
BA_ "GenSigCycleTime" SG_ 311 CBC_Reset_ACK 100;
BA_ "FlexKomSigStartValue" SG_ 311 CBC_Reset_ACK "00h";
BA_ "FlexKomSigStartPos" SG_ 311 CBC_Reset_ACK 39;
BA_ "FlexKomSigName" SG_ 311 CBC_Reset_ACK "CBC_Reset_ACK";
BA_ "FlexKomSigLaenge" SG_ 311 CBC_Reset_ACK 1;
BA_ "FlexKomSID" SG_ 311 CBC_Reset_ACK 2529;
BA_ "FlexKomIsMotorola" SG_ 311 CBC_Reset_ACK 1;
BA_ "FlexKomComment" SG_ 311 CBC_Reset_ACK "CBC reset acknowledge; True = [1]";
BA_ "GenSigTimeout_ORC" SG_ 311 SpStDispstat 350;
BA_ "GenSigTimeout_IC" SG_ 311 SpStDispstat 1050;
BA_ "GenSigSNA" SG_ 311 SpStDispstat "3Fh";
BA_ "GenSigCycleTime" SG_ 311 SpStDispstat 100;
BA_ "FlexKomSigStartValue" SG_ 311 SpStDispstat "0000h";
BA_ "GenSigSNA" SG_ 301 PTC_REL1_RQ "0h";
BA_ "GenSigCycleTime" SG_ 301 PTC_REL1_RQ 100;
BA_ "FlexKomSigStartValue" SG_ 301 PTC_REL1_RQ "00h";
BA_ "FlexKomSigStartPos" SG_ 301 PTC_REL1_RQ 23;
BA_ "FlexKomSigName" SG_ 301 PTC_REL1_RQ "PTC_REL_RQ";
BA_ "FlexKomSigLaenge" SG_ 301 PTC_REL1_RQ 3;
BA_ "FlexKomSID" SG_ 301 PTC_REL1_RQ 721;
BA_ "FlexKomIsMotorola" SG_ 301 PTC_REL1_RQ 1;
BA_ "FlexKomComment" SG_ 301 PTC_REL1_RQ "PTC relay requests";
BA_ "GenSigTimeout_IC" SG_ 301 DEF_LOW 1050;
BA_ "GenSigSNA" SG_ 301 DEF_LOW "3h";
BA_ "GenSigCycleTime" SG_ 301 DEF_LOW 100;
BA_ "FlexKomSigStartValue" SG_ 301 DEF_LOW "000Fh";
BA_ "FlexKomSigStartPos" SG_ 301 DEF_LOW 7;
BA_ "FlexKomSigName" SG_ 301 DEF_LOW "DEF_DPF_Pkt";
BA_ "FlexKomSigLaenge" SG_ 301 DEF_LOW 16;
BA_ "FlexKomSID" SG_ 301 DEF_LOW 1726;
BA_ "FlexKomIsMotorola" SG_ 301 DEF_LOW 1;
BA_ "FlexKomComment" SG_ 301 DEF_LOW "Exhaust fuel and particulate filter packet";
BA_ "GenSigTimeout_ORC" SG_ 135 MC_ESP_A3 70;
BA_ "GenSigSNA" SG_ 135 MC_ESP_A3 "0h";
BA_ "GenSigCycleTime" SG_ 135 MC_ESP_A3 20;
BA_ "FlexKomSigStartValue" SG_ 135 MC_ESP_A3 "7000FFFF00FF00FFh";
BA_ "FlexKomSigStartPos" SG_ 135 MC_ESP_A3 7;
BA_ "FlexKomSigName" SG_ 135 MC_ESP_A3 "ESC_data";
BA_ "FlexKomSigLaenge" SG_ 135 MC_ESP_A3 64;
BA_ "FlexKomSID" SG_ 135 MC_ESP_A3 1416;
BA_ "FlexKomIsMotorola" SG_ 135 MC_ESP_A3 1;
BA_ "FlexKomComment" SG_ 135 MC_ESP_A3 "ESC data";
BA_ "GenSigTimeout_TBM" SG_ 113 EngTrq_Rq_ESC 210;
BA_ "GenSigTimeout_ETM" SG_ 113 EngTrq_Rq_ESC 210;
BA_ "GenSigTimeout_DTCM" SG_ 113 EngTrq_Rq_ESC 210;
BA_ "GenSigSNA" SG_ 113 EngTrq_Rq_ESC "1FFFh";
BA_ "GenSigCycleTime" SG_ 113 EngTrq_Rq_ESC 20;
BA_ "FlexKomSigStartValue" SG_ 113 EngTrq_Rq_ESC "00000000FF0000FFh";
BA_ "FlexKomSigStartPos" SG_ 113 EngTrq_Rq_ESC 7;
BA_ "FlexKomSigName" SG_ 113 EngTrq_Rq_ESC "Eng_Trq_Rq";
BA_ "FlexKomSigLaenge" SG_ 113 EngTrq_Rq_ESC 64;
BA_ "FlexKomSID" SG_ 113 EngTrq_Rq_ESC 1;
BA_ "FlexKomIsMotorola" SG_ 113 EngTrq_Rq_ESC 1;
BA_ "FlexKomComment" SG_ 113 EngTrq_Rq_ESC "Engine torque request from ESC";
BA_ "GenSigTimeout_DTCM" SG_ 113 EngTrqMin_Rq_ESC 210;
BA_ "GenSigSNA" SG_ 113 EngTrqMin_Rq_ESC "0h";
BA_ "FlexKomSigLaenge" SG_ 611 ChargingSysSts 64;
BA_ "GenSigTimeout_ORC" SG_ 129 CRUISE_ON 70;
BA_ "GenSigTimeout_IC" SG_ 129 CRUISE_ON 210;
BA_ "GenSigSNA" SG_ 129 CRUISE_ON "0h";
BA_ "GenSigCycleTime" SG_ 129 CRUISE_ON 20;
BA_ "FlexKomSigStartValue" SG_ 129 CRUISE_ON "00h";
BA_ "FlexKomSigStartPos" SG_ 129 CRUISE_ON 7;
BA_ "FlexKomSigName" SG_ 129 CRUISE_ON "CRUISE_ON";
BA_ "FlexKomSigLaenge" SG_ 129 CRUISE_ON 1;
BA_ "FlexKomSID" SG_ 129 CRUISE_ON 1250;
BA_ "FlexKomIsMotorola" SG_ 129 CRUISE_ON 1;
BA_ "FlexKomComment" SG_ 129 CRUISE_ON "Cruise control system 'on'";
BA_ "GenSigTimeout_IC" SG_ 129 BARO_ENG 210;
BA_ "GenSigSNA" SG_ 129 BARO_ENG "FFh";
BA_ "GenSigCycleTime" SG_ 129 BARO_ENG 20;
BA_ "FlexKomSigStartValue" SG_ 129 BARO_ENG "FF00FFFF00FFh";
BA_ "FlexKomSigStartPos" SG_ 129 BARO_ENG 23;
BA_ "FlexKomSigName" SG_ 129 BARO_ENG "Engine_1_Pkt";
BA_ "FlexKomSigLaenge" SG_ 129 BARO_ENG 48;
BA_ "FlexKomSID" SG_ 129 BARO_ENG 1352;
BA_ "FlexKomIsMotorola" SG_ 129 BARO_ENG 1;
BA_ "FlexKomComment" SG_ 129 BARO_ENG "General engine Data";
BA_ "GenSigSNA" SG_ 343 RefuelEvent "0h";
BA_ "GenSigCycleTime" SG_ 343 RefuelEvent 100;
BA_ "FlexKomSigStartValue" SG_ 343 RefuelEvent "00h";
BA_ "FlexKomSigStartPos" SG_ 343 RefuelEvent 13;
BA_ "FlexKomSigName" SG_ 343 RefuelEvent "RefuelEvent";
BA_ "FlexKomSigLaenge" SG_ 343 RefuelEvent 3;
BA_ "FlexKomSID" SG_ 343 RefuelEvent 2574;
BA_ "FlexKomIsMotorola" SG_ 343 RefuelEvent 1;
BA_ "FlexKomComment" SG_ 343 RefuelEvent "Status of refuel event";
BA_ "GenSigTimeout_IC" SG_ 343 RefuelIndication 1050;
BA_ "GenSigSNA" SG_ 343 RefuelIndication "0h";
BA_ "GenSigCycleTime" SG_ 343 RefuelIndication 100;
BA_ "FlexKomSigStartValue" SG_ 343 RefuelIndication "00h";
BA_ "FlexKomSigStartPos" SG_ 343 RefuelIndication 31;
BA_ "FlexKomSigName" SG_ 343 RefuelIndication "RefuelIndication";
BA_ "FlexKomSigLaenge" SG_ 343 RefuelIndication 3;
BA_ "FlexKomSID" SG_ 343 RefuelIndication 2578;
BA_ "FlexKomIsMotorola" SG_ 343 RefuelIndication 1;
BA_ "FlexKomComment" SG_ 343 RefuelIndication "Indication to the driver about the status of the r";
BA_ "GenSigTimeout_IC" SG_ 343 StarterProtectionTime 1050;
BA_ "GenSigSNA" SG_ 343 StarterProtectionTime "FFh";
BA_ "GenSigCycleTime" SG_ 343 StarterProtectionTime 100;
BA_ "FlexKomSigStartValue" SG_ 343 StarterProtectionTime "00h";
BA_ "FlexKomSigStartPos" SG_ 343 StarterProtectionTime 47;
BA_ "FlexKomSigName" SG_ 343 StarterProtectionTime "StarterProtectionTime";
BA_ "FlexKomSigLaenge" SG_ 343 StarterProtectionTime 8;
BA_ "FlexKomSID" SG_ 343 StarterProtectionTime 2613;
BA_ "FlexKomIsMotorola" SG_ 343 StarterProtectionTime 1;
BA_ "FlexKomComment" SG_ 343 StarterProtectionTime "Starter protection time";
BA_ "GenSigTimeout_TBM" SG_ 633 MntncSts 10500;
BA_ "GenSigTimeout_IC" SG_ 633 MntncSts 10500;
BA_ "GenSigTimeout_ETM" SG_ 633 MntncSts 10500;
BA_ "GenSigSNA" SG_ 633 MntncSts "3h";
BA_ "GenSigCycleTime" SG_ 633 MntncSts 1000;
BA_ "FlexKomSigStartValue" SG_ 633 MntncSts "FFFFFF0FFFh";
BA_ "FlexKomSigStartPos" SG_ 633 MntncSts 7;
BA_ "FlexKomSigName" SG_ 633 MntncSts "OilLifePkt";
BA_ "FlexKomSigLaenge" SG_ 633 MntncSts 40;
BA_ "FlexKomSID" SG_ 633 MntncSts 1668;
BA_ "FlexKomIsMotorola" SG_ 633 MntncSts 1;
BA_ "FlexKomComment" SG_ 633 MntncSts "Oil life packet";
BA_ "GenSigStartValue" SG_ 317 DefFuelEcon 255;
BA_ "GenSigSNA" SG_ 317 DefFuelEcon "FFh";
BA_ "GenSigCycleTime" SG_ 317 DefFuelEcon 100;
BA_ "FlexKomSigStartValue" SG_ 317 DefFuelEcon "FFh";
BA_ "FlexKomSigStartPos" SG_ 317 DefFuelEcon 55;
BA_ "FlexKomSigName" SG_ 317 DefFuelEcon "DefFuelEcon";
BA_ "FlexKomSigLaenge" SG_ 317 DefFuelEcon 8;
BA_ "FlexKomSID" SG_ 317 DefFuelEcon 709;
BA_ "FlexKomIsMotorola" SG_ 317 DefFuelEcon 1;
BA_ "FlexKomComment" SG_ 317 DefFuelEcon "Default fuel economy";
BA_ "GenSigTimeout_IC" SG_ 39 EngTrqMax 105;
BA_ "GenSigStartValue" SG_ 39 EngTrqMax 8191;
BA_ "GenSigSNA" SG_ 39 EngTrqMax "1FFFh";
BA_ "GenSigCycleTime" SG_ 39 EngTrqMax 10;
BA_ "FlexKomSigStartValue" SG_ 39 EngTrqMax "9FFF1FFF1FFF00FFh";
BA_ "FlexKomSigStartPos" SG_ 39 EngTrqMax 7;
BA_ "FlexKomSigName" SG_ 39 EngTrqMax "ECM_ENG_TRQ_Pkt";
BA_ "FlexKomSigLaenge" SG_ 39 EngTrqMax 64;
BA_ "FlexKomSID" SG_ 39 EngTrqMax 1853;
BA_ "FlexKomIsMotorola" SG_ 39 EngTrqMax 1;
BA_ "FlexKomComment" SG_ 39 EngTrqMax "ECM_ENG_TRQ packet";
BA_ "GenSigTimeout_ORC" SG_ 39 ClutchInterLk 35;
BA_ "GenSigTimeout_DTCM" SG_ 39 ClutchInterLk 105;
BA_ "GenSigStartValue" SG_ 39 ClutchInterLk 1;
BA_ "GenSigSNA" SG_ 39 ClutchInterLk "1h";
BA_ "GenSigCycleTime" SG_ 39 ClutchInterLk 10;
BA_ "FlexKomSigStartValue" SG_ 39 ClutchInterLk "9FFF1FFF1FFF00FFh";
BA_ "FlexKomSigStartPos" SG_ 39 ClutchInterLk 7;
BA_ "FlexKomSigName" SG_ 39 ClutchInterLk "ECM_ENG_TRQ_Pkt";
BA_ "FlexKomSigLaenge" SG_ 39 ClutchInterLk 64;
BA_ "FlexKomSID" SG_ 39 ClutchInterLk 1853;
BA_ "FlexKomIsMotorola" SG_ 39 ClutchInterLk 1;
BA_ "FlexKomComment" SG_ 39 ClutchInterLk "ECM_ENG_TRQ packet";
BA_ "GenSigSNA" SG_ 131 BrkIntrvntn_Actv_ESP "0h";
BA_ "GenSigCycleTime" SG_ 131 BrkIntrvntn_Actv_ESP 20;
BA_ "FlexKomSigStartValue" SG_ 131 BrkIntrvntn_Actv_ESP "0F3400C003FF00FFh";
BA_ "FlexKomSigStartPos" SG_ 131 BrkIntrvntn_Actv_ESP 7;
BA_ "FlexKomSigName" SG_ 131 BrkIntrvntn_Actv_ESP "ESP_BRK_STAT";
BA_ "FlexKomSigLaenge" SG_ 131 BrkIntrvntn_Actv_ESP 64;
BA_ "FlexKomIsMotorola" SG_ 131 BrkIntrvntn_Actv_ESP 1;
BA_ "FlexKomComment" SG_ 131 BrkIntrvntn_Actv_ESP "ESP Brake Status Information";
BA_ "RID" SG_ 131 SelSpdSts "1982";
BA_ "GenSigTimeout_ORC" SG_ 131 SelSpdSts 70;
BA_ "GenSigTimeout_IC" SG_ 131 SelSpdSts 210;
BA_ "GenSigTimeout_ETM" SG_ 131 SelSpdSts 210;
BA_ "GenSigTimeout_CBC" SG_ 131 SelSpdSts 210;
BA_ "GenSigStartValue" SG_ 131 SelSpdSts 3;
BA_ "GenSigSNA" SG_ 131 SelSpdSts "3h";
BA_ "GenSigCycleTime" SG_ 131 SelSpdSts 20;
BA_ "FlexKomSigStartValue" SG_ 131 SelSpdSts "0F3400C003FF00FFh";
BA_ "FlexKomSigStartPos" SG_ 131 SelSpdSts 7;
BA_ "FlexKomSigName" SG_ 131 SelSpdSts "ESP_BRK_STAT";
BA_ "FlexKomSigLaenge" SG_ 131 SelSpdSts 64;
BA_ "FlexKomIsMotorola" SG_ 131 SelSpdSts 1;
BA_ "FlexKomComment" SG_ 131 SelSpdSts "ESP Brake Status Information";
BA_ "GenSigTimeout_ORC" SG_ 135 CRC_ESP_A3 70;
BA_ "GenSigStartValue" SG_ 135 CRC_ESP_A3 255;
BA_ "GenSigSNA" SG_ 135 CRC_ESP_A3 "FFh";
BA_ "GenSigCycleTime" SG_ 135 CRC_ESP_A3 20;
BA_ "FlexKomSigStartValue" SG_ 135 CRC_ESP_A3 "7000FFFF00FF00FFh";
BA_ "FlexKomSigStartPos" SG_ 135 CRC_ESP_A3 7;
BA_ "FlexKomSigName" SG_ 135 CRC_ESP_A3 "ESC_data";
BA_ "FlexKomSigLaenge" SG_ 135 CRC_ESP_A3 64;
BA_ "FlexKomSID" SG_ 135 CRC_ESP_A3 1416;
BA_ "FlexKomIsMotorola" SG_ 135 CRC_ESP_A3 1;
BA_ "FlexKomComment" SG_ 135 CRC_ESP_A3 "ESC data";
BA_ "GenSigTimeout_ORC" SG_ 113 EngTrq_Rq_As 70;
BA_ "GenSigSNA" SG_ 113 EngTrq_Rq_As "1FFFh";
BA_ "GenSigCycleTime" SG_ 113 EngTrq_Rq_As 20;
BA_ "FlexKomSigStartValue" SG_ 113 EngTrq_Rq_As "00000000FF0000FFh";
BA_ "FlexKomSigStartPos" SG_ 113 EngTrq_Rq_As 7;
BA_ "FlexKomSigName" SG_ 113 EngTrq_Rq_As "Eng_Trq_Rq";
BA_ "FlexKomSigLaenge" SG_ 113 EngTrq_Rq_As 64;
BA_ "FlexKomSID" SG_ 113 EngTrq_Rq_As 1;
BA_ "FlexKomIsMotorola" SG_ 113 EngTrq_Rq_As 1;
BA_ "FlexKomComment" SG_ 113 EngTrq_Rq_As "Engine torque request from ESC";
BA_ "GenSigTimeout_TBM" SG_ 633 HoursOilLifeRst 10500;
BA_ "GenSigTimeout_IC" SG_ 633 HoursOilLifeRst 10500;
BA_ "GenSigTimeout_ETM" SG_ 633 HoursOilLifeRst 10500;
BA_ "GenSigTimeout_CBC" SG_ 633 HoursOilLifeRst 10500;
BA_ "GenSigStartValue" SG_ 633 HoursOilLifeRst 4095;
BA_ "GenSigSNA" SG_ 633 HoursOilLifeRst "FFFh";
BA_ "GenSigCycleTime" SG_ 633 HoursOilLifeRst 1000;
BA_ "FlexKomSigStartValue" SG_ 633 HoursOilLifeRst "FFFFFF0FFFh";
BA_ "FlexKomSigStartPos" SG_ 633 HoursOilLifeRst 7;
BA_ "FlexKomSigName" SG_ 633 HoursOilLifeRst "OilLifePkt";
BA_ "FlexKomSigLaenge" SG_ 633 HoursOilLifeRst 40;
BA_ "FlexKomSID" SG_ 633 HoursOilLifeRst 1668;
BA_ "FlexKomIsMotorola" SG_ 633 HoursOilLifeRst 1;
BA_ "FlexKomComment" SG_ 633 HoursOilLifeRst "Oil life packet";
BA_ "GenSigSNA" SG_ 295 SysVolt "FFh";
BA_ "GenSigCycleTime" SG_ 295 SysVolt 100;
BA_ "FlexKomSigStartValue" SG_ 295 SysVolt "0000h";
BA_ "FlexKomSigStartPos" SG_ 295 SysVolt 31;
BA_ "FlexKomSigName" SG_ 295 SysVolt "EngVoltPkt";
BA_ "FlexKomSigLaenge" SG_ 295 SysVolt 16;
BA_ "FlexKomSID" SG_ 295 SysVolt 437;
BA_ "FlexKomIsMotorola" SG_ 295 SysVolt 1;
BA_ "FlexKomComment" SG_ 295 SysVolt "Engine voltage packet";
BA_ "GenSigTimeout_CBC" SG_ 295 AM_ECM_Prsnt 1050;
BA_ "GenSigSNA" SG_ 295 AM_ECM_Prsnt "3h";
BA_ "GenSigCycleTime" SG_ 295 AM_ECM_Prsnt 100;
BA_ "FlexKomSigStartValue" SG_ 295 AM_ECM_Prsnt "00h";
BA_ "FlexKomSigStartPos" SG_ 295 AM_ECM_Prsnt 46;
BA_ "FlexKomSigName" SG_ 295 AM_ECM_Prsnt "AM_ECM_Prsnt";
BA_ "FlexKomSigLaenge" SG_ 295 AM_ECM_Prsnt 2;
BA_ "FlexKomSID" SG_ 295 AM_ECM_Prsnt 1941;
BA_ "FlexKomIsMotorola" SG_ 295 AM_ECM_Prsnt 1;
BA_ "FlexKomComment" SG_ 295 AM_ECM_Prsnt "Aftermarket ECM present";
BA_ "RID" SG_ 634 AvgFuelLvl "1196";
BA_ "GenSigTimeout_TBM" SG_ 634 AvgFuelLvl 10500;
BA_ "GenSigTimeout_ETM" SG_ 634 AvgFuelLvl 10500;
BA_ "GenSigTimeout_CBC" SG_ 634 AvgFuelLvl 10500;
BA_ "GenSigStartValue" SG_ 634 AvgFuelLvl 511;
BA_ "GenSigSNA" SG_ 634 AvgFuelLvl "1FFh";
BA_ "GenSigSendType" SG_ 634 AvgFuelLvl 5;
BA_ "GenSigCycleTime" SG_ 634 AvgFuelLvl 1000;
BA_ "FlexKomSigStartValue" SG_ 634 AvgFuelLvl "01FFh";
BA_ "FlexKomSigStartPos" SG_ 634 AvgFuelLvl 7;
BA_ "FlexKomSigName" SG_ 634 AvgFuelLvl "AvgFuelLvl";
BA_ "FlexKomSigLaenge" SG_ 634 AvgFuelLvl 16;
BA_ "FlexKomSID" SG_ 634 AvgFuelLvl 848;
BA_ "FlexKomIsMotorola" SG_ 634 AvgFuelLvl 1;
BA_ "FlexKomComment" SG_ 634 AvgFuelLvl "Average filtered fuel level in liters";
BA_ "GenSigSNA" SG_ 634 OilChgRst "0h";
BA_ "GenSigSendType" SG_ 634 OilChgRst 5;
BA_ "GenSigCycleTime" SG_ 634 OilChgRst 1000;
BA_ "FlexKomSigStartValue" SG_ 634 OilChgRst "00h";
BA_ "FlexKomSigStartPos" SG_ 634 OilChgRst 29;
BA_ "FlexKomSigName" SG_ 634 OilChgRst "OilChgRst";
BA_ "FlexKomSigLaenge" SG_ 634 OilChgRst 1;
BA_ "FlexKomSID" SG_ 634 OilChgRst 1819;
BA_ "FlexKomIsMotorola" SG_ 634 OilChgRst 1;
BA_ "FlexKomComment" SG_ 634 OilChgRst "Oil change reminder reset request";
BA_ "RID" SG_ 621 HTShtOffVlvReq "3066";
BA_ "RID" SG_ 673 SpeedUnit "2000";
BA_ "GenSigSNA" SG_ 673 SpeedUnit "0h";
BA_ "GenSigStartValue" SG_ 129 V_MAX_TM 255;
BA_ "GenSigSNA" SG_ 129 V_MAX_TM "FFh";
BA_ "GenSigCycleTime" SG_ 129 V_MAX_TM 20;
BA_ "FlexKomSigStartValue" SG_ 129 V_MAX_TM "FFh";
BA_ "FlexKomSigStartPos" SG_ 129 V_MAX_TM 15;
BA_ "FlexKomSigName" SG_ 129 V_MAX_TM "V_MAX_TM";
BA_ "FlexKomSigLaenge" SG_ 129 V_MAX_TM 8;
BA_ "FlexKomSID" SG_ 129 V_MAX_TM 1252;
BA_ "FlexKomIsMotorola" SG_ 129 V_MAX_TM 1;
BA_ "FlexKomComment" SG_ 129 V_MAX_TM "Max. or cruise control set speed";
BA_ "GenSigStartValue" SG_ 129 Rel_Thrt_ENG 255;
BA_ "GenSigSNA" SG_ 129 Rel_Thrt_ENG "FFh";
BA_ "GenSigCycleTime" SG_ 129 Rel_Thrt_ENG 20;
BA_ "FlexKomSigStartValue" SG_ 129 Rel_Thrt_ENG "FF00FFFF00FFh";
BA_ "FlexKomSigStartPos" SG_ 129 Rel_Thrt_ENG 23;
BA_ "FlexKomSigName" SG_ 129 Rel_Thrt_ENG "Engine_1_Pkt";
BA_ "FlexKomSigLaenge" SG_ 129 Rel_Thrt_ENG 48;
BA_ "FlexKomSID" SG_ 129 Rel_Thrt_ENG 1352;
BA_ "FlexKomIsMotorola" SG_ 129 Rel_Thrt_ENG 1;
BA_ "FlexKomComment" SG_ 129 Rel_Thrt_ENG "General engine Data";
BA_ "GenSigTimeout_IC" SG_ 129 ECM_WARN 210;
BA_ "GenSigSNA" SG_ 129 ECM_WARN "7h";
BA_ "GenSigCycleTime" SG_ 129 ECM_WARN 20;
BA_ "FlexKomSigStartValue" SG_ 129 ECM_WARN "FF00FFFF00FFh";
BA_ "FlexKomSigStartPos" SG_ 129 ECM_WARN 23;
BA_ "FlexKomSigName" SG_ 129 ECM_WARN "Engine_1_Pkt";
BA_ "FlexKomSigLaenge" SG_ 129 ECM_WARN 48;
BA_ "FlexKomSID" SG_ 129 ECM_WARN 1352;
BA_ "FlexKomIsMotorola" SG_ 129 ECM_WARN 1;
BA_ "FlexKomComment" SG_ 129 ECM_WARN "General engine Data";
BA_ "RID" SG_ 221 HILL_DES_STAT "1141 1293 1929";
BA_ "GenSigTimeout_CBC" SG_ 317 EngOilTemp 1050;
BA_ "GenSigStartValue" SG_ 317 EngOilTemp 255;
BA_ "GenSigSNA" SG_ 317 EngOilTemp "FFh";
BA_ "GenSigCycleTime" SG_ 317 EngOilTemp 100;
BA_ "FlexKomSigStartValue" SG_ 317 EngOilTemp "FFh";
BA_ "FlexKomSigStartPos" SG_ 317 EngOilTemp 31;
BA_ "FlexKomSigName" SG_ 317 EngOilTemp "EngOilTemp";
BA_ "FlexKomSigLaenge" SG_ 317 EngOilTemp 8;
BA_ "FlexKomSID" SG_ 317 EngOilTemp 440;
BA_ "FlexKomIsMotorola" SG_ 317 EngOilTemp 1;
BA_ "FlexKomComment" SG_ 317 EngOilTemp "Oil temperature";
BA_ "GenSigStartValue" SG_ 125 EngTrqMaxCorrFctr 255;
BA_ "GenSigSNA" SG_ 125 EngTrqMaxCorrFctr "FFh";
BA_ "GenSigCycleTime" SG_ 125 EngTrqMaxCorrFctr 20;
BA_ "FlexKomSigStartValue" SG_ 125 EngTrqMaxCorrFctr "FFh";
BA_ "FlexKomSigStartPos" SG_ 125 EngTrqMaxCorrFctr 15;
BA_ "FlexKomSigName" SG_ 125 EngTrqMaxCorrFctr "EngTrqMaxCorrFctr";
BA_ "FlexKomSigLaenge" SG_ 125 EngTrqMaxCorrFctr 8;
BA_ "FlexKomSID" SG_ 125 EngTrqMaxCorrFctr 1242;
BA_ "FlexKomIsMotorola" SG_ 125 EngTrqMaxCorrFctr 1;
BA_ "FlexKomComment" SG_ 125 EngTrqMaxCorrFctr "Factor of reduction from max. torque";
BA_ "GenSigStartValue" SG_ 125 NMOTS 65535;
BA_ "GenSigSNA" SG_ 125 NMOTS "FFFFh";
BA_ "GenSigCycleTime" SG_ 125 NMOTS 20;
BA_ "FlexKomSigStartValue" SG_ 125 NMOTS "FFFFh";
BA_ "FlexKomSigStartPos" SG_ 125 NMOTS 39;
BA_ "FlexKomSigName" SG_ 125 NMOTS "NMOTS";
BA_ "FlexKomSigLaenge" SG_ 125 NMOTS 16;
BA_ "FlexKomSID" SG_ 125 NMOTS 1248;
BA_ "FlexKomIsMotorola" SG_ 125 NMOTS 1;
BA_ "FlexKomComment" SG_ 125 NMOTS "Target idle speed";
BA_ "GenSigTimeout_ORC" SG_ 39 Clutch_Disengg 35;
BA_ "GenSigSNA" SG_ 39 Clutch_Disengg "0h";
BA_ "GenSigCycleTime" SG_ 39 Clutch_Disengg 10;
BA_ "FlexKomSigStartValue" SG_ 39 Clutch_Disengg "9FFF1FFF1FFF00FFh";
BA_ "FlexKomSigStartPos" SG_ 39 Clutch_Disengg 7;
BA_ "FlexKomSigName" SG_ 39 Clutch_Disengg "ECM_ENG_TRQ_Pkt";
BA_ "FlexKomSigLaenge" SG_ 39 Clutch_Disengg 64;
BA_ "FlexKomSID" SG_ 39 Clutch_Disengg 1853;
BA_ "FlexKomIsMotorola" SG_ 39 Clutch_Disengg 1;
BA_ "FlexKomComment" SG_ 39 Clutch_Disengg "ECM_ENG_TRQ packet";
BA_ "GenSigSNA" SG_ 301 PTC_REL3_RQ "0h";
BA_ "GenSigCycleTime" SG_ 301 PTC_REL3_RQ 100;
BA_ "FlexKomSigStartValue" SG_ 301 PTC_REL3_RQ "00h";
BA_ "FlexKomSigStartPos" SG_ 301 PTC_REL3_RQ 23;
BA_ "FlexKomSigName" SG_ 301 PTC_REL3_RQ "PTC_REL_RQ";
BA_ "FlexKomSigLaenge" SG_ 301 PTC_REL3_RQ 3;
BA_ "FlexKomSID" SG_ 301 PTC_REL3_RQ 721;
BA_ "FlexKomIsMotorola" SG_ 301 PTC_REL3_RQ 1;
BA_ "FlexKomComment" SG_ 301 PTC_REL3_RQ "PTC relay requests";
BA_ "RID" SG_ 689 DRV_TEMP_DR_POS "1232";
BA_ "GenSigStartValue" SG_ 689 DRV_TEMP_DR_POS 127;
BA_ "GenSigSNA" SG_ 689 DRV_TEMP_DR_POS "7Fh";
BA_ "GenSigSendType" SG_ 689 DRV_TEMP_DR_POS 5;
BA_ "GenSigCycleTime" SG_ 689 DRV_TEMP_DR_POS 1000;
BA_ "FlexKomSigStartValue" SG_ 689 DRV_TEMP_DR_POS "7F8FFFFF7Fh";
BA_ "FlexKomSigStartPos" SG_ 689 DRV_TEMP_DR_POS 7;
BA_ "FlexKomSigName" SG_ 689 DRV_TEMP_DR_POS "GW_Dev";
BA_ "FlexKomSigLaenge" SG_ 689 DRV_TEMP_DR_POS 40;
BA_ "FlexKomSID" SG_ 689 DRV_TEMP_DR_POS 1445;
BA_ "FlexKomIsMotorola" SG_ 689 DRV_TEMP_DR_POS 1;
BA_ "FlexKomComment" SG_ 689 DRV_TEMP_DR_POS "Temporary development packet - route signals from ";
BA_ "FlexKomIsMotorola" SG_ 289 CARB_PERM 1;
BA_ "FlexKomComment" SG_ 289 CARB_PERM "CARB permanent fault code drive cycle";
BA_ "GenSigSNA" SG_ 289 ENGINE_RESET "0h";
BA_ "GenSigCycleTime" SG_ 289 ENGINE_RESET 100;
BA_ "FlexKomSigStartValue" SG_ 289 ENGINE_RESET "00h";
BA_ "FlexKomSigStartPos" SG_ 289 ENGINE_RESET 10;
BA_ "FlexKomSigName" SG_ 289 ENGINE_RESET "ECM_SKIM_STAT_PKT";
BA_ "FlexKomSigLaenge" SG_ 289 ENGINE_RESET 3;
BA_ "FlexKomSID" SG_ 289 ENGINE_RESET 429;
BA_ "FlexKomIsMotorola" SG_ 289 ENGINE_RESET 1;
BA_ "FlexKomComment" SG_ 289 ENGINE_RESET "ECM Immobilizer Status Packet";
BA_ "GenSigTimeout_IC" SG_ 301 PrcntCplt 1050;
BA_ "GenSigStartValue" SG_ 301 PrcntCplt 15;
BA_ "GenSigSNA" SG_ 301 PrcntCplt "Fh";
BA_ "GenSigCycleTime" SG_ 301 PrcntCplt 100;
BA_ "FlexKomSigStartValue" SG_ 301 PrcntCplt "000Fh";
BA_ "FlexKomSigStartPos" SG_ 301 PrcntCplt 7;
BA_ "FlexKomSigName" SG_ 301 PrcntCplt "DEF_DPF_Pkt";
BA_ "FlexKomSigLaenge" SG_ 301 PrcntCplt 16;
BA_ "FlexKomSID" SG_ 301 PrcntCplt 1726;
BA_ "FlexKomIsMotorola" SG_ 301 PrcntCplt 1;
BA_ "FlexKomComment" SG_ 301 PrcntCplt "Exhaust fuel and particulate filter packet";
BA_ "GenSigTimeout_IC" SG_ 301 Adblue_Stat 1050;
BA_ "GenSigSNA" SG_ 301 Adblue_Stat "3Fh";
BA_ "GenSigCycleTime" SG_ 301 Adblue_Stat 100;
BA_ "FlexKomSigStartValue" SG_ 301 Adblue_Stat "00FF0000h";
BA_ "FlexKomSigStartPos" SG_ 301 Adblue_Stat 39;
BA_ "FlexKomSigName" SG_ 301 Adblue_Stat "AdblueDispRq";
BA_ "FlexKomSigLaenge" SG_ 301 Adblue_Stat 32;
BA_ "FlexKomSID" SG_ 301 Adblue_Stat 1436;
BA_ "FlexKomIsMotorola" SG_ 301 Adblue_Stat 1;
BA_ "FlexKomComment" SG_ 301 Adblue_Stat "Adblue display request";
BA_ "GenSigTimeout_IC" SG_ 315 DriveMdstat 1050;
BA_ "GenSigTimeout_CBC" SG_ 315 DriveMdstat 1050;
BA_ "GenSigSNA" SG_ 315 DriveMdstat "Fh";
BA_ "GenSigCycleTime" SG_ 315 DriveMdstat 100;
BA_ "FlexKomSigStartValue" SG_ 315 DriveMdstat "00000000646400FFh";
BA_ "FlexKomSigStartPos" SG_ 315 DriveMdstat 7;
BA_ "FlexKomSigName" SG_ 315 DriveMdstat "HCP_C1_Pkt";
BA_ "FlexKomSigLaenge" SG_ 315 DriveMdstat 64;
BA_ "FlexKomSID" SG_ 315 DriveMdstat 2374;
BA_ "FlexKomIsMotorola" SG_ 315 DriveMdstat 1;
BA_ "FlexKomComment" SG_ 315 DriveMdstat "HCP_C1_Pkt message packet";
BA_ "GenSigStartValue" SG_ 315 CRC_HCP_C1 255;
BA_ "GenSigSNA" SG_ 315 CRC_HCP_C1 "FFh";
BA_ "GenSigCycleTime" SG_ 315 CRC_HCP_C1 100;
BA_ "FlexKomSigStartValue" SG_ 315 CRC_HCP_C1 "00000000646400FFh";
BA_ "FlexKomSigStartPos" SG_ 315 CRC_HCP_C1 7;
BA_ "FlexKomSigName" SG_ 315 CRC_HCP_C1 "HCP_C1_Pkt";
BA_ "FlexKomSigLaenge" SG_ 315 CRC_HCP_C1 64;
BA_ "FlexKomSID" SG_ 315 CRC_HCP_C1 2374;
BA_ "FlexKomIsMotorola" SG_ 315 CRC_HCP_C1 1;
BA_ "FlexKomComment" SG_ 315 CRC_HCP_C1 "HCP_C1_Pkt message packet";
BA_ "RID" SG_ 621 ElecCoolantHtrPwr "5018";
BA_ "RID" SG_ 137 VehAccel_X "1277";
BA_ "GenSigTimeout_ORC" SG_ 137 VehAccel_X 70;
BA_ "GenSigTimeout_IC" SG_ 137 VehAccel_X 210;
BA_ "GenSigTimeout_CBC" SG_ 137 VehAccel_X 210;
BA_ "GenSigStartValue" SG_ 137 VehAccel_X 255;
BA_ "GenSigSNA" SG_ 113 EngTrqMax_Rq_ESC "0h";
BA_ "GenSigCycleTime" SG_ 113 EngTrqMax_Rq_ESC 20;
BA_ "FlexKomSigStartValue" SG_ 113 EngTrqMax_Rq_ESC "00000000FF0000FFh";
BA_ "FlexKomSigStartPos" SG_ 113 EngTrqMax_Rq_ESC 7;
BA_ "FlexKomSigName" SG_ 113 EngTrqMax_Rq_ESC "Eng_Trq_Rq";
BA_ "FlexKomSigLaenge" SG_ 113 EngTrqMax_Rq_ESC 64;
BA_ "FlexKomSID" SG_ 113 EngTrqMax_Rq_ESC 1;
BA_ "FlexKomIsMotorola" SG_ 113 EngTrqMax_Rq_ESC 1;
BA_ "FlexKomComment" SG_ 113 EngTrqMax_Rq_ESC "Engine torque request from ESC";
BA_ "GenSigSNA" SG_ 113 EngTrqMax_Rq_AS "0h";
BA_ "GenSigCycleTime" SG_ 113 EngTrqMax_Rq_AS 20;
BA_ "FlexKomSigStartValue" SG_ 113 EngTrqMax_Rq_AS "00000000FF0000FFh";
BA_ "FlexKomSigStartPos" SG_ 113 EngTrqMax_Rq_AS 7;
BA_ "FlexKomSigName" SG_ 113 EngTrqMax_Rq_AS "Eng_Trq_Rq";
BA_ "FlexKomSigLaenge" SG_ 113 EngTrqMax_Rq_AS 64;
BA_ "FlexKomSID" SG_ 113 EngTrqMax_Rq_AS 1;
BA_ "FlexKomIsMotorola" SG_ 113 EngTrqMax_Rq_AS 1;
BA_ "FlexKomComment" SG_ 113 EngTrqMax_Rq_AS "Engine torque request from ESC";
BA_ "GenSigSNA" SG_ 113 DsblFuelShutOff "0h";
BA_ "RID" SG_ 649 HVAC_CLNT_FLW_MIN "2885";
BA_ "GenSigStartValue" SG_ 649 HVAC_CLNT_FLW_MIN 255;
BA_ "GenSigSNA" SG_ 649 HVAC_CLNT_FLW_MIN "FFh";
BA_ "GenSigSendType" SG_ 649 HVAC_CLNT_FLW_MIN 5;
BA_ "GenSigCycleTime" SG_ 649 HVAC_CLNT_FLW_MIN 1000;
BA_ "FlexKomSigStartValue" SG_ 649 HVAC_CLNT_FLW_MIN "FFh";
BA_ "FlexKomSigStartPos" SG_ 649 HVAC_CLNT_FLW_MIN 47;
BA_ "FlexKomSigName" SG_ 649 HVAC_CLNT_FLW_MIN "HVAC_CLNT_FLW_MIN";
BA_ "FlexKomSigLaenge" SG_ 649 HVAC_CLNT_FLW_MIN 8;
BA_ "FlexKomSID" SG_ 649 HVAC_CLNT_FLW_MIN 1527;
BA_ "FlexKomIsMotorola" SG_ 649 HVAC_CLNT_FLW_MIN 1;
BA_ "FlexKomComment" SG_ 649 HVAC_CLNT_FLW_MIN "HVAC coolant flow minimum request";
BA_ "GenSigSNA" SG_ 327 MIL_OnRq_ESC "0h";
BA_ "GenSigCycleTime" SG_ 327 MIL_OnRq_ESC 100;
BA_ "FlexKomSigStartValue" SG_ 327 MIL_OnRq_ESC "00h";
BA_ "FlexKomSigStartPos" SG_ 327 MIL_OnRq_ESC 2;
BA_ "FlexKomSigName" SG_ 327 MIL_OnRq_ESC "MIL_OnRq_ESC";
BA_ "FlexKomSigLaenge" SG_ 327 MIL_OnRq_ESC 1;
BA_ "FlexKomSID" SG_ 327 MIL_OnRq_ESC 2375;
BA_ "FlexKomIsMotorola" SG_ 327 MIL_OnRq_ESC 1;
BA_ "FlexKomComment" SG_ 327 MIL_OnRq_ESC "MIL on request from the ESC";
BA_ "GenSigSNA" SG_ 289 EngLoad_OBD "0h";
BA_ "GenSigCycleTime" SG_ 289 EngLoad_OBD 100;
BA_ "FlexKomSigStartValue" SG_ 289 EngLoad_OBD "00h";
BA_ "FlexKomSigStartPos" SG_ 289 EngLoad_OBD 23;
BA_ "FlexKomSigName" SG_ 289 EngLoad_OBD "EngLoad_OBD";
BA_ "FlexKomSigLaenge" SG_ 289 EngLoad_OBD 8;
BA_ "FlexKomSID" SG_ 289 EngLoad_OBD 1088;
BA_ "FlexKomIsMotorola" SG_ 289 EngLoad_OBD 1;
BA_ "FlexKomComment" SG_ 289 EngLoad_OBD "Load value for OBD (ISO 15031-5.4 PID 4)";
BA_ "GenSigTimeout_TBM" SG_ 129 MAP_ENG 210;
BA_ "GenSigTimeout_ETM" SG_ 129 MAP_ENG 1010;
BA_ "GenSigStartValue" SG_ 129 MAP_ENG 255;
BA_ "GenSigSNA" SG_ 129 MAP_ENG "FFh";
BA_ "GenSigCycleTime" SG_ 129 MAP_ENG 20;
BA_ "FlexKomSigStartValue" SG_ 129 MAP_ENG "FF00FFFF00FFh";
BA_ "FlexKomSigStartPos" SG_ 129 MAP_ENG 23;
BA_ "FlexKomSigName" SG_ 129 MAP_ENG "Engine_1_Pkt";
BA_ "FlexKomSigLaenge" SG_ 129 MAP_ENG 48;
BA_ "FlexKomSID" SG_ 129 MAP_ENG 1352;
BA_ "FlexKomIsMotorola" SG_ 129 MAP_ENG 1;
BA_ "FlexKomComment" SG_ 129 MAP_ENG "General engine Data";
BA_ "GenSigStartValue" SG_ 129 Rel_Pdl_ENG 255;
BA_ "GenSigSNA" SG_ 129 Rel_Pdl_ENG "FFh";
BA_ "GenSigCycleTime" SG_ 129 Rel_Pdl_ENG 20;
BA_ "FlexKomSigStartValue" SG_ 129 Rel_Pdl_ENG "FF00FFFF00FFh";
BA_ "FlexKomSigStartPos" SG_ 129 Rel_Pdl_ENG 23;
BA_ "FlexKomSigName" SG_ 129 Rel_Pdl_ENG "Engine_1_Pkt";
BA_ "FlexKomSigLaenge" SG_ 129 Rel_Pdl_ENG 48;
BA_ "FlexKomSID" SG_ 129 Rel_Pdl_ENG 1352;
BA_ "FlexKomIsMotorola" SG_ 129 Rel_Pdl_ENG 1;
BA_ "FlexKomComment" SG_ 129 Rel_Pdl_ENG "General engine Data";
BA_ "GenSigTimeout_IC" SG_ 343 StartProtectionInhibit 1050;
BA_ "GenSigSNA" SG_ 343 StartProtectionInhibit "3h";
BA_ "GenSigCycleTime" SG_ 343 StartProtectionInhibit 100;
BA_ "FlexKomSigStartValue" SG_ 343 StartProtectionInhibit "00h";
BA_ "FlexKomSigStartPos" SG_ 343 StartProtectionInhibit 25;
BA_ "FlexKomSigName" SG_ 343 StartProtectionInhibit "StartProtectionInhibit";
BA_ "FlexKomSigLaenge" SG_ 343 StartProtectionInhibit 2;
BA_ "FlexKomSID" SG_ 343 StartProtectionInhibit 2612;
BA_ "FlexKomIsMotorola" SG_ 343 StartProtectionInhibit 1;
BA_ "FlexKomComment" SG_ 343 StartProtectionInhibit "Starter protection status";
BA_ "GenSigSNA" SG_ 347 QualifyDriveCycle "0h";
BA_ "GenSigCycleTime" SG_ 347 QualifyDriveCycle 100;
BA_ "FlexKomSigStartValue" SG_ 347 QualifyDriveCycle "0000000000000000h";
BA_ "FlexKomSigStartPos" SG_ 347 QualifyDriveCycle 7;
BA_ "FlexKomSigName" SG_ 347 QualifyDriveCycle "Engine_Status5";
BA_ "FlexKomSigLaenge" SG_ 347 QualifyDriveCycle 64;
BA_ "FlexKomSID" SG_ 347 QualifyDriveCycle 2130708633;
BA_ "FlexKomIsMotorola" SG_ 347 QualifyDriveCycle 1;
BA_ "FlexKomComment" SG_ 347 QualifyDriveCycle ".";
BA_ "FlexKomSigStartPos" SG_ 301 PTC_REL2_RQ 23;
BA_ "FlexKomSigName" SG_ 301 PTC_REL2_RQ "PTC_REL_RQ";
BA_ "FlexKomSigLaenge" SG_ 301 PTC_REL2_RQ 3;
BA_ "FlexKomSID" SG_ 301 PTC_REL2_RQ 721;
BA_ "FlexKomIsMotorola" SG_ 301 PTC_REL2_RQ 1;
BA_ "FlexKomComment" SG_ 301 PTC_REL2_RQ "PTC relay requests";
BA_ "GenSigSNA" SG_ 611 HtrCoreInletTemp "FFh";
BA_ "GenSigSendType" SG_ 611 HtrCoreInletTemp 5;
BA_ "GenSigCycleTime" SG_ 611 HtrCoreInletTemp 1000;
BA_ "FlexKomSigStartValue" SG_ 611 HtrCoreInletTemp "0000000000000000h";
BA_ "FlexKomSigStartPos" SG_ 611 HtrCoreInletTemp 7;
BA_ "FlexKomSigName" SG_ 611 HtrCoreInletTemp "HCP_1000";
BA_ "FlexKomSigLaenge" SG_ 611 HtrCoreInletTemp 64;
BA_ "FlexKomSID" SG_ 611 HtrCoreInletTemp 2373;
BA_ "FlexKomIsMotorola" SG_ 611 HtrCoreInletTemp 1;
BA_ "FlexKomComment" SG_ 611 HtrCoreInletTemp "HCP 1000ms packet";
BA_ "GenSigTimeout_CBC" SG_ 131 BrkPdl_Stat 510;
BA_ "GenSigStartValue" SG_ 131 BrkPdl_Stat 3;
BA_ "GenSigSNA" SG_ 131 BrkPdl_Stat "3h";
BA_ "GenSigCycleTime" SG_ 131 BrkPdl_Stat 20;
BA_ "FlexKomSigStartValue" SG_ 131 BrkPdl_Stat "0F3400C003FF00FFh";
BA_ "FlexKomSigStartPos" SG_ 131 BrkPdl_Stat 7;
BA_ "FlexKomSigName" SG_ 131 BrkPdl_Stat "ESP_BRK_STAT";
BA_ "FlexKomSigLaenge" SG_ 131 BrkPdl_Stat 64;
BA_ "FlexKomIsMotorola" SG_ 131 BrkPdl_Stat 1;
BA_ "FlexKomComment" SG_ 131 BrkPdl_Stat "ESP Brake Status Information";
BA_ "RID" SG_ 689 FT_HVAC_BLW_FN_SP "1070";
BA_ "GenSigTimeout_IC" SG_ 689 FT_HVAC_BLW_FN_SP 10500;
BA_ "GenSigStartValue" SG_ 689 FT_HVAC_BLW_FN_SP 127;
BA_ "GenSigSNA" SG_ 689 FT_HVAC_BLW_FN_SP "7Fh";
BA_ "GenSigSendType" SG_ 689 FT_HVAC_BLW_FN_SP 5;
BA_ "GenSigCycleTime" SG_ 689 FT_HVAC_BLW_FN_SP 1000;
BA_ "FlexKomSigStartValue" SG_ 689 FT_HVAC_BLW_FN_SP "7F8FFFFF7Fh";
BA_ "FlexKomSigStartPos" SG_ 689 FT_HVAC_BLW_FN_SP 7;
BA_ "FlexKomSigName" SG_ 689 FT_HVAC_BLW_FN_SP "GW_Dev";
BA_ "FlexKomSigLaenge" SG_ 689 FT_HVAC_BLW_FN_SP 40;
BA_ "FlexKomSID" SG_ 689 FT_HVAC_BLW_FN_SP 1445;
BA_ "FlexKomIsMotorola" SG_ 689 FT_HVAC_BLW_FN_SP 1;
BA_ "FlexKomComment" SG_ 689 FT_HVAC_BLW_FN_SP "Temporary development packet - route signals from ";
BA_ "RID" SG_ 221 LT_DIST "1233";
BA_ "GenSigTimeout_PTS" SG_ 221 LT_DIST 525;
BA_ "GenSigTimeout_IC" SG_ 221 LT_DIST 525;
BA_ "GenSigTimeout_CBC" SG_ 221 LT_DIST 525;
BA_ "GenSigStartValue" SG_ 221 LT_DIST 65535;
BA_ "GenSigSNA" SG_ 221 LT_DIST "FFFFh";
BA_ "GenSigCycleTime" SG_ 221 LT_DIST 50;
BA_ "FlexKomSigStartValue" SG_ 221 LT_DIST "FFFFFFFFh";
BA_ "FlexKomSigStartPos" SG_ 221 LT_DIST 7;
BA_ "FlexKomSigName" SG_ 221 LT_DIST "ESP_DIST";
BA_ "FlexKomSigLaenge" SG_ 221 LT_DIST 32;
BA_ "FlexKomSID" SG_ 221 LT_DIST 395;
BA_ "GenSigSNA" SG_ 289 IgnCntrTrue "0h";
BA_ "GenSigCycleTime" SG_ 289 IgnCntrTrue 100;
BA_ "FlexKomSigStartValue" SG_ 289 IgnCntrTrue "00h";
BA_ "FlexKomSigStartPos" SG_ 289 IgnCntrTrue 6;
BA_ "FlexKomSigName" SG_ 289 IgnCntrTrue "IgnCntrTrue";
BA_ "FlexKomSigLaenge" SG_ 289 IgnCntrTrue 1;
BA_ "FlexKomSID" SG_ 289 IgnCntrTrue 1255;
BA_ "FlexKomIsMotorola" SG_ 289 IgnCntrTrue 1;
BA_ "FlexKomComment" SG_ 289 IgnCntrTrue "Ignition cycle counter is true [1]";
BA_ "GenSigTimeout_TBM" SG_ 289 AccelPdlPosn_OBD 1050;
BA_ "GenSigStartValue" SG_ 135 BrkBstrVac_OBD 255;
BA_ "GenSigSNA" SG_ 135 BrkBstrVac_OBD "FFh";
BA_ "GenSigCycleTime" SG_ 135 BrkBstrVac_OBD 20;
BA_ "FlexKomSigStartValue" SG_ 135 BrkBstrVac_OBD "7000FFFF00FF00FFh";
BA_ "FlexKomSigStartPos" SG_ 135 BrkBstrVac_OBD 7;
BA_ "FlexKomSigName" SG_ 135 BrkBstrVac_OBD "ESC_data";
BA_ "FlexKomSigLaenge" SG_ 135 BrkBstrVac_OBD 64;
BA_ "FlexKomSID" SG_ 135 BrkBstrVac_OBD 1416;
BA_ "FlexKomIsMotorola" SG_ 135 BrkBstrVac_OBD 1;
BA_ "FlexKomComment" SG_ 135 BrkBstrVac_OBD "ESC data";
BA_ "GenSigStartValue" SG_ 113 CRC_ENG_RQ_ESC 255;
BA_ "GenSigSNA" SG_ 113 CRC_ENG_RQ_ESC "FFh";
BA_ "GenSigCycleTime" SG_ 113 CRC_ENG_RQ_ESC 20;
BA_ "FlexKomSigStartValue" SG_ 113 CRC_ENG_RQ_ESC "00000000FF0000FFh";
BA_ "FlexKomSigStartPos" SG_ 113 CRC_ENG_RQ_ESC 7;
BA_ "FlexKomSigName" SG_ 113 CRC_ENG_RQ_ESC "Eng_Trq_Rq";
BA_ "FlexKomSigLaenge" SG_ 113 CRC_ENG_RQ_ESC 64;
BA_ "FlexKomSID" SG_ 113 CRC_ENG_RQ_ESC 1;
BA_ "FlexKomIsMotorola" SG_ 113 CRC_ENG_RQ_ESC 1;
BA_ "FlexKomComment" SG_ 113 CRC_ENG_RQ_ESC "Engine torque request from ESC";
BA_ "RID" SG_ 131 BrkPdl_Stat "1135";
BA_ "GenSigTimeout_TCM" SG_ 131 BrkPdl_Stat 210;
BA_ "GenSigTimeout_ORC" SG_ 131 BrkPdl_Stat 70;
BA_ "GenSigTimeout_IC" SG_ 131 BrkPdl_Stat 210;
BA_ "GenSigTimeout_ETM" SG_ 131 BrkPdl_Stat 210;
BA_ "GenSigTimeout_ESM" SG_ 131 BrkPdl_Stat 210;
BA_ "GenSigTimeout_DTCM" SG_ 131 BrkPdl_Stat 210;
BA_ "RID" SG_ 295 EngCoolTemp "1130";
BA_ "GenSigTimeout_TCM" SG_ 295 EngCoolTemp 1050;
BA_ "GenSigTimeout_TBM" SG_ 295 EngCoolTemp 1050;
BA_ "GenSigTimeout_IC" SG_ 295 EngCoolTemp 1050;
BA_ "GenSigTimeout_CBC" SG_ 295 EngCoolTemp 1050;
BA_ "GenSigStartValue" SG_ 295 EngCoolTemp 255;
BA_ "GenSigSNA" SG_ 295 EngCoolTemp "FFh";
BA_ "GenSigCycleTime" SG_ 295 EngCoolTemp 100;
BA_ "FlexKomSigStartValue" SG_ 295 EngCoolTemp "FFh";
BA_ "FlexKomSigStartPos" SG_ 295 EngCoolTemp 15;
BA_ "FlexKomSigName" SG_ 295 EngCoolTemp "EngCoolTemp";
BA_ "FlexKomSigLaenge" SG_ 295 EngCoolTemp 8;
BA_ "FlexKomSID" SG_ 295 EngCoolTemp 711;
BA_ "FlexKomIsMotorola" SG_ 295 EngCoolTemp 1;
BA_ "FlexKomComment" SG_ 295 EngCoolTemp "Engine coolant temperature";
BA_ "RID" SG_ 295 R134a_Press_Stat "1167";
BA_ "GenSigSNA" SG_ 131 ShftChrDsp_Rq_ESC "Fh";
BA_ "GenSigCycleTime" SG_ 131 ShftChrDsp_Rq_ESC 20;
BA_ "FlexKomSigStartValue" SG_ 131 ShftChrDsp_Rq_ESC "0F3400C003FF00FFh";
BA_ "FlexKomSigStartPos" SG_ 131 ShftChrDsp_Rq_ESC 7;
BA_ "FlexKomSigName" SG_ 131 ShftChrDsp_Rq_ESC "ESP_BRK_STAT";
BA_ "FlexKomSigLaenge" SG_ 131 ShftChrDsp_Rq_ESC 64;
BA_ "FlexKomIsMotorola" SG_ 131 ShftChrDsp_Rq_ESC 1;
BA_ "FlexKomComment" SG_ 131 ShftChrDsp_Rq_ESC "ESP Brake Status Information";
BA_ "GenSigTimeout_ORC" SG_ 131 DTR_CC_Engaged 70;
BA_ "GenSigSNA" SG_ 131 DTR_CC_Engaged "0h";
BA_ "GenSigCycleTime" SG_ 131 DTR_CC_Engaged 20;
BA_ "FlexKomSigStartValue" SG_ 131 DTR_CC_Engaged "0F3400C003FF00FFh";
BA_ "FlexKomSigStartPos" SG_ 131 DTR_CC_Engaged 7;
BA_ "FlexKomSigName" SG_ 131 DTR_CC_Engaged "ESP_BRK_STAT";
BA_ "FlexKomSigLaenge" SG_ 131 DTR_CC_Engaged 64;
BA_ "FlexKomIsMotorola" SG_ 131 DTR_CC_Engaged 1;
BA_ "FlexKomComment" SG_ 131 DTR_CC_Engaged "ESP Brake Status Information";
BA_ "GenSigSNA" SG_ 289 CARB_Temp "0h";
BA_ "GenSigCycleTime" SG_ 289 CARB_Temp 100;
BA_ "FlexKomSigStartValue" SG_ 289 CARB_Temp "00h";
BA_ "FlexKomSigName" SG_ 289 CARB_Temp "CARB_Temp";
BA_ "FlexKomSigLaenge" SG_ 289 CARB_Temp 1;
BA_ "FlexKomSID" SG_ 289 CARB_Temp 1261;
BA_ "FlexKomIsMotorola" SG_ 289 CARB_Temp 1;
BA_ "FlexKomComment" SG_ 289 CARB_Temp "CARB warmup criteria is true [1]";
BA_ "GenSigSNA" SG_ 289 CARB_PERM "0h";
BA_ "GenSigCycleTime" SG_ 289 CARB_PERM 100;
BA_ "FlexKomSigStartValue" SG_ 289 CARB_PERM "00h";
BA_ "FlexKomSigStartPos" SG_ 289 CARB_PERM 3;
BA_ "FlexKomSigName" SG_ 289 CARB_PERM "CARB_PERM";
BA_ "FlexKomSigLaenge" SG_ 289 CARB_PERM 1;
BA_ "FlexKomSID" SG_ 289 CARB_PERM 1258;
BA_ "FlexKomSID" SG_ 611 ChargingSysSts 2373;
BA_ "FlexKomIsMotorola" SG_ 611 ChargingSysSts 1;
BA_ "FlexKomComment" SG_ 611 ChargingSysSts "HCP 1000ms packet";
BA_ "RID" SG_ 131 BrkPdl_Flt "5033";
BA_ "GenSigSNA" SG_ 131 BrkPdl_Flt "0h";
BA_ "GenSigCycleTime" SG_ 131 BrkPdl_Flt 20;
BA_ "FlexKomSigStartValue" SG_ 131 BrkPdl_Flt "0F3400C003FF00FFh";
BA_ "FlexKomSigStartPos" SG_ 131 BrkPdl_Flt 7;
BA_ "FlexKomSigName" SG_ 131 BrkPdl_Flt "ESP_BRK_STAT";
BA_ "FlexKomSigLaenge" SG_ 131 BrkPdl_Flt 64;
BA_ "FlexKomIsMotorola" SG_ 131 BrkPdl_Flt 1;
BA_ "FlexKomComment" SG_ 131 BrkPdl_Flt "ESP Brake Status Information";
BA_ "GenSigTimeout_ORC" SG_ 131 BrkIntrvntn_Enbl 70;
BA_ "GenSigSNA" SG_ 131 BrkIntrvntn_Enbl "0h";
BA_ "GenSigCycleTime" SG_ 131 BrkIntrvntn_Enbl 20;
BA_ "FlexKomSigStartValue" SG_ 131 BrkIntrvntn_Enbl "0F3400C003FF00FFh";
BA_ "FlexKomSigStartPos" SG_ 131 BrkIntrvntn_Enbl 7;
BA_ "FlexKomSigName" SG_ 131 BrkIntrvntn_Enbl "ESP_BRK_STAT";
BA_ "FlexKomSigLaenge" SG_ 131 BrkIntrvntn_Enbl 64;
BA_ "FlexKomIsMotorola" SG_ 131 BrkIntrvntn_Enbl 1;
BA_ "FlexKomComment" SG_ 131 BrkIntrvntn_Enbl "ESP Brake Status Information";
BA_ "GenSigSNA" SG_ 43 LatAcceleration "FFFh";
BA_ "GenSigCycleTime" SG_ 43 LatAcceleration 10;
BA_ "FlexKomSigStartValue" SG_ 43 LatAcceleration "000000000FFF00FFh";
BA_ "FlexKomSigStartPos" SG_ 43 LatAcceleration 7;
BA_ "FlexKomSigName" SG_ 43 LatAcceleration "ORC_YRS_PKT";
BA_ "FlexKomSigLaenge" SG_ 43 LatAcceleration 64;
BA_ "FlexKomSID" SG_ 43 LatAcceleration 1587;
BA_ "FlexKomIsMotorola" SG_ 43 LatAcceleration 1;
BA_ "FlexKomComment" SG_ 43 LatAcceleration "Accelerometer data packet";
BA_ "GenSigTimeout_ETM" SG_ 289 RAD_FAN1_STAT 1050;
BA_ "GenSigSNA" SG_ 343 LeakTestSts "0h";
BA_ "GenSigCycleTime" SG_ 343 LeakTestSts 100;
BA_ "FlexKomSigStartValue" SG_ 343 LeakTestSts "00h";
BA_ "FlexKomSigStartPos" SG_ 343 LeakTestSts 28;
BA_ "FlexKomSigName" SG_ 343 LeakTestSts "LeakTestSts";
BA_ "FlexKomSigLaenge" SG_ 343 LeakTestSts 2;
BA_ "FlexKomSID" SG_ 343 LeakTestSts 2576;
BA_ "FlexKomIsMotorola" SG_ 343 LeakTestSts 1;
BA_ "FlexKomComment" SG_ 343 LeakTestSts "Status of leak test";
BA_ "GenSigSNA" SG_ 347 AWD_LOW "0h";
BA_ "GenSigCycleTime" SG_ 347 AWD_LOW 100;
BA_ "FlexKomSigStartValue" SG_ 347 AWD_LOW "00h";
BA_ "FlexKomSigStartPos" SG_ 347 AWD_LOW 7;
BA_ "FlexKomSigName" SG_ 347 AWD_LOW "AWD_LOW";
BA_ "FlexKomSigLaenge" SG_ 347 AWD_LOW 1;
BA_ "FlexKomSID" SG_ 347 AWD_LOW 2977;
BA_ "FlexKomIsMotorola" SG_ 347 AWD_LOW 1;
BA_ "FlexKomComment" SG_ 347 AWD_LOW "AWD LOW status; 0 4LOW_Not_Active 1 4LOW_Active";
BA_ "GenSigSNA" SG_ 347 HighPressureFuelSystemFailure "0h";
BA_ "GenSigCycleTime" SG_ 347 HighPressureFuelSystemFailure 100;
BA_ "FlexKomSigStartValue" SG_ 347 HighPressureFuelSystemFailure "00h";
BA_ "FlexKomSigStartPos" SG_ 347 HighPressureFuelSystemFailure 42;
BA_ "FlexKomSigName" SG_ 347 HighPressureFuelSystemFailure "HighPressureFuelSystemFailure";
BA_ "FlexKomSigLaenge" SG_ 347 HighPressureFuelSystemFailure 1;
BA_ "FlexKomSID" SG_ 347 HighPressureFuelSystemFailure 3099;
BA_ "FlexKomIsMotorola" SG_ 347 HighPressureFuelSystemFailure 1;
BA_ "FlexKomComment" SG_ 347 HighPressureFuelSystemFailure "HighPressureFuelSystemFailure";
BA_ "GenSigTimeout_IC" SG_ 633 DisOilLifeRst 10500;
BA_ "GenSigTimeout_ETM" SG_ 633 DisOilLifeRst 10500;
BA_ "GenSigTimeout_CBC" SG_ 633 DisOilLifeRst 10500;
BA_ "GenSigStartValue" SG_ 633 DisOilLifeRst 65535;
BA_ "GenSigSNA" SG_ 633 DisOilLifeRst "FFFFh";
BA_ "GenSigCycleTime" SG_ 633 DisOilLifeRst 1000;
BA_ "FlexKomSigStartValue" SG_ 633 DisOilLifeRst "FFFFFF0FFFh";
BA_ "FlexKomSigStartPos" SG_ 633 DisOilLifeRst 7;
BA_ "FlexKomSigName" SG_ 633 DisOilLifeRst "OilLifePkt";
BA_ "FlexKomSigLaenge" SG_ 633 DisOilLifeRst 40;
BA_ "FlexKomSID" SG_ 633 DisOilLifeRst 1668;
BA_ "FlexKomIsMotorola" SG_ 633 DisOilLifeRst 1;
BA_ "FlexKomComment" SG_ 633 DisOilLifeRst "Oil life packet";
BA_ "RID" SG_ 633 OilLifeLeftRst "1619";
BA_ "GenSigTimeout_TBM" SG_ 633 OilLifeLeftRst 10500;
BA_ "GenSigSNA" SG_ 41 PropulsionMode "7h";
BA_ "GenSigCycleTime" SG_ 634 ODO 1000;
BA_ "FlexKomSigStartValue" SG_ 634 ODO "FFFFFFh";
BA_ "FlexKomSigStartPos" SG_ 634 ODO 39;
BA_ "FlexKomSigName" SG_ 634 ODO "ODO";
BA_ "FlexKomSigLaenge" SG_ 634 ODO 24;
BA_ "FlexKomSID" SG_ 634 ODO 804;
BA_ "FlexKomIsMotorola" SG_ 634 ODO 1;
BA_ "FlexKomComment" SG_ 634 ODO "Odometer";
BA_ "GenSigTimeout_ETM" SG_ 503 xtended_AvgFuelLvl 5250;
BA_ "GenSigTimeout_CBC" SG_ 503 xtended_AvgFuelLvl 5250;
BA_ "GenSigStartValue" SG_ 503 xtended_AvgFuelLvl 4095;
BA_ "GenSigSNA" SG_ 503 xtended_AvgFuelLvl "FFFh";
BA_ "GenSigCycleTime" SG_ 503 xtended_AvgFuelLvl 500;
BA_ "FlexKomSigStartValue" SG_ 503 xtended_AvgFuelLvl "0FFFh";
BA_ "FlexKomSigStartPos" SG_ 503 xtended_AvgFuelLvl 23;
BA_ "FlexKomSigName" SG_ 503 xtended_AvgFuelLvl "xtended_AvgFuelLvl";
BA_ "FlexKomSigLaenge" SG_ 503 xtended_AvgFuelLvl 16;
BA_ "FlexKomSID" SG_ 503 xtended_AvgFuelLvl 2440;
BA_ "FlexKomIsMotorola" SG_ 503 xtended_AvgFuelLvl 1;
BA_ "FlexKomComment" SG_ 503 xtended_AvgFuelLvl "Epanded average filtered fuel level in liters";
BA_ "RID" SG_ 221 RT_DIST "1113";
BA_ "GenSigTimeout_PTS" SG_ 221 RT_DIST 525;
BA_ "GenSigTimeout_IC" SG_ 221 RT_DIST 525;
BA_ "GenSigTimeout_CBC" SG_ 221 RT_DIST 525;
BA_ "GenSigStartValue" SG_ 221 RT_DIST 65535;
BA_ "GenSigSNA" SG_ 221 RT_DIST "FFFFh";
BA_ "GenSigCycleTime" SG_ 221 RT_DIST 50;
BA_ "FlexKomSigStartValue" SG_ 221 RT_DIST "FFFFFFFFh";
BA_ "FlexKomSigStartPos" SG_ 221 RT_DIST 7;
BA_ "FlexKomSigName" SG_ 221 RT_DIST "ESP_DIST";
BA_ "FlexKomSigLaenge" SG_ 221 RT_DIST 32;
BA_ "FlexKomSID" SG_ 221 RT_DIST 395;
BA_ "FlexKomIsMotorola" SG_ 221 RT_DIST 1;
BA_ "FlexKomComment" SG_ 221 RT_DIST "Distance traveled by wheels";
BA_ "RID" SG_ 221 ESP_DSBL "1649 1674";
BA_ "GenSigTimeout_ORC" SG_ 221 ESP_DSBL 175;
BA_ "GenSigTimeout_IC" SG_ 221 ESP_DSBL 525;
BA_ "GenSigTimeout_ETM" SG_ 221 ESP_DSBL 525;
BA_ "GenSigSNA" SG_ 221 ESP_DSBL "0h";
BA_ "GenSigCycleTime" SG_ 221 ESP_DSBL 50;
BA_ "FlexKomSigStartValue" SG_ 221 ESP_DSBL "003Fh";
BA_ "FlexKomSigStartPos" SG_ 221 ESP_DSBL 55;
BA_ "FlexKomSigName" SG_ 221 ESP_DSBL "ESP_HMI";
BA_ "FlexKomSigLaenge" SG_ 221 ESP_DSBL 16;
BA_ "FlexKomSID" SG_ 221 ESP_DSBL 397;
BA_ "FlexKomIsMotorola" SG_ 221 ESP_DSBL 1;
BA_ "FlexKomComment" SG_ 221 ESP_DSBL "ESP Customer Indicators";
BA_ "GenSigCycleTime" SG_ 137 VehAccel_Y 20;
BA_ "FlexKomSigStartValue" SG_ 137 VehAccel_Y "FFh";
BA_ "FlexKomSigStartPos" SG_ 137 VehAccel_Y 47;
BA_ "FlexKomSigName" SG_ 137 VehAccel_Y "VehAccel_Y";
BA_ "FlexKomSigLaenge" SG_ 137 VehAccel_Y 8;
BA_ "FlexKomSID" SG_ 137 VehAccel_Y 1266;
BA_ "FlexKomIsMotorola" SG_ 137 VehAccel_Y 1;
BA_ "FlexKomComment" SG_ 137 VehAccel_Y "Vehicle lateral acceleration (+ means left, specif";
BA_ "GenSigTimeout_TBM" SG_ 633 OilLifeLeft 10500;
BA_ "GenSigTimeout_IC" SG_ 633 OilLifeLeft 10500;
BA_ "GenSigTimeout_ETM" SG_ 633 OilLifeLeft 10500;
BA_ "GenSigStartValue" SG_ 633 OilLifeLeft 255;
BA_ "GenSigSNA" SG_ 633 OilLifeLeft "FFh";
BA_ "GenSigCycleTime" SG_ 633 OilLifeLeft 1000;
BA_ "FlexKomSigStartValue" SG_ 633 OilLifeLeft "FFFFFF0FFFh";
BA_ "FlexKomSigStartPos" SG_ 633 OilLifeLeft 7;
BA_ "FlexKomSigName" SG_ 633 OilLifeLeft "OilLifePkt";
BA_ "FlexKomSigLaenge" SG_ 633 OilLifeLeft 40;
BA_ "FlexKomSID" SG_ 633 OilLifeLeft 1668;
BA_ "FlexKomIsMotorola" SG_ 633 OilLifeLeft 1;
BA_ "FlexKomComment" SG_ 633 OilLifeLeft "Oil life packet";
BA_ "RID" SG_ 317 OIL_TEMP_IND_RQ "6551";
BA_ "GenSigTimeout_TBM" SG_ 317 OIL_TEMP_IND_RQ 1050;
BA_ "GenSigTimeout_IC" SG_ 317 OIL_TEMP_IND_RQ 1050;
BA_ "GenSigTimeout_ETM" SG_ 317 OIL_TEMP_IND_RQ 1050;
BA_ "GenSigSNA" SG_ 317 OIL_TEMP_IND_RQ "3h";
BA_ "GenSigCycleTime" SG_ 317 OIL_TEMP_IND_RQ 100;
BA_ "FlexKomSigStartValue" SG_ 317 OIL_TEMP_IND_RQ "00h";
BA_ "FlexKomSigStartPos" SG_ 317 OIL_TEMP_IND_RQ 14;
BA_ "FlexKomSigName" SG_ 317 OIL_TEMP_IND_RQ "OIL_TEMP_RQ";
BA_ "FlexKomSigLaenge" SG_ 317 OIL_TEMP_IND_RQ 4;
BA_ "FlexKomSID" SG_ 317 OIL_TEMP_IND_RQ 718;
BA_ "FlexKomIsMotorola" SG_ 317 OIL_TEMP_IND_RQ 1;
BA_ "FlexKomComment" SG_ 317 OIL_TEMP_IND_RQ "Engine oil overtemp. indicator/chime request";
BA_ "RID" SG_ 317 ChkFuelCap "6545";
BA_ "GenSigTimeout_TBM" SG_ 317 ChkFuelCap 1050;
BA_ "GenSigTimeout_IC" SG_ 317 ChkFuelCap 1050;
BA_ "GenSigTimeout_ETM" SG_ 317 ChkFuelCap 1050;
BA_ "GenSigSNA" SG_ 317 ChkFuelCap "0h";
BA_ "GenSigCycleTime" SG_ 317 ChkFuelCap 100;
BA_ "FlexKomSigStartValue" SG_ 317 ChkFuelCap "00h";
BA_ "FlexKomSigStartPos" SG_ 317 ChkFuelCap 15;
BA_ "FlexKomSigName" SG_ 317 ChkFuelCap "ChkFuelCap";
BA_ "FlexKomSigLaenge" SG_ 317 ChkFuelCap 1;
BA_ "FlexKomSID" SG_ 317 ChkFuelCap 1082;
BA_ "FlexKomIsMotorola" SG_ 317 ChkFuelCap 1;
BA_ "FlexKomComment" SG_ 317 ChkFuelCap "Check fuel cap";
BA_ "RID" SG_ 317 FuelCons "1818";
BA_ "GenSigTimeout_IC" SG_ 317 FuelCons 1050;
BA_ "GenSigTimeout_CBC" SG_ 317 FuelCons 1050;
BA_ "GenSigStartValue" SG_ 317 FuelCons 65535;
BA_ "GenSigSNA" SG_ 317 FuelCons "FFFFh";
BA_ "GenSigCycleTime" SG_ 317 FuelCons 100;
BA_ "FlexKomSigStartValue" SG_ 317 FuelCons "FFFFh";
BA_ "FlexKomSigStartPos" SG_ 317 FuelCons 39;
BA_ "FlexKomSigName" SG_ 317 FuelCons "FuelCons";
BA_ "FlexKomSigLaenge" SG_ 317 FuelCons 16;
BA_ "FlexKomSID" SG_ 317 FuelCons 443;
BA_ "FlexKomIsMotorola" SG_ 317 FuelCons 1;
BA_ "FlexKomComment" SG_ 317 FuelCons "Fuel consumption";
BA_ "GenSigSNA" SG_ 125 KickDnSw_Psd "0h";
BA_ "GenSigCycleTime" SG_ 125 KickDnSw_Psd 20;
BA_ "FlexKomSigStartValue" SG_ 125 KickDnSw_Psd "00h";
BA_ "FlexKomSigStartPos" SG_ 125 KickDnSw_Psd 3;
BA_ "FlexKomSigName" SG_ 125 KickDnSw_Psd "KickDnSw_Psd";
BA_ "FlexKomSigLaenge" SG_ 125 KickDnSw_Psd 1;
BA_ "FlexKomSID" SG_ 125 KickDnSw_Psd 1238;
BA_ "FlexKomIsMotorola" SG_ 125 KickDnSw_Psd 1;
BA_ "FlexKomComment" SG_ 125 KickDnSw_Psd "kick-down (change-over scenario open!)";
BA_ "GenSigSNA" SG_ 125 GrMin_Rq_ECM "0h";
BA_ "GenSigCycleTime" SG_ 125 GrMin_Rq_ECM 20;
BA_ "FlexKomSigStartValue" SG_ 125 GrMin_Rq_ECM "00h";
BA_ "FlexKomSigStartPos" SG_ 125 GrMin_Rq_ECM 21;
BA_ "FlexKomSigName" SG_ 125 GrMin_Rq_ECM "ECM_Gear";
BA_ "FlexKomSigLaenge" SG_ 125 GrMin_Rq_ECM 6;
BA_ "FlexKomSID" SG_ 125 GrMin_Rq_ECM 1243;
BA_ "FlexKomIsMotorola" SG_ 125 GrMin_Rq_ECM 1;
BA_ "FlexKomComment" SG_ 125 GrMin_Rq_ECM "Target gear upper and lower limit";
BA_ "GenSigSNA" SG_ 131 SPCR_AS_Off_Rq "0h";
BA_ "GenSigCycleTime" SG_ 131 SPCR_AS_Off_Rq 20;
BA_ "FlexKomSigStartValue" SG_ 131 SPCR_AS_Off_Rq "0F3400C003FF00FFh";
BA_ "FlexKomSigStartPos" SG_ 131 SPCR_AS_Off_Rq 7;
BA_ "FlexKomSigName" SG_ 131 SPCR_AS_Off_Rq "ESP_BRK_STAT";
BA_ "FlexKomSigLaenge" SG_ 131 SPCR_AS_Off_Rq 64;
BA_ "FlexKomIsMotorola" SG_ 131 SPCR_AS_Off_Rq 1;
BA_ "FlexKomComment" SG_ 131 SPCR_AS_Off_Rq "ESP Brake Status Information";
BA_ "GenSigSNA" SG_ 131 DTR_CC_Enabled "0h";
BA_ "GenSigCycleTime" SG_ 131 DTR_CC_Enabled 20;
BA_ "FlexKomSigStartValue" SG_ 131 DTR_CC_Enabled "0F3400C003FF00FFh";
BA_ "FlexKomSigStartPos" SG_ 131 DTR_CC_Enabled 7;
BA_ "FlexKomSigName" SG_ 131 DTR_CC_Enabled "ESP_BRK_STAT";
BA_ "FlexKomSigLaenge" SG_ 131 DTR_CC_Enabled 64;
BA_ "FlexKomIsMotorola" SG_ 131 DTR_CC_Enabled 1;
BA_ "FlexKomComment" SG_ 131 DTR_CC_Enabled "ESP Brake Status Information";
BA_ "GenSigTimeout_DTCM" SG_ 131 RollTestMd_Actv 210;
BA_ "GenSigStartValue" SG_ 131 RollTestMd_Actv 3;
BA_ "GenSigSNA" SG_ 131 RollTestMd_Actv "3h";
BA_ "GenSigCycleTime" SG_ 131 RollTestMd_Actv 20;
BA_ "FlexKomSigStartValue" SG_ 131 RollTestMd_Actv "0F3400C003FF00FFh";
BA_ "FlexKomSigStartPos" SG_ 131 RollTestMd_Actv 7;
BA_ "FlexKomSigName" SG_ 131 RollTestMd_Actv "ESP_BRK_STAT";
BA_ "FlexKomSigLaenge" SG_ 131 RollTestMd_Actv 64;
BA_ "FlexKomIsMotorola" SG_ 131 RollTestMd_Actv 1;
BA_ "FlexKomComment" SG_ 131 RollTestMd_Actv "ESP Brake Status Information";
BA_ "GenSigTimeout_TBM" SG_ 131 ESP_Sys_Stat 210;
BA_ "GenSigTimeout_ORC" SG_ 131 ESP_Sys_Stat 70;
BA_ "GenSigTimeout_IC" SG_ 131 ESP_Sys_Stat 210;
BA_ "GenSigTimeout_DTCM" SG_ 131 ESP_Sys_Stat 210;
BA_ "GenSigStartValue" SG_ 131 ESP_Sys_Stat 1;
BA_ "GenSigSNA" SG_ 131 ESP_Sys_Stat "1h";
BA_ "GenSigCycleTime" SG_ 131 ESP_Sys_Stat 20;
BA_ "FlexKomSigStartValue" SG_ 131 ESP_Sys_Stat "0F3400C003FF00FFh";
BA_ "FlexKomSigStartPos" SG_ 131 ESP_Sys_Stat 7;
BA_ "FlexKomSigName" SG_ 131 ESP_Sys_Stat "ESP_BRK_STAT";
BA_ "FlexKomSigLaenge" SG_ 131 ESP_Sys_Stat 64;
BA_ "FlexKomIsMotorola" SG_ 131 ESP_Sys_Stat 1;
BA_ "FlexKomComment" SG_ 131 ESP_Sys_Stat "ESP Brake Status Information";
BA_ "GenSigSNA" SG_ 289 Inp_GD_Fail "0h";
BA_ "GenSigCycleTime" SG_ 289 Inp_GD_Fail 100;
BA_ "FlexKomSigStartValue" SG_ 289 Inp_GD_Fail "00h";
BA_ "FlexKomSigStartPos" SG_ 289 Inp_GD_Fail 1;
BA_ "FlexKomSigName" SG_ 289 Inp_GD_Fail "Inp_GD_Fail";
BA_ "FlexKomSigLaenge" SG_ 289 Inp_GD_Fail 1;
BA_ "FlexKomSID" SG_ 289 Inp_GD_Fail 1260;
BA_ "FlexKomIsMotorola" SG_ 289 Inp_GD_Fail 1;
BA_ "FlexKomComment" SG_ 289 Inp_GD_Fail "Inputs to the general denominator are in a pend or";
BA_ "GenSigSNA" SG_ 315 MC_HCP_C1 "0h";
BA_ "GenSigCycleTime" SG_ 315 MC_HCP_C1 100;
BA_ "FlexKomSigStartValue" SG_ 315 MC_HCP_C1 "00000000646400FFh";
BA_ "FlexKomSigStartPos" SG_ 315 MC_HCP_C1 7;
BA_ "FlexKomSigName" SG_ 315 MC_HCP_C1 "HCP_C1_Pkt";
BA_ "FlexKomSigLaenge" SG_ 315 MC_HCP_C1 64;
BA_ "FlexKomSID" SG_ 315 MC_HCP_C1 2374;
BA_ "FlexKomIsMotorola" SG_ 315 MC_HCP_C1 1;
BA_ "FlexKomComment" SG_ 315 MC_HCP_C1 "HCP_C1_Pkt message packet";
BA_ "RID" SG_ 137 VehYawRate_Offset "1299 1710 5037";
BA_ "GenSigTimeout_ORC" SG_ 137 VehYawRate_Offset 70;
BA_ "GenSigTimeout_IC" SG_ 137 VehYawRate_Offset 210;
BA_ "GenSigTimeout_ETM" SG_ 137 VehYawRate_Offset 210;
BA_ "GenSigTimeout_CBC" SG_ 137 VehYawRate_Offset 210;
BA_ "GenSigStartValue" SG_ 137 VehYawRate_Offset 255;
BA_ "GenSigSNA" SG_ 137 VehYawRate_Offset "FFh";
BA_ "GenSigCycleTime" SG_ 137 VehYawRate_Offset 20;
BA_ "FlexKomSigStartValue" SG_ 137 VehYawRate_Offset "FFh";
BA_ "FlexKomSigStartPos" SG_ 137 VehYawRate_Offset 23;
BA_ "FlexKomSigName" SG_ 137 VehYawRate_Offset "VehYawRate_Offset";
BA_ "FlexKomSigLaenge" SG_ 137 VehYawRate_Offset 8;
BA_ "FlexKomSID" SG_ 137 VehYawRate_Offset 1263;
BA_ "FlexKomIsMotorola" SG_ 137 VehYawRate_Offset 1;
BA_ "FlexKomComment" SG_ 137 VehYawRate_Offset "Offset of vehicle yaw rate unfiltered/unadjusted (";
BA_ "RID" SG_ 137 VehAccel_Y "1137";
BA_ "GenSigTimeout_ORC" SG_ 137 VehAccel_Y 70;
BA_ "GenSigTimeout_IC" SG_ 137 VehAccel_Y 210;
VAL_ 289 RAD_FAN1_STAT 255 "SNA";
VAL_ 113 EngTrq_Rq_ESC 8191 "SNA";
VAL_ 113 EngTrq_Rq_As 8191 "SNA";
VAL_ 113 BrkBstrVac 255 "SNA";
VAL_ 39 EngTrqMax 8191 "SNA";
VAL_ 39 EngTrqMin 8191 "SNA";
VAL_ 39 StartRelayBCMCmd 0 "SNA";
VAL_ 121 BrkTrq 4095 "SNA";
VAL_ 121 BrkTrq_D 4095 "SNA";
VAL_ 121 VEH_SPEED 65535 "SNA";
VAL_ 125 EngTrqMaxCorrFctr 255 "SNA";
VAL_ 125 GrMin_Rq_ECM 0 "PASSIVE" 1 "G1" 2 "G2" 3 "G3" 4 "G4" 5 "G5" 6 "G6" 7 "G7";
VAL_ 125 GrMax_Rq_ECM 0 "PASSIVE" 1 "G1" 2 "G2" 3 "G3" 4 "G4" 5 "G5" 6 "G6" 7 "G7";
VAL_ 125 NMOTS 65535 "SNA";
VAL_ 129 CRUISE_EGD 0 "SNA";
VAL_ 129 CRUISE_ON 0 "SNA";
VAL_ 129 V_MAX_TM 255 "SNA";
VAL_ 129 MAP_ENG 255 "SNA";
VAL_ 129 BARO_ENG 255 "SNA";
VAL_ 129 Rel_Thrt_ENG 255 "SNA";
VAL_ 129 Rel_Pdl_ENG 255 "SNA";
VAL_ 131 Brk_Stat 0 "IDLE" 1 "BRAKING" 2 "NDEF2" 3 "SNA";
VAL_ 131 BrkPdl_Stat 0 "UPSTOP" 1 "PSD" 2 "NDEF2" 3 "SNA";
VAL_ 131 ESP_Sys_Stat 0 "ABSERR" 1 "NORM" 2 "HALF" 3 "ABGAS";
VAL_ 131 DTR_CC_Engaged 0 "SNA";
VAL_ 131 DTR_CC_Enabled 0 "SNA";
VAL_ 131 ShftChrDsp_Rq_ESC 0 "SKL0" 1 "SKL1" 2 "SKL2" 3 "SKL3" 4 "SKL4" 5 "SKL5" 6 "SKL6" 7 "SKL7" 8 "SKL8" 9 "SKL9" 10 "SKL10" 11 "SKL11" 12 "SKL12" 15 "SNA";
VAL_ 131 RollTestMd_Actv 0 "OFF" 1 "ON" 2 "NDEF2" 3 "SNA";
VAL_ 131 SPCR_AS_Off_Rq 0 "IDLE" 1 "AS_TMP_OFF" 2 "AS_CNTS_OFF" 3 "SPCR_NA";
VAL_ 135 BrkPrss_TMC 2047 "SNA";
VAL_ 135 HSA_BrkPrss 63 "SNA";
VAL_ 137 VehYawRate_Raw 65535 "SNA";
VAL_ 137 VehYawRate_Offset 255 "SNA";
VAL_ 137 VehAccel_X_Offset 255 "SNA";
VAL_ 137 VehAccel_X 255 "SNA";
VAL_ 137 VehAccel_Y 255 "SNA";
VAL_ 137 VehAccel_Y_Offset 255 "SNA";
VAL_ 139 WhlRPM_FL 16383 "SNA";
VAL_ 139 WhlRPM_FR 16383 "SNA";
VAL_ 139 WhlRPM_RL 16383 "SNA";
VAL_ 139 WhlRPM_RR 16383 "SNA";
VAL_ 295 IntkAirTemp 255 "SNA";
VAL_ 295 EngCoolTemp 255 "SNA";
VAL_ 295 AirPress_Outsd 255 "SNA";
VAL_ 295 SysVolt 255 "SNA";
VAL_ 295 R134a_Press_Stat 511 "SNA";
VAL_ 295 CHRG_FAIL 1 "SNA";
VAL_ 295 AM_ECM_Prsnt 0 "DEFAULT" 2 "AM_ECM_PRSNT" 3 "SNA";
VAL_ 311 CC_SetSpdDspl 255 "SNA";
VAL_ 311 EVPmpStat 0 "OFF" 1 "ON" 2 "FAULT" 3 "SNA";
VAL_ 311 CC_SetSpdDsplMPH 255 "SNA";
VAL_ 317 ETC_IND_LMP 0 "OFF" 1 "ON" 2 "ON_Flashing" 3 "SNA";
VAL_ 317 EngOilIndLmp_On_Rq 1 "SNA";
VAL_ 317 OIL_TEMP_IND_RQ 0 "IND_LMP_OFF" 1 "IND_LMP_ON" 2 "IND_LMP_FLASH" 3 "SNA";
VAL_ 317 OIL_TEMP_CHM_RQ 0 "NO_CHM" 1 "1_CHM" 2 "SLOW_CHM" 3 "FAST_CHM";
VAL_ 317 OIL_PRESS 255 "SNA";
VAL_ 317 EngOilTemp 255 "SNA";
VAL_ 317 FuelCons 65535 "SNA";
VAL_ 317 DefFuelEcon 255 "SNA";
VAL_ 317 EngRun_Stat 0 "STOP" 1 "START" 2 "IDLE_UNSTBL" 3 "IDLE_STBL" 4 "UNLIMITED" 5 "LIMITED" 6 "NDEF6" 7 "SNA";
VAL_ 221 LT_DIST 65535 "SNA";
VAL_ 221 RT_DIST 65535 "SNA";
VAL_ 221 HILL_DES_STAT 0 "HDC_UNAVL" 1 "HDC_ACT" 2 "HDC_AVL" 3 "HDC_THRML_DEACT";
VAL_ 221 ABS_IndLmp_On_Rq 0 "OFF" 1 "CONT" 2 "BLINK" 3 "SNA";
VAL_ 334 RawPVS1 255 "SNA";
VAL_ 334 RawPVS2 255 "SNA";
VAL_ 334 RawTPS1 255 "SNA";
VAL_ 334 RawTPS2 255 "SNA";
VAL_ 334 RelativePdl 255 "SNA";
VAL_ 334 RelativeThrt 255 "SNA";
VAL_ 334 MAP 255 "SNA";
VAL_ 633 DisOilLifeRst 65535 "SNA";
VAL_ 633 OilLifeLeft 255 "SNA";
VAL_ 633 MntncSts 0 "NONE" 1 "SOON" 2 "NOW" 3 "SNA";
VAL_ 634 AvgFuelLvl 511 "SNA";
VAL_ 634 ODO 16777215 "SNA";
VAL_ 689 FT_HVAC_BLW_FN_SP 127 "SNA";
VAL_ 689 DRV_TEMP_DR_POS 127 "SNA";
VAL_ 311 EconShftRq 0 "NONE" 1 "UP" 2 "DOWN" 3 "SNA";
VAL_ 633 HoursOilLifeRst 4095 "SNA";
VAL_ 131 SelSpdSts 0 "OFF" 1 "SELECT" 2 "INHIBIT" 3 "SNA";
VAL_ 301 Adblue_FL_LVL 255 "SNA";
VAL_ 301 Adblue_Stat 0 "OK" 1 "DEFLW1" 2 "DEFLW2" 3 "DEFLW3" 4 "DEFLW4" 5 "DEFLW5" 6 "DEFLW6" 7 "DEFLW7" 8 "DEFLW8" 9 "DEFLW9" 10 "DEFLW10" 11 "DEFLW11" 12 "DEFLW12" 13 "DEFLW13" 14 "DEFLW14" 15 "DEFLW15" 16 "DEFQW1" 17 "DEFQW2" 18 "DEFQW3" 19 "DEFQW4" 20 "DEFQW5" 21 "DEFQW6" 22 "DEFQW7" 23 "DEFQW8" 24 "DEFQW9" 25 "DEFQW10" 33 "DEFLW1_RL" 34 "DEFLW2_RL" 35 "DEFLW3_RL" 36 "DEFLW4_RL" 37 "DEFLW5_RL" 38 "DEFLW6_RL" 39 "DEFLW7_RL" 40 "DEFLW8_RL" 41 "DEFLW9_RL" 42 "DEFLW10_RL" 43 "DEFLW11_RL" 44 "DEFLW12_RL" 45 "DEFLW13_RL" 46 "DEFLW14_RL" 47 "DEFLW15_RL" 48 "DEFQW1_RL" 49 "DEFQW2_RL" 50 "DEFQW3_RL" 51 "DEFQW4_RL" 52 "DEFQW5_RL" 53 "DEFQW6_RL" 54 "DEFQW7_RL" 55 "DEFQW8_RL" 56 "DEFQW9_RL" 57 "DEFQW10_RL" 63 "SNA";
VAL_ 301 DEF_LOW 0 "OFF" 1 "CONT" 2 "BLINK" 3 "SNA";
VAL_ 301 PFW_Stat 0 "PFW_MN" 1 "RegRqPFW_Stat" 2 "SerRqPFW_Stat" 3 "SER_REQ" 4 "REG_CMPL" 5 "RegActPFW_Stat" 6 "PWR_RED" 9 "RegRqPFW_StatRL" 10 "SerRqPFW_StatRL" 11 "SER_REQ_RL" 12 "REG_CMPL_RL" 13 "RegActPFW_StatRL" 14 "PWR_RED_RL" 15 "SNA";
VAL_ 301 PrcntCplt 15 "SNA";
VAL_ 311 SpStDispstat 0 "NONE" 1 "STARTING" 2 "START" 3 "ACTIVE" 4 "D_OR_SB" 5 "NR_DRV_NOT_DET" 6 "DR_INHIB" 7 "TX_INHIB" 8 "KEY" 9 "BATT" 10 "SYSFLT" 11 "NR" 12 "READY" 13 "OFF" 14 "HOOD" 15 "PEDAL" 16 "BATT_CHG" 17 "TM" 18 "T4WD_L" 19 "LF" 20 "INCLINE" 21 "AMB_TEMP" 22 "ENG_TEMP" 23 "SB" 24 "DR_AJAR" 25 "CABIN" 26 "MAX_HVAC" 27 "FT_DEFROST" 28 "EBL" 29 "ST_WHEEL" 30 "Eng_Temp_Hi" 31 "Eng_Temp_Lo" 32 "Prk_Brk_Inhib" 33 "Park_Inhib" 34 "Hood_Inhib" 35 "DPF_Regen" 36 "PSG_DR_INHIB" 37 "ACC_SET" 38 "BATT_HIGH" 39 "OFF_ROAD1" 40 "OFF_ROAD2" 63 "SNA";
VAL_ 311 SpStSwStat 0 "OFF" 1 "CONT" 2 "BLINK" 3 "SNA";
VAL_ 311 SpStWarnStat 0 "NONE" 1 "PCR_Opens" 2 "START" 3 "ACTIVE" 4 "D_OR_SB" 5 "NR_DRV_NOT_DET" 6 "DR_INHIB" 7 "TX_INHIB" 8 "KEY" 9 "BATT" 10 "SYSFLT" 11 "Prk_Brk_Inhib" 12 "Hood_Inhib" 13 "PSG_DR_INHIB" 14 "Park_Inhib" 15 "SNA";
VAL_ 649 HVAC_CLNT_FLW_MIN 0 "OPEN" 254 "CLOSE" 255 "SNA";
VAL_ 663 SpSt_Pad1 0 "UN_PSD" 1 "PSD" 2 "S_GND" 3 "S_PLUS" 4 "IND" 7 "SNA";
VAL_ 663 SpSt_Pad2 0 "UN_PSD" 1 "PSD" 2 "S_GND" 3 "S_PLUS" 4 "IND" 7 "SNA";
VAL_ 347 RevOilLifeRst 65535 "SNA";
VAL_ 43 LatAcceleration 4095 "SNA";
VAL_ 43 LongAcceleration 4095 "SNA";
VAL_ 611 HtrCoreInletTemp 255 "SNA";
VAL_ 611 ChargingSysSts 0 "NotCharging" 1 "Charging" 2 "ChargeInterrupted" 3 "ChargeComplete" 7 "SNA";
VAL_ 621 HTAuxPmpRPMAct 255 "SNA";
VAL_ 621 HTAuxPmpMontrngRPM 0 "TRUE" 1 "FALSE" 3 "SNA";
VAL_ 621 ElecCoolantHtrPwr 255 "SNA";
VAL_ 621 ElecClntHtrInletTemp 255 "SNA";
VAL_ 343 RefuelEvent 0 "NONE" 1 "PEND" 2 "TRUE" 3 "COMP" 4 "FAULT";
VAL_ 343 LeakTestSts 0 "NONE" 1 "PEND" 2 "COMPLETE" 3 "DELAY";
VAL_ 343 RefuelIndication 0 "NONE" 1 "WAIT" 2 "PARK" 3 "OK" 4 "DOOR" 5 "BLOCKAGE" 6 "SERVICE";
VAL_ 343 LeakCheckTimerValue 511 "SNA";
VAL_ 503 xtended_AvgFuelLvl 4095 "SNA";
VAL_ 129 SpeedLimitSts 0 "S_B" 1 "ACT" 2 "N_A" 3 "OVER" 4 "OVER_SPEED" 5 "DEACTIVATED" 6 "OFF" 7 "SNA";
VAL_ 129 ECM_WARN 0 "None" 1 "WARN_1" 2 "WARN_2" 3 "WARN_3" 4 "WARN_4" 5 "WARN_5" 6 "WARN_6" 7 "SNA";
VAL_ 343 StartProtectionInhibit 0 "Default" 2 "Crank_Inhibit" 3 "SNA";
VAL_ 343 StarterProtectionTime 255 "SNA";
VAL_ 343 SAMInfo 0 "SAMOFF" 1 "Engine_OFF" 2 "Cranking_management" 3 "ColdEngineManagement" 4 "PassiveBoost" 5 "Steady_State" 6 "RegenerativeBraking" 7 "QuickCharge" 8 "Auto_Shut_OFF" 9 "Shut_OFF" 10 "SAM_recovery" 11 "Battery_Regeneration" 15 "SNA";
VAL_ 676 MAP_4_Bar 511 "SNA";
VAL_ 676 ECM_WARN_EXT 0 "NONE" 1 "WARN_EXT_1" 2 "WARN_EXT_2" 3 "WARN_EXT_3" 4 "WARN_EXT_4" 5 "WARN_EXT_5" 6 "WARN_EXT_6" 7 "WARN_EXT_7" 8 "WARN_EXT_8" 9 "WARN_EXT_9" 10 "WARN_EXT_10" 12 "WARN_EXT_12" 13 "WARN_EXT_13" 14 "WARN_EXT_14" 15 "WARN_EXT_15" 16 "WARN_EXT_16" 17 "WARN_EXT_17" 18 "WARN_EXT_18" 19 "WARN_EXT_19" 20 "WARN_EXT_20" 21 "WARN_EXT_21" 22 "WARN_EXT_22" 23 "WARN_EXT_23" 24 "WARN_EXT_24" 25 "WARN_EXT_25";
VAL_ 676 TransWarmup_Min_RPM 255 "SNA";
VAL_ 315 DriveMdstat 0 "Drive_Mode_Unavailable" 1 "Hybrid" 2 "Sport" 4 "ESave" 8 "Electric" 15 "SNA";
VAL_ 41 PropulsionMode 0 "Hybrid_Parallel" 1 "EV_Only" 2 "Hybrid_Series" 7 "SNA";
VAL_ 347 QualifyDriveCycle 0 "not_realized" 1 "realized";
SIG_GROUP_ 41 HCP_Torq_Status_Pkt 1 : MC_123h CRC_123h REPRGD_PFC_CLR_HCP PropulsionMode;
SIG_GROUP_ 315 HCP_C1_Pkt 1 : MIL_OnRq_HCP DriveMdstat CRC_HCP_C1 MC_HCP_C1;
SIG_GROUP_ 611 HCP_1000_Pkt 1 : PrplsnSysAtv HtrCoreInletTemp ChargingSysSts;
SIG_GROUP_ 121 ESP_A8_Pkt 1 : BrkTrq BrkTrq_D VEH_SPEED MC_VEH_SPEED CRC_VEH_SPEED;
SIG_GROUP_ 137 ESP_A4_Pkt 1 : VehYawRate_Raw VehYawRate_Offset VehAccel_X_Offset VehAccel_X VehAccel_Y MC_VEH_DYN_STAT VehAccel_Y_Offset;
SIG_GROUP_ 135 ESP_A3_Pkt 1 : BrkPrss_TMC HSA_BrkPrss BrkBstrVac_OBD MC_ESP_A3 CRC_ESP_A3;
SIG_GROUP_ 113 ESP_A2_Pkt 1 : EngTrq_Rq_ESC EngTrqMax_Rq_ESC EngTrqMin_Rq_ESC EngTrq_Rq_As EngTrqMax_Rq_AS BrkBstrVac DsblFuelShutOff MC_ENG_RQ_ESC CRC_ENG_RQ_ESC;
SIG_GROUP_ 131 ESP_A1_Pkt 1 : Brk_Stat BrkPdl_Stat BrkPdl_Flt BrkIntrvntn_Actv_ESP BrkIntrvntn_Enbl ESP_Sys_Stat DTR_CC_Engaged DTR_CC_Enabled Brk_Thermdl ShftChrDsp_Rq_ESC RollTestMd_Actv SPCR_AS_Off_Rq MC_Brk_Stat CRC_Brk_Stat SelSpdSts;
SIG_GROUP_ 676 ECM_B11_Pkt 1 : MAP_4_Bar ECM_WARN_EXT TransWarmup_Min_RPM TransWarmup_Enbl_Rq MC_ECM_B11 CRC_ECM_B11;
